VERSION ""

NS_ :

BS_:

BU_: AHLM ASBS CBC DIAGNOST DPDM DTCM ECM EHPS ESC ESL ESM ETM GPF HCP IC IRCM OCM ORC PTS RF_HUB SCCM SGW TBM TCM TPM

BO_ 943 IC_TripData_6: 8 IC
 SG_ B_Total_Dist_Kilometers : 47|24@0+ (0.1,0) [0|16093.3] "km"  ETM,SGW,TBM
 SG_ B_Total_Dist_Miles : 23|24@0+ (0.1,0) [0|9999.9] "Mile"  ETM,SGW,TBM

BO_ 958 IC_TripData_7: 8 IC
 SG_ Electric_Dist_Miles : 1|10@0+ (1,0) [0|999] "Mile"  CBC,ETM,SGW,TBM
 SG_ Hybrid_Dist_Miles : 17|10@0+ (1,0) [0|999] "Mile"  CBC,ETM,SGW,TBM

BO_ 959 IC_TripData_8: 8 IC
 SG_ Electric_Dist_Kilometers : 1|10@0+ (1,0) [0|999] "km"  CBC,ETM,SGW,TBM
 SG_ Hybrid_Dist_Kilometers : 17|10@0+ (1,0) [0|999] "km"  CBC,ETM,SGW,TBM

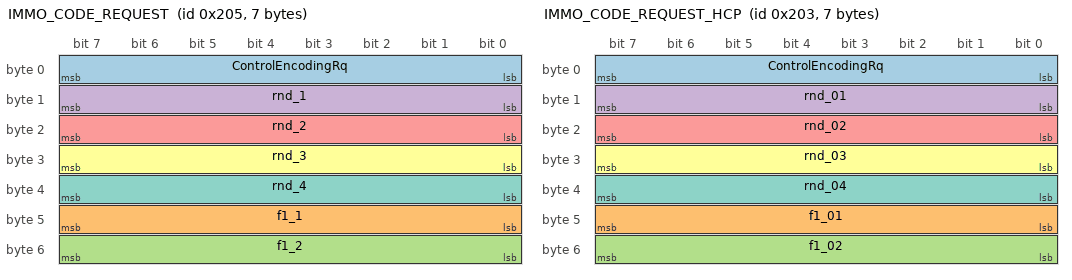
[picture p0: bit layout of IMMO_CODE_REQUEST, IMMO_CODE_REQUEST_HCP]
BO_ 517 IMMO_CODE_REQUEST: 7 ECM
 SG_ ControlEncodingRq : 0|8@1+ (1,0) [0|0] ""  CBC,SGW
 SG_ f1_1 : 40|8@1+ (1,0) [0|255] ""  CBC,SGW
 SG_ f1_2 : 48|8@1+ (1,0) [0|255] ""  CBC,SGW
 SG_ rnd_1 : 8|8@1+ (1,0) [0|255] ""  CBC,SGW
 SG_ rnd_2 : 16|8@1+ (1,0) [0|255] ""  CBC,SGW
 SG_ rnd_3 : 24|8@1+ (1,0) [0|255] ""  CBC,SGW
 SG_ rnd_4 : 32|8@1+ (1,0) [0|255] ""  CBC,SGW

BO_ 515 IMMO_CODE_REQUEST_HCP: 7 HCP
 SG_ ControlEncodingRq : 0|8@1+ (1,0) [0|0] ""  CBC,SGW
 SG_ f1_01 : 40|8@1+ (1,0) [0|255] ""  CBC,SGW
 SG_ f1_02 : 48|8@1+ (1,0) [0|255] ""  CBC,SGW
 SG_ rnd_01 : 8|8@1+ (1,0) [0|255] ""  CBC,SGW
 SG_ rnd_02 : 16|8@1+ (1,0) [0|255] ""  CBC,SGW
 SG_ rnd_03 : 24|8@1+ (1,0) [0|255] ""  CBC,SGW
 SG_ rnd_04 : 32|8@1+ (1,0) [0|255] ""  CBC,SGW

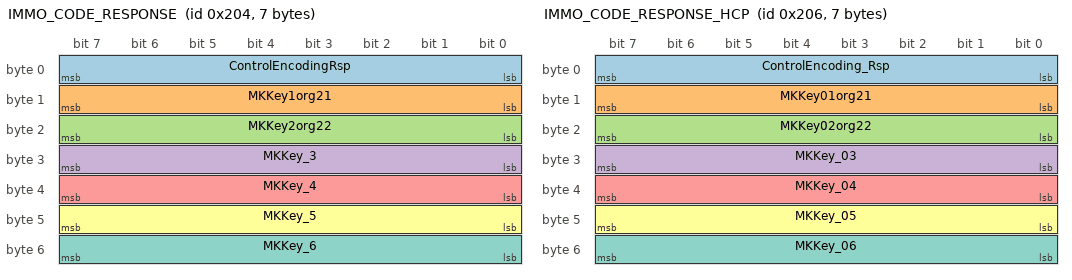
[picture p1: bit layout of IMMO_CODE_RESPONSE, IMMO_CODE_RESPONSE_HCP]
BO_ 516 IMMO_CODE_RESPONSE: 7 CBC
 SG_ ControlEncodingRsp : 0|8@1+ (1,0) [0|0] ""  ECM,SGW
 SG_ MKKey1org21 : 8|8@1+ (1,0) [0|255] ""  ECM,SGW
 SG_ MKKey2org22 : 16|8@1+ (1,0) [0|255] ""  ECM,SGW
 SG_ MKKey_3 : 24|8@1+ (1,0) [0|255] ""  ECM,SGW
 SG_ MKKey_4 : 32|8@1+ (1,0) [0|255] ""  ECM,SGW
 SG_ MKKey_5 : 40|8@1+ (1,0) [0|255] ""  ECM,SGW
 SG_ MKKey_6 : 48|8@1+ (1,0) [0|255] ""  ECM,SGW

BO_ 518 IMMO_CODE_RESPONSE_HCP: 7 CBC
 SG_ ControlEncoding_Rsp : 0|8@1+ (1,0) [0|0] ""  HCP,SGW
 SG_ MKKey01org21 : 8|8@1+ (1,0) [0|255] ""  HCP,SGW
 SG_ MKKey02org22 : 16|8@1+ (1,0) [0|255] ""  HCP,SGW
 SG_ MKKey_03 : 24|8@1+ (1,0) [0|255] ""  HCP,SGW
 SG_ MKKey_04 : 32|8@1+ (1,0) [0|255] ""  HCP,SGW
 SG_ MKKey_05 : 40|8@1+ (1,0) [0|255] ""  HCP,SGW
 SG_ MKKey_06 : 48|8@1+ (1,0) [0|255] ""  HCP,SGW

BO_ 973 IPC_LMPS: 8 IC
 SG_ ABS_IND_STAT : 8|2@1+ (1,0) [0|0] ""  CBC,SGW
 SG_ AWD_SERVICE_STAT : 44|2@1+ (1,0) [0|0] ""  CBC,SGW
 SG_ BATTERY_CHARGE_STAT : 2|2@1+ (1,0) [0|0] ""  CBC,SGW
 SG_ BRAKE_PAD_STAT : 38|2@1+ (1,0) [0|0] ""  CBC,SGW
 SG_ BRK_IND_STAT : 6|2@1+ (1,0) [0|0] ""  CBC,SGW
 SG_ CATALYST_TEMP_STAT : 48|2@1+ (1,0) [0|0] ""  CBC,SGW
 SG_ COOLENT_LEVEL_STAT : 54|2@1+ (1,0) [0|0] ""  CBC,SGW
 SG_ DAMPING_SYSTEM_STAT : 36|2@1+ (1,0) [0|0] ""  CBC,SGW
 SG_ DEF_STAT : 30|2@1+ (1,0) [0|0] ""  CBC,SGW
 SG_ ELECTRIC_WRENCH_STAT : 58|2@1+ (1,0) [0|0] ""  CBC,SGW
 SG_ ELEC_STAB_STAT : 16|2@1+ (1,0) [0|0] ""  CBC,SGW
 SG_ ENGINE_MIL_STAT : 10|2@1+ (1,0) [0|0] ""  CBC,SGW
 SG_ ENGINE_TEMP_STAT : 0|2@1+ (1,0) [0|0] ""  CBC,SGW
 SG_ EPB_WARN_STAT : 46|2@1+ (1,0) [0|0] ""  CBC,SGW
 SG_ EPS_STAT : 22|2@1+ (1,0) [0|0] ""  CBC,SGW
 SG_ ETC_CONTROL_STAT : 14|2@1+ (1,0) [0|0] ""  CBC,SGW
 SG_ FCW_SYSTEM_STAT : 24|2@1+ (1,0) [0|0] ""  CBC,SGW
 SG_ FOUR_WD_SERVICE_STAT : 40|2@1+ (1,0) [0|0] ""  CBC,SGW
 SG_ FUEL_CAP_STAT : 50|2@1+ (1,0) [0|0] ""  CBC,SGW
 SG_ LANE_SENSE_STAT : 42|2@1+ (1,0) [0|0] ""  CBC,SGW
 SG_ OIL_LEVEL_STAT : 56|2@1+ (1,0) [0|0] ""  CBC,SGW
 SG_ OIL_PRESSURE_STAT : 4|2@1+ (1,0) [0|0] ""  CBC,SGW
 SG_ OIL_TEMP_STAT : 32|2@1+ (1,0) [0|0] ""  CBC,SGW
 SG_ OVER_TEMP_STAT : 18|2@1+ (1,0) [0|0] ""  CBC,SGW
 SG_ SERVICE_ACC_STAT : 26|2@1+ (1,0) [0|0] ""  CBC,SGW
 SG_ SERVICE_STAT : 34|2@1+ (1,0) [0|0] ""  CBC,SGW
 SG_ STOP_START_STAT : 20|2@1+ (1,0) [0|0] ""  CBC,SGW
 SG_ TIRE_PRESSURE_STAT : 12|2@1+ (1,0) [0|0] ""  CBC,SGW
 SG_ TORQUE_STAT : 60|2@1+ (1,0) [0|0] ""  CBC,SGW
 SG_ WATER_IN_FUEL_STAT : 28|2@1+ (1,0) [0|0] ""  CBC,SGW
 SG_ WINDSHIELD_FLUID_STAT : 52|2@1+ (1,0) [0|0] ""  CBC,SGW

BO_ 868 MESS_TPM1: 8 TPM
 SG_ MESS_TPM1 : 7|64@0+ (1,0) [0|0] ""  SGW

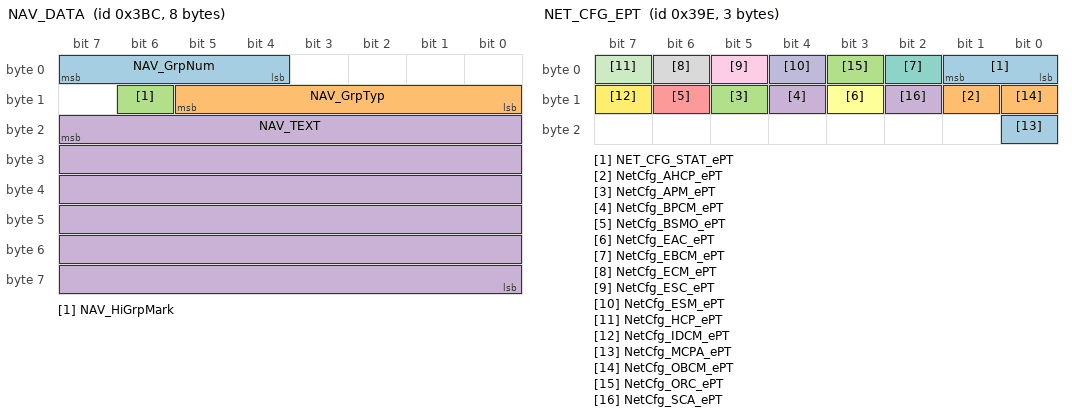
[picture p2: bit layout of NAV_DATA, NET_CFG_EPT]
BO_ 956 NAV_DATA: 8 CBC
 SG_ NAV_GrpNum : 4|4@1+ (1,1) [1|16] "Group"  IC,SGW
 SG_ NAV_GrpTyp : 8|6@1+ (1,0) [1|40] "Text"  IC,SGW
 SG_ NAV_HiGrpMark : 14|1@1+ (1,0) [0|0] ""  IC,SGW
 SG_ NAV_TEXT : 23|48@0+ (1,0) [0|0] ""  IC,SGW

BO_ 926 NET_CFG_EPT: 3 CBC
 SG_ NET_CFG_STAT_ePT : 0|2@1+ (1,0) [0|0] ""  ESC,ESM,HCP,ORC,RF_HUB,SGW
 SG_ NetCfg_AHCP_ePT : 9|1@1+ (1,0) [0|0] ""  ETM,RF_HUB,SGW,TBM
 SG_ NetCfg_APM_ePT : 13|1@1+ (1,0) [0|0] ""  RF_HUB,SGW
 SG_ NetCfg_BPCM_ePT : 12|1@1+ (1,0) [0|0] ""  ETM,RF_HUB,SGW,TBM
 SG_ NetCfg_BSMO_ePT : 14|1@1+ (1,0) [0|0] ""  ETM,RF_HUB,SGW,TBM
 SG_ NetCfg_EAC_ePT : 11|1@1+ (1,0) [0|0] ""  RF_HUB,SGW
 SG_ NetCfg_EBCM_ePT : 2|1@1+ (1,0) [0|0] ""  RF_HUB,SGW
 SG_ NetCfg_ECM_ePT : 6|1@1+ (1,0) [0|0] ""  ETM,RF_HUB,SGW,TBM
 SG_ NetCfg_ESC_ePT : 5|1@1+ (1,0) [0|0] ""  ETM,RF_HUB,SGW,TBM
 SG_ NetCfg_ESM_ePT : 4|1@1+ (1,0) [0|0] ""  ETM,RF_HUB,SGW,TBM
 SG_ NetCfg_HCP_ePT : 7|1@1+ (1,0) [0|0] ""  ETM,RF_HUB,SGW,TBM
 SG_ NetCfg_IDCM_ePT : 15|1@1+ (1,0) [0|0] ""  ETM,RF_HUB,SGW,TBM
 SG_ NetCfg_MCPA_ePT : 16|1@1+ (1,0) [0|0] ""  RF_HUB,SGW
 SG_ NetCfg_OBCM_ePT : 8|1@1+ (1,0) [0|0] ""  RF_HUB,SGW
 SG_ NetCfg_ORC_ePT : 3|1@1+ (1,0) [0|0] ""  ETM,RF_HUB,SGW,TBM
 SG_ NetCfg_SCA_ePT : 10|1@1+ (1,0) [0|0] ""  RF_HUB,SGW

BO_ 995 NET_CFG_INT: 8 CBC
 SG_ NET_CFG_STAT_INT : 0|2@1+ (1,0) [0|0] ""  IC,IRCM,RF_HUB,SGW
 SG_ NetCfg_AMP_I : 24|1@1+ (1,0) [0|0] ""  RF_HUB,SGW
 SG_ NetCfg_ANC_I : 39|1@1+ (1,0) [0|0] ""  RF_HUB,SGW
 SG_ NetCfg_BSM : 3|1@1+ (1,0) [0|0] ""  IC,IRCM,RF_HUB,SGW
 SG_ NetCfg_CBC_IN : 4|1@1+ (1,0) [0|0] ""  RF_HUB,SGW
 SG_ NetCfg_CLOCK : 21|1@1+ (1,0) [0|0] ""  ETM,RF_HUB,SGW,TBM
 SG_ NetCfg_CRSM : 30|1@1+ (1,0) [0|0] ""  RF_HUB,SGW
 SG_ NetCfg_CSWM : 5|1@1+ (1,0) [0|0] ""  RF_HUB,SGW
 SG_ NetCfg_CVPM : 32|1@1+ (1,0) [0|0] ""  RF_HUB,SGW
 SG_ NetCfg_DCM_DR : 6|1@1+ (1,0) [0|0] ""  RF_HUB,SGW
 SG_ NetCfg_DCM_PASS : 7|1@1+ (1,0) [0|0] ""  RF_HUB,SGW
 SG_ NetCfg_DCM_RL : 8|1@1+ (1,0) [0|0] ""  RF_HUB,SGW
 SG_ NetCfg_DCM_RR : 9|1@1+ (1,0) [0|0] ""  RF_HUB,SGW
 SG_ NetCfg_DCSD : 37|1@1+ (1,0) [0|0] ""  RF_HUB,SGW
 SG_ NetCfg_DTV : 19|1@1+ (1,0) [0|0] ""  RF_HUB,SGW
 SG_ NetCfg_DVD_CDM : 25|1@1+ (1,0) [0|0] ""  RF_HUB,SGW
 SG_ NetCfg_FSM : 16|1@1+ (1,0) [0|0] ""  RF_HUB,SGW
 SG_ NetCfg_HFM_CTM : 26|1@1+ (1,0) [0|0] ""  RF_HUB,SGW
 SG_ NetCfg_HVAC : 10|1@1+ (1,0) [0|0] ""  RF_HUB,SGW
 SG_ NetCfg_HVAC_R : 31|1@1+ (1,0) [0|0] ""  RF_HUB,SGW
 SG_ NetCfg_ICS_I : 27|1@1+ (1,0) [0|0] ""  RF_HUB,SGW
 SG_ NetCfg_ICS_R : 34|1@1+ (1,0) [0|0] ""  RF_HUB,SGW
 SG_ NetCfg_ITM : 23|1@1+ (1,0) [0|0] ""  RF_HUB,SGW
 SG_ NetCfg_MSM : 11|1@1+ (1,0) [0|0] ""  RF_HUB,SGW
 SG_ NetCfg_MSM_PASS : 35|1@1+ (1,0) [0|0] ""  RF_HUB,SGW
 SG_ NetCfg_PLG : 12|1@1+ (1,0) [0|0] ""  RF_HUB,SGW
 SG_ NetCfg_PSD_LT : 14|1@1+ (1,0) [0|0] ""  RF_HUB,SGW
 SG_ NetCfg_PSD_RT : 15|1@1+ (1,0) [0|0] ""  RF_HUB,SGW
 SG_ NetCfg_PSSM : 45|1@1+ (1,0) [0|0] ""  RF_HUB,SGW
 SG_ NetCfg_PTCM : 17|1@1+ (1,0) [0|0] ""  IC,RF_HUB,SGW
 SG_ NetCfg_RBC : 18|1@1+ (1,0) [0|0] ""  RF_HUB,SGW
 SG_ NetCfg_RBSS : 2|1@1+ (1,0) [0|0] ""  RF_HUB,SGW
 SG_ NetCfg_TBM : 38|1@1+ (1,0) [0|0] ""  IC,RF_HUB,SGW
 SG_ NetCfg_TGW : 20|1@1+ (1,0) [0|0] ""  RF_HUB,SGW
 SG_ NetCfg_TMM : 33|1@1+ (1,0) [0|0] ""  RF_HUB,SGW
 SG_ NetCfg_TTM : 47|1@1+ (1,0) [0|0] ""  RF_HUB,SGW
 SG_ NetCfg_UPFM : 46|1@1+ (1,0) [0|0] ""  RF_HUB,SGW
 SG_ NetCfg_VES2_I : 28|1@1+ (1,0) [0|0] ""  RF_HUB,SGW
 SG_ NetCfg_VES3_I : 29|1@1+ (1,0) [0|0] ""  RF_HUB,SGW
 SG_ NetCfg_VRM : 36|1@1+ (1,0) [0|0] ""  RF_HUB,SGW
 SG_ NetCfg_VSIM : 22|1@1+ (1,0) [0|0] ""  RF_HUB,SGW
 SG_ NetCfg_VTM : 13|1@1+ (1,0) [0|0] ""  RF_HUB,SGW

BO_ 996 NET_CFG_PT: 8 CBC
 SG_ NET_CFG_STAT_PT : 0|2@1+ (1,0) [0|0] ""  AHLM,ASBS,DPDM,DTCM,ECM,EHPS,ESC,ESL,ESM,HCP,IC,IRCM,OCM,ORC,PTS,RF_HUB,SCCM,SGW,TCM,TPM
 SG_ NetCfg_ACC : 2|1@1+ (1,0) [0|0] ""  RF_HUB,SGW
 SG_ NetCfg_ADCM : 3|1@1+ (1,0) [0|0] ""  RF_HUB,SGW
 SG_ NetCfg_AFLS : 28|1@1+ (1,0) [0|0] ""  RF_HUB,SGW
 SG_ NetCfg_AHLM : 4|1@1+ (1,0) [0|0] ""  AHLM,RF_HUB,SGW
 SG_ NetCfg_ANC : 39|1@1+ (1,0) [0|0] ""  RF_HUB,SGW
 SG_ NetCfg_ASBS : 35|1@1+ (1,0) [0|0] ""  IC,RF_HUB,SGW
 SG_ NetCfg_ASCM : 6|1@1+ (1,0) [0|0] ""  RF_HUB,SGW
 SG_ NetCfg_BSMO : 36|1@1+ (1,0) [0|0] ""  EHPS,IRCM,RF_HUB,SGW
 SG_ NetCfg_CBC_PT : 7|1@1+ (1,0) [0|0] ""  ECM,EHPS,IRCM,RF_HUB,SGW,TCM
 SG_ NetCfg_DASM : 16|1@1+ (1,0) [0|0] ""  ECM,ESC,IC,IRCM,RF_HUB,SCCM,SGW,TCM
 SG_ NetCfg_DPDM : 33|1@1+ (1,0) [0|0] ""  IRCM,RF_HUB,SGW
 SG_ NetCfg_DTCM : 8|1@1+ (1,0) [0|0] ""  ECM,ESC,HCP,IC,IRCM,PTS,RF_HUB,SGW,TCM
 SG_ NetCfg_ECM : 9|1@1+ (1,0) [0|0] ""  ECM,EHPS,IRCM,RF_HUB,SGW,TCM
 SG_ NetCfg_ELSD : 24|1@1+ (1,0) [0|0] ""  ESC,RF_HUB,SGW
 SG_ NetCfg_EPB : 13|1@1+ (1,0) [0|0] ""  ECM,RF_HUB,SGW
 SG_ NetCfg_EPPM : 18|1@1+ (1,0) [0|0] ""  RF_HUB,SGW
 SG_ NetCfg_EPS : 10|1@1+ (1,0) [0|0] ""  ECM,IC,ORC,RF_HUB,SGW
 SG_ NetCfg_ESC : 12|1@1+ (1,0) [0|0] ""  ECM,EHPS,IRCM,RF_HUB,SGW,TCM
 SG_ NetCfg_ESL : 37|1@1+ (1,0) [0|0] ""  RF_HUB,SGW
 SG_ NetCfg_ESM : 11|1@1+ (1,0) [0|0] ""  ECM,RF_HUB,SGW
 SG_ NetCfg_FDCM : 17|1@1+ (1,0) [0|0] ""  RF_HUB,SGW
 SG_ NetCfg_GPF : 58|1@1+ (1,0) [0|0] ""  RF_HUB,SGW
 SG_ NetCfg_HCP : 38|1@1+ (1,0) [0|0] ""  EHPS,IRCM,RF_HUB,SGW
 SG_ NetCfg_HaLF : 31|1@1+ (1,0) [0|0] ""  RF_HUB,SGW
 SG_ NetCfg_IC : 15|1@1+ (1,0) [0|0] ""  ECM,EHPS,IRCM,RF_HUB,SGW,TCM
 SG_ NetCfg_ITBM : 29|1@1+ (1,0) [0|0] ""  RF_HUB,SGW
 SG_ NetCfg_OCM : 30|1@1+ (1,0) [0|0] ""  ORC,RF_HUB,SGW
 SG_ NetCfg_ORC : 19|1@1+ (1,0) [0|0] ""  ECM,IRCM,RF_HUB,SGW
 SG_ NetCfg_PASS_PT : 27|1@1+ (1,0) [0|0] ""  RF_HUB,SGW
 SG_ NetCfg_PTS : 20|1@1+ (1,0) [0|0] ""  IC,RF_HUB,SGW
 SG_ NetCfg_RF_HUB : 14|1@1+ (1,0) [0|0] ""  ECM,IRCM,RF_HUB,SGW
 SG_ NetCfg_SCCM : 23|1@1+ (1,0) [0|0] ""  ECM,EHPS,IRCM,RF_HUB,SGW
 SG_ NetCfg_SGW : 34|1@1+ (1,0) [0|0] ""  RF_HUB,SGW
 SG_ NetCfg_TCM : 25|1@1+ (1,0) [0|0] ""  ECM,ESM,IRCM,ORC,RF_HUB,SGW
 SG_ NetCfg_TIM : 60|1@1+ (1,0) [0|0] ""  RF_HUB,SGW
 SG_ NetCfg_TPM : 26|1@1+ (1,0) [0|0] ""  IC,RF_HUB,SGW,TPM
 SG_ NetCfg_TTPM : 59|1@1+ (1,0) [0|0] ""  RF_HUB,SGW
 SG_ NetCfg_VSIM_C : 5|1@1+ (1,0) [0|0] ""  ECM,RF_HUB,SGW

BO_ 1025 NM_CBC: 8 CBC
 SG_ Awake_Diag_Actv m15 : 33|1@1+ (1,0) [0|0] ""  CBC,EHPS,ESC,ESL,ESM,HCP,IC,RF_HUB,SCCM,SGW,TPM
 SG_ Awake_NwSt m15 : 32|1@1+ (1,0) [0|0] ""  CBC,EHPS,ESC,ESL,ESM,HCP,IC,RF_HUB,SCCM,SGW,TPM
 SG_ NM_Mode : 0|8@1+ (1,0) [0|0] ""  CBC,EHPS,ESC,ESL,ESM,HCP,IC,RF_HUB,SCCM,SGW,TPM
 SG_ NM_Sleep_Ack : 22|1@1+ (1,0) [0|0] ""  CBC,EHPS,ESC,ESL,ESM,HCP,IC,RF_HUB,SCCM,SGW,TPM
 SG_ NM_Sleep_Ind : 23|1@1+ (1,0) [0|0] ""  CBC,EHPS,ESC,ESL,ESM,HCP,IC,RF_HUB,SCCM,SGW,TPM
 SG_ NM_Successor : 8|8@1+ (1,0) [0|63] ""  CBC,EHPS,ESC,ESL,ESM,HCP,IC,RF_HUB,SCCM,SGW,TPM
 SG_ NM_Ud_Launch : 16|6@1+ (1,0) [0|0] ""  CBC,EHPS,ESC,ESL,ESM,HCP,IC,RF_HUB,SCCM,SGW,TPM
 SG_ NM_Ud_Srv M : 24|8@1+ (1,0) [0|0] ""  CBC,EHPS,ESC,ESL,ESM,HCP,IC,RF_HUB,SCCM,SGW,TPM
 SG_ Nw_Id : 56|8@1+ (1,0) [0|0] ""  CBC,EHPS,ESC,ESL,ESM,HCP,IC,RF_HUB,SCCM,SGW,TPM
 SG_ WakeupCnt m2 : 40|8@1+ (1,0) [0|254] ""  CBC,EHPS,ESC,ESL,ESM,HCP,IC,RF_HUB,SCCM,SGW,TPM
 SG_ WakeupRsn_CBC m2 : 32|8@1+ (1,0) [0|0] ""  CBC,EHPS,ESC,ESL,ESM,HCP,IC,RF_HUB,SCCM,SGW,TPM

BO_ 1050 NM_EPS: 8 EHPS
 SG_ Awake_Diag_Actv m15 : 33|1@1+ (1,0) [0|0] ""  CBC,EHPS,ESC,ESL,ESM,HCP,IC,RF_HUB,SCCM,SGW,TPM
 SG_ Awake_EngRPM_high m15 : 36|1@1+ (1,0) [0|0] ""  CBC,EHPS,ESC,ESL,ESM,HCP,IC,RF_HUB,SCCM,SGW,TPM
 SG_ Awake_IgnHigh m15 : 37|1@1+ (1,0) [0|0] ""  CBC,EHPS,ESC,ESL,ESM,HCP,IC,RF_HUB,SCCM,SGW,TPM
 SG_ Awake_NwSt m15 : 32|1@1+ (1,0) [0|0] ""  CBC,EHPS,ESC,ESL,ESM,HCP,IC,RF_HUB,SCCM,SGW,TPM
 SG_ Awake_Rampout m15 : 34|1@1+ (1,0) [0|0] ""  CBC,EHPS,ESC,ESL,ESM,HCP,IC,RF_HUB,SCCM,SGW,TPM
 SG_ Awake_VSS_high m15 : 35|1@1+ (1,0) [0|0] ""  CBC,EHPS,ESC,ESL,ESM,HCP,IC,RF_HUB,SCCM,SGW,TPM
 SG_ NM_Mode : 0|8@1+ (1,0) [0|0] ""  CBC,EHPS,ESC,ESL,ESM,HCP,IC,RF_HUB,SCCM,SGW,TPM
 SG_ NM_Sleep_Ack : 22|1@1+ (1,0) [0|0] ""  CBC,EHPS,ESC,ESL,ESM,HCP,IC,RF_HUB,SCCM,SGW,TPM
 SG_ NM_Sleep_Ind : 23|1@1+ (1,0) [0|0] ""  CBC,EHPS,ESC,ESL,ESM,HCP,IC,RF_HUB,SCCM,SGW,TPM
 SG_ NM_Successor : 8|8@1+ (1,0) [0|63] ""  CBC,EHPS,ESC,ESL,ESM,HCP,IC,RF_HUB,SCCM,SGW,TPM
 SG_ NM_Ud_Launch : 16|6@1+ (1,0) [0|0] ""  CBC,EHPS,ESC,ESL,ESM,HCP,IC,RF_HUB,SCCM,SGW,TPM
 SG_ NM_Ud_Srv M : 24|8@1+ (1,0) [0|0] ""  CBC,EHPS,ESC,ESL,ESM,HCP,IC,RF_HUB,SCCM,SGW,TPM
 SG_ Nw_Id : 56|8@1+ (1,0) [0|0] ""  CBC,EHPS,ESC,ESL,ESM,HCP,IC,RF_HUB,SCCM,SGW,TPM
 SG_ WakeupCnt m2 : 40|8@1+ (1,0) [0|254] ""  CBC,EHPS,ESC,ESL,ESM,HCP,IC,RF_HUB,SCCM,SGW,TPM
 SG_ WakeupRsn_EPS m2 : 32|8@1+ (1,0) [0|0] ""  CBC,EHPS,ESC,ESL,ESM,HCP,IC,RF_HUB,SCCM,SGW,TPM

BO_ 1031 NM_ESC: 8 ESC
 SG_ Awake_Brake_Pedal_Pressed m15 : 34|1@1+ (1,0) [0|0] ""  CBC,EHPS,ESC,ESL,ESM,HCP,IC,RF_HUB,SCCM,SGW,TPM
 SG_ Awake_Diag_Actv m15 : 33|1@1+ (1,0) [0|0] ""  CBC,EHPS,ESC,ESL,ESM,HCP,IC,RF_HUB,SCCM,SGW,TPM
 SG_ Awake_EPB_Switch_Wakeup m15 : 36|1@1+ (1,0) [0|0] ""  CBC,EHPS,ESC,ESL,ESM,HCP,IC,RF_HUB,SCCM,SGW,TPM
 SG_ Awake_Hardwire_Ignition m15 : 37|1@1+ (1,0) [0|0] ""  CBC,EHPS,ESC,ESL,ESM,HCP,IC,RF_HUB,SCCM,SGW,TPM
 SG_ Awake_NwSt m15 : 32|1@1+ (1,0) [0|0] ""  CBC,EHPS,ESC,ESL,ESM,HCP,IC,RF_HUB,SCCM,SGW,TPM
 SG_ Awake_Vehicle_Speed m15 : 35|1@1+ (1,0) [0|0] ""  CBC,EHPS,ESC,ESL,ESM,HCP,IC,RF_HUB,SCCM,SGW,TPM
 SG_ NM_Mode : 0|8@1+ (1,0) [0|0] ""  CBC,EHPS,ESC,ESL,ESM,HCP,IC,RF_HUB,SCCM,SGW,TPM
 SG_ NM_Sleep_Ack : 22|1@1+ (1,0) [0|0] ""  CBC,EHPS,ESC,ESL,ESM,HCP,IC,RF_HUB,SCCM,SGW,TPM
 SG_ NM_Sleep_Ind : 23|1@1+ (1,0) [0|0] ""  CBC,EHPS,ESC,ESL,ESM,HCP,IC,RF_HUB,SCCM,SGW,TPM
 SG_ NM_Successor : 8|8@1+ (1,0) [0|63] ""  CBC,EHPS,ESC,ESL,ESM,HCP,IC,RF_HUB,SCCM,SGW,TPM
 SG_ NM_Ud_Launch : 16|6@1+ (1,0) [0|0] ""  CBC,EHPS,ESC,ESL,ESM,HCP,IC,RF_HUB,SCCM,SGW,TPM
 SG_ NM_Ud_Srv M : 24|8@1+ (1,0) [0|0] ""  CBC,EHPS,ESC,ESL,ESM,HCP,IC,RF_HUB,SCCM,SGW,TPM
 SG_ Nw_Id : 56|8@1+ (1,0) [0|0] ""  CBC,EHPS,ESC,ESL,ESM,HCP,IC,RF_HUB,SCCM,SGW,TPM
 SG_ WakeupCnt m2 : 40|8@1+ (1,0) [0|254] ""  CBC,EHPS,ESC,ESL,ESM,HCP,IC,RF_HUB,SCCM,SGW,TPM
 SG_ WakeupRsn_ESC m2 : 32|8@1+ (1,0) [0|0] ""  CBC,EHPS,ESC,ESL,ESM,HCP,IC,RF_HUB,SCCM,SGW,TPM

BO_ 1032 NM_ESL: 8 ESL
 SG_ Awake_Diag_Actv m15 : 33|1@1+ (1,0) [0|0] ""  CBC,EHPS,ESC,ESL,ESM,HCP,IC,RF_HUB,SCCM,SGW,TPM
 SG_ Awake_Ign_RunStart m15 : 34|1@1+ (1,0) [0|0] ""  CBC,EHPS,ESC,ESL,ESM,HCP,IC,RF_HUB,SCCM,SGW,TPM
 SG_ Awake_Lock_Unlock m15 : 35|1@1+ (1,0) [0|0] ""  CBC,EHPS,ESC,ESL,ESM,HCP,IC,RF_HUB,SCCM,SGW,TPM
 SG_ Awake_NwSt m15 : 32|1@1+ (1,0) [0|0] ""  CBC,EHPS,ESC,ESL,ESM,HCP,IC,RF_HUB,SCCM,SGW,TPM
 SG_ NM_Mode : 0|8@1+ (1,0) [0|0] ""  CBC,EHPS,ESC,ESL,ESM,HCP,IC,RF_HUB,SCCM,SGW,TPM
 SG_ NM_Sleep_Ack : 22|1@1+ (1,0) [0|0] ""  CBC,EHPS,ESC,ESL,ESM,HCP,IC,RF_HUB,SCCM,SGW,TPM
 SG_ NM_Sleep_Ind : 23|1@1+ (1,0) [0|0] ""  CBC,EHPS,ESC,ESL,ESM,HCP,IC,RF_HUB,SCCM,SGW,TPM
 SG_ NM_Successor : 8|8@1+ (1,0) [0|63] ""  CBC,EHPS,ESC,ESL,ESM,HCP,IC,RF_HUB,SCCM,SGW,TPM
 SG_ NM_Ud_Launch : 16|6@1+ (1,0) [0|0] ""  CBC,EHPS,ESC,ESL,ESM,HCP,IC,RF_HUB,SCCM,SGW,TPM
 SG_ NM_Ud_Srv M : 24|8@1+ (1,0) [0|0] ""  CBC,EHPS,ESC,ESL,ESM,HCP,IC,RF_HUB,SCCM,SGW,TPM
 SG_ Nw_Id : 56|8@1+ (1,0) [0|0] ""  CBC,EHPS,ESC,ESL,ESM,HCP,IC,RF_HUB,SCCM,SGW,TPM
 SG_ WakeupCnt m2 : 40|8@1+ (1,0) [0|254] ""  CBC,EHPS,ESC,ESL,ESM,HCP,IC,RF_HUB,SCCM,SGW,TPM
 SG_ WakeupRsn_ESL m2 : 32|8@1+ (1,0) [0|0] ""  CBC,EHPS,ESC,ESL,ESM,HCP,IC,RF_HUB,SCCM,SGW,TPM

BO_ 1082 NM_HCP: 8 HCP
 SG_ Awake_Chg_ST m15 : 35|1@1+ (1,0) [0|0] ""  CBC,EHPS,ESC,ESL,ESM,HCP,IC,RF_HUB,SCCM,SGW,TPM
 SG_ Awake_Diag_Actv m15 : 33|1@1+ (1,0) [0|0] ""  CBC,EHPS,ESC,ESL,ESM,HCP,IC,RF_HUB,SCCM,SGW,TPM
 SG_ Awake_NwSt m15 : 32|1@1+ (1,0) [0|0] ""  CBC,EHPS,ESC,ESL,ESM,HCP,IC,RF_HUB,SCCM,SGW,TPM
 SG_ Awake_OBCM_WU m15 : 34|1@1+ (1,0) [0|0] ""  CBC,EHPS,ESC,ESL,ESM,HCP,IC,RF_HUB,SCCM,SGW,TPM
 SG_ NM_Mode : 0|8@1+ (1,0) [0|0] ""  CBC,EHPS,ESC,ESL,ESM,HCP,IC,RF_HUB,SCCM,SGW,TPM
 SG_ NM_Sleep_Ack : 22|1@1+ (1,0) [0|0] ""  CBC,EHPS,ESC,ESL,ESM,HCP,IC,RF_HUB,SCCM,SGW,TPM
 SG_ NM_Sleep_Ind : 23|1@1+ (1,0) [0|0] ""  CBC,EHPS,ESC,ESL,ESM,HCP,IC,RF_HUB,SCCM,SGW,TPM
 SG_ NM_Successor : 8|8@1+ (1,0) [0|63] ""  CBC,EHPS,ESC,ESL,ESM,HCP,IC,RF_HUB,SCCM,SGW,TPM
 SG_ NM_Ud_Launch : 16|6@1+ (1,0) [0|0] ""  CBC,EHPS,ESC,ESL,ESM,HCP,IC,RF_HUB,SCCM,SGW,TPM
 SG_ NM_Ud_Srv M : 24|8@1+ (1,0) [0|0] ""  CBC,EHPS,ESC,ESL,ESM,HCP,IC,RF_HUB,SCCM,SGW,TPM
 SG_ Nw_Id : 56|8@1+ (1,0) [0|0] ""  CBC,EHPS,ESC,ESL,ESM,HCP,IC,RF_HUB,SCCM,SGW,TPM
 SG_ WakeupCnt m2 : 40|8@1+ (1,0) [0|254] ""  CBC,EHPS,ESC,ESL,ESM,HCP,IC,RF_HUB,SCCM,SGW,TPM
 SG_ WakeupRsn_HCP m2 : 32|8@1+ (1,0) [0|0] ""  CBC,EHPS,ESC,ESL,ESM,HCP,IC,RF_HUB,SCCM,SGW,TPM

CM_ SG_ 943 B_Total_Dist_Kilometers "Trip B total distance in kilometers";
CM_ SG_ 943 B_Total_Dist_Miles "Trip B total distance in US miles";
CM_ SG_ 958 Electric_Dist_Miles "Electric distance traveled during IgnCycle in US miles";
CM_ SG_ 958 Hybrid_Dist_Miles "Hybrid distance traveled during IgnCycle in US miles";
CM_ SG_ 959 Electric_Dist_Kilometers "Electric distance traveled during IgnCycle in kilometers";
CM_ SG_ 959 Hybrid_Dist_Kilometers "Hybrid distance traveled during IgnCycle in kilometers";
CM_ SG_ 517 ControlEncodingRq "Control encoding - request";
CM_ SG_ 517 f1_1 "F code 1_1";
CM_ SG_ 517 f1_2 "F code 1_2";
CM_ SG_ 517 rnd_1 "Random number 1";
CM_ SG_ 517 rnd_2 "Random number 2";
CM_ SG_ 517 rnd_3 "Random number 3";
CM_ SG_ 517 rnd_4 "Random number 4";
CM_ SG_ 515 ControlEncodingRq "Control encoding - request";
CM_ SG_ 515 f1_01 "F code 1_1";
CM_ SG_ 515 f1_02 "F code 1_2";
CM_ SG_ 515 rnd_01 "Random number 1";
CM_ SG_ 515 rnd_02 "Random number 2";
CM_ SG_ 515 rnd_03 "Random number 3";
CM_ SG_ 515 rnd_04 "Random number 4";
CM_ SG_ 516 ControlEncodingRsp "Control encoding - response";
CM_ SG_ 516 MKKey1org21 "Mini kript key 1 or G2_1";
CM_ SG_ 516 MKKey2org22 "Mini kript key 2 or G2_2";
CM_ SG_ 516 MKKey_3 "Mini kript key 3";
CM_ SG_ 516 MKKey_4 "Mini kript key 4";
CM_ SG_ 516 MKKey_5 "Mini kript key 5";
CM_ SG_ 516 MKKey_6 "Mini kript key 6";
CM_ SG_ 518 ControlEncoding_Rsp "Control encoding - response";
CM_ SG_ 518 MKKey01org21 "Mini kript key 1 or G2_1";
CM_ SG_ 518 MKKey02org22 "Mini kript key 2 or G2_2";
CM_ SG_ 518 MKKey_03 "Mini kript key 3";
CM_ SG_ 518 MKKey_04 "Mini kript key 4";
CM_ SG_ 518 MKKey_05 "Mini kript key 5";
CM_ SG_ 518 MKKey_06 "Mini kript key 6";
CM_ SG_ 973 ABS_IND_STAT "ABS indicator status";
CM_ SG_ 973 AWD_SERVICE_STAT "AWD service indicator status";
CM_ SG_ 973 BATTERY_CHARGE_STAT "Battery charge indicator status";
CM_ SG_ 973 BRAKE_PAD_STAT "Brake pad indicator status";
CM_ SG_ 973 BRK_IND_STAT "Brake indicator status";
CM_ SG_ 973 CATALYST_TEMP_STAT "Catalyst Overtemp";
CM_ SG_ 973 COOLENT_LEVEL_STAT "Low Coolent Level";
CM_ SG_ 973 DAMPING_SYSTEM_STAT "Damping system indicator status";
CM_ SG_ 973 DEF_STAT "DEF indicator status";
CM_ SG_ 973 ELECTRIC_WRENCH_STAT "Electric Wrench";
CM_ SG_ 973 ELEC_STAB_STAT "Electronic stability indicator status";
CM_ SG_ 973 ENGINE_MIL_STAT "Engine MIL indicator status";
CM_ SG_ 973 ENGINE_TEMP_STAT "Engine temperature indicator status";
CM_ SG_ 973 EPB_WARN_STAT "EPB warn indicator status";
CM_ SG_ 973 EPS_STAT "EPS indicator status";
CM_ SG_ 973 ETC_CONTROL_STAT "ETC control indicator status";
CM_ SG_ 973 FCW_SYSTEM_STAT "FCW system indicator status";
CM_ SG_ 973 FOUR_WD_SERVICE_STAT "Service indicator status";
CM_ SG_ 973 FUEL_CAP_STAT "Fuel Cap Unfastened";
CM_ SG_ 973 LANE_SENSE_STAT "Lane sense indicator status";
CM_ SG_ 973 OIL_LEVEL_STAT "Oil Level";
CM_ SG_ 973 OIL_PRESSURE_STAT "Oil pressure indicator status";
CM_ SG_ 973 OIL_TEMP_STAT "Oil temperature indicator status";
CM_ SG_ 973 OVER_TEMP_STAT "Over temperature indicator status";
CM_ SG_ 973 SERVICE_ACC_STAT "Service ACC indicator status";
CM_ SG_ 973 SERVICE_STAT "Service indicator status";
CM_ SG_ 973 STOP_START_STAT "Stop start indicator status";
CM_ SG_ 973 TIRE_PRESSURE_STAT "Tire pressure indicator status";
CM_ SG_ 973 TORQUE_STAT "Torque Limited";
CM_ SG_ 973 WATER_IN_FUEL_STAT "Water in fuel indicator status";
CM_ SG_ 973 WINDSHIELD_FLUID_STAT "Windshield Water Fluid";
CM_ SG_ 868 MESS_TPM1 "Measurement data";
CM_ SG_ 956 NAV_GrpNum "NAV group number";
CM_ SG_ 956 NAV_GrpTyp "NAV group type";
CM_ SG_ 956 NAV_HiGrpMark "NAV high group mark";
CM_ SG_ 956 NAV_TEXT "NAV data field";
CM_ SG_ 926 NET_CFG_STAT_ePT "Network configuration status.";
CM_ SG_ 926 NetCfg_AHCP_ePT "Transmission Control Processor (1=present)";
CM_ SG_ 926 NetCfg_APM_ePT "Auxiliary Power Module (1=present)";
CM_ SG_ 926 NetCfg_BPCM_ePT "Battery Pack Control Module (1=present)";
CM_ SG_ 926 NetCfg_BSMO_ePT "Brake System Module - OBD (1=present)";
CM_ SG_ 926 NetCfg_EAC_ePT "Electric AC Compressor (1=present)";
CM_ SG_ 926 NetCfg_EBCM_ePT "Electronic Boost Control Module (1=present)";
CM_ SG_ 926 NetCfg_ECM_ePT "Engine Controller Module (1=present)";
CM_ SG_ 926 NetCfg_ESC_ePT "Electronic Stability Control (1=present)";
CM_ SG_ 926 NetCfg_ESM_ePT "Electronic Shifter Module (1=present)";
CM_ SG_ 926 NetCfg_HCP_ePT "Hybrid Control Processor (1=present)";
CM_ SG_ 926 NetCfg_IDCM_ePT "Integrated Dual Charge Module Net Config (1=present)";
CM_ SG_ 926 NetCfg_MCPA_ePT "Motor Control Processor A (1=present)";
CM_ SG_ 926 NetCfg_OBCM_ePT "On Board Charging Module. 1=present";
CM_ SG_ 926 NetCfg_ORC_ePT "Occupant Restraint Controller (1=present)";
CM_ SG_ 926 NetCfg_SCA_ePT "Smart Cluch Actuator (1=present)";
CM_ SG_ 995 NET_CFG_STAT_INT "Network configuration status";
CM_ SG_ 995 NetCfg_AMP_I "CAN I Amplifier Module (1=present)";
CM_ SG_ 995 NetCfg_ANC_I "Active Noise Cancellation interior (1=present)";
CM_ SG_ 995 NetCfg_BSM "Blind-Spot Module (1=present)";
CM_ SG_ 995 NetCfg_CBC_IN "Common Body Controller Int Bus (1=present)";
CM_ SG_ 995 NetCfg_CLOCK "CAN I Clock Module (1=present)";
CM_ SG_ 995 NetCfg_CRSM "CAN I Comfort Rear Seat Module (1=present)";
CM_ SG_ 995 NetCfg_CSWM "Comfot Seats and Wheel Module (1=present)";
CM_ SG_ 995 NetCfg_CVPM "CAN I Central Vision Processing Module (1=present)";
CM_ SG_ 995 NetCfg_DCM_DR "Door Control Module Driver (1=present)";
CM_ SG_ 995 NetCfg_DCM_PASS "Door Control Module Passenger (1=present)";
CM_ SG_ 995 NetCfg_DCM_RL "Door Control Module Rear Left (1=present)";
CM_ SG_ 995 NetCfg_DCM_RR "Door Control Module Rear Right (1=present)";
CM_ SG_ 995 NetCfg_DCSD "Disassociated Center Stack Display Module (1=present)";
CM_ SG_ 995 NetCfg_DTV "Digital TV Module (1=present)";
CM_ SG_ 995 NetCfg_DVD_CDM "CAN I in-dash disc player module (1=present)";
CM_ SG_ 995 NetCfg_FSM "Folding Seat Module (1=present)";
CM_ SG_ 995 NetCfg_HFM_CTM "Convergence Telematics Module (1=present)";
CM_ SG_ 995 NetCfg_HVAC "Heating Ventilation Air Conditioning (1=present)";
CM_ SG_ 995 NetCfg_HVAC_R "CAN I Rear Heating Ventilation Air Conditioning (1=present)";
CM_ SG_ 995 NetCfg_ICS_I "CAN I Integrated Center Stack Module (1=present)";
CM_ SG_ 995 NetCfg_ICS_R "CAN I Integrated rear Center Stack Module (1=present)";
CM_ SG_ 995 NetCfg_ITM "Intrusion module (1=present)";
CM_ SG_ 995 NetCfg_MSM "Memory Seat Module (1=present)";
CM_ SG_ 995 NetCfg_MSM_PASS "CAN I Memory Seat Module Passenger (1=present)";
CM_ SG_ 995 NetCfg_PLG "Power Liftgate Module (1=present)";
CM_ SG_ 995 NetCfg_PSD_LT "Power Sliding Door Left Module (1=present)";
CM_ SG_ 995 NetCfg_PSD_RT "Power Sliding Door Right Module (1=present)";
CM_ SG_ 995 NetCfg_PSSM "NetCfg PSSM";
CM_ SG_ 995 NetCfg_PTCM "Power Top Control Module (1=present)";
CM_ SG_ 995 NetCfg_RBC "Rear Body Controller Module (1=present)";
CM_ SG_ 995 NetCfg_RBSS "Right Blind-Spot Module (1=present)";
CM_ SG_ 995 NetCfg_TBM "Telematics Box Module (1=present)";
CM_ SG_ 995 NetCfg_TGW "Telematics gateway (1=present)";
CM_ SG_ 995 NetCfg_TMM "CAN I Track Mapping Module (1=present)";
CM_ SG_ 995 NetCfg_TTM "0= Not Present;  1= Present";
CM_ SG_ 995 NetCfg_UPFM "CAN I Upfitter Module (1=present)";
CM_ SG_ 995 NetCfg_VES2_I "CAN I Video Ent. System screen 2 Module (1=present)";
CM_ SG_ 995 NetCfg_VES3_I "CAN I Video Ent. System screen 1 Module (1=present)";
CM_ SG_ 995 NetCfg_VRM "Video Routing Module (1=present)";
CM_ SG_ 995 NetCfg_VSIM "Vehicle System Interface Module (1=present)";
CM_ SG_ 995 NetCfg_VTM "Vehicle theft / tax module (1=present)";
CM_ SG_ 996 NET_CFG_STAT_PT "Network configuration status";
CM_ SG_ 996 NetCfg_ACC "Active Cruise Control (1=present)";
CM_ SG_ 996 NetCfg_ADCM "Active Damping Control Module (1=present)";
CM_ SG_ 996 NetCfg_AFLS "Advanced Front Lighting System (1=present)";
CM_ SG_ 996 NetCfg_AHLM "Automatic Headlamp Leveling Module (1=present)";
CM_ SG_ 996 NetCfg_ANC "Active Noise Cancellation (1=present)";
CM_ SG_ 996 NetCfg_ASBS "Automatic Sway Bar System Module (Present = 1, Not Present = 0)";
CM_ SG_ 996 NetCfg_ASCM "Air Suspension Control Module (1=present)";
CM_ SG_ 996 NetCfg_BSMO "Brake System Module - OBD (1=present)";
CM_ SG_ 996 NetCfg_CBC_PT "Common Body Controller PT Bus (1=present)";
CM_ SG_ 996 NetCfg_DASM "Driver Assistance System Module (1=present)";
CM_ SG_ 996 NetCfg_DPDM "Driver Presence Detection Module (1=present)";
CM_ SG_ 996 NetCfg_DTCM "Drivetrain Control Module (1=present)";
CM_ SG_ 996 NetCfg_ECM "Engine Control Module (1=present)";
CM_ SG_ 996 NetCfg_ELSD "Electric Limited Slip Differential (1=present)";
CM_ SG_ 996 NetCfg_EPB "Electric Park Brake Module (1=present)";
CM_ SG_ 996 NetCfg_EPPM "Elect. Pedestrian protection module (1=present)";
CM_ SG_ 996 NetCfg_EPS "Electric Power Steering (1=present)";
CM_ SG_ 996 NetCfg_ESC "Electronic Stability Module / Anti-Lock Brake (1=present)";
CM_ SG_ 996 NetCfg_ESL "Electric Steering Lock (1=present)";
CM_ SG_ 996 NetCfg_ESM "Electronic Shift Module (1=present)";
CM_ SG_ 996 NetCfg_FDCM "Final Drive Control Module (1=present)";
CM_ SG_ 996 NetCfg_GPF "Gasoline Particulate Filter Net Config, Present=1";
CM_ SG_ 996 NetCfg_HCP "Hybrid Control Processor (1=present)";
CM_ SG_ 996 NetCfg_HaLF "Haptic Lane Feedback module (1=present)";
CM_ SG_ 996 NetCfg_IC "Instrument Cluster (1=present)";
CM_ SG_ 996 NetCfg_ITBM "Integrated Trailer Brake Module (1=present)";
CM_ SG_ 996 NetCfg_OCM "Occupant Classification Module (1=present)";
CM_ SG_ 996 NetCfg_ORC "Occupant Restraint Controller (1=present)";
CM_ SG_ 996 NetCfg_PASS_PT "Personal Assistant Safety System Module PT Bus (1=present)";
CM_ SG_ 996 NetCfg_PTS "Parktronics System (1=present)";
CM_ SG_ 996 NetCfg_RF_HUB "RF Hub Node (1=present)";
CM_ SG_ 996 NetCfg_SCCM "Steering Column Control Module (1=present)";
CM_ SG_ 996 NetCfg_SGW "Security GateWay (1=present)";
CM_ SG_ 996 NetCfg_TCM "Automatic Transmission Controller (1=present)";
CM_ SG_ 996 NetCfg_TIM "TIM (1=present)";
CM_ SG_ 996 NetCfg_TPM "Tire Pressure Monitor (1=present)";
CM_ SG_ 996 NetCfg_TTPM "TTPM (1=present)";
CM_ SG_ 996 NetCfg_VSIM_C "Vehicle System Interface Module (1=present)";
CM_ SG_ 1025 Awake_Diag_Actv "Stay awake for diagnostics active; True = [1]";
CM_ SG_ 1025 Awake_NwSt "Stay awake for network startup; True = [1]";
CM_ SG_ 1025 NM_Mode "Network management mode";
CM_ SG_ 1025 NM_Sleep_Ack "Network management sleep acknowledge; True = [1]";
CM_ SG_ 1025 NM_Sleep_Ind "Network management sleep indication; True = [1]";
CM_ SG_ 1025 NM_Successor "Network management logical successor";
CM_ SG_ 1025 NM_Ud_Launch "Network management userdata launch type";
CM_ SG_ 1025 NM_Ud_Srv "Network management userdata service no.";
CM_ SG_ 1025 Nw_Id "Network identification no.";
CM_ SG_ 1025 WakeupCnt "Counter for module wakeup states during network sleep";
CM_ SG_ 1025 WakeupRsn_CBC "Wakeup reason CBC";
CM_ SG_ 1050 Awake_Diag_Actv "Stay awake for diagnostics active; True = [1]";
CM_ SG_ 1050 Awake_EngRPM_high "Stay awake - assist active due to engine RPM high; True = 1";
CM_ SG_ 1050 Awake_IgnHigh "Stay awake - ignition high; True = 1";
CM_ SG_ 1050 Awake_NwSt "Stay awake for network startup; True = [1]";
CM_ SG_ 1050 Awake_Rampout "Stay awake - ramping assist off; True = 1";
CM_ SG_ 1050 Awake_VSS_high "Stay awake - assist active due to vehicle speed high; True = 1";
CM_ SG_ 1050 NM_Mode "Network management mode";
CM_ SG_ 1050 NM_Sleep_Ack "Network management sleep acknowledge; True = [1]";
CM_ SG_ 1050 NM_Sleep_Ind "Network management sleep indication; True = [1]";
CM_ SG_ 1050 NM_Successor "Network management logical successor";
CM_ SG_ 1050 NM_Ud_Launch "Network management userdata launch type";
CM_ SG_ 1050 NM_Ud_Srv "Network management userdata service no.";
CM_ SG_ 1050 Nw_Id "Network identification no.";
CM_ SG_ 1050 WakeupCnt "Counter for module wakeup states during network sleep";
CM_ SG_ 1050 WakeupRsn_EPS "Wakeup reason EPS";
CM_ SG_ 1031 Awake_Brake_Pedal_Pressed "Stay awake for brake pedal pressed; True = [1]";
CM_ SG_ 1031 Awake_Diag_Actv "Stay awake for diagnostics active; True = [1]";
CM_ SG_ 1031 Awake_EPB_Switch_Wakeup "Stay awake for EPB switch actuation; True = [1]";
CM_ SG_ 1031 Awake_Hardwire_Ignition "Stay awake for ignition on; True = [1]";
CM_ SG_ 1031 Awake_NwSt "Stay awake for network startup; True = [1]";
CM_ SG_ 1031 Awake_Vehicle_Speed "Stay awake for vehicle speed; True = [1]";
CM_ SG_ 1031 NM_Mode "Network management mode";
CM_ SG_ 1031 NM_Sleep_Ack "Network management sleep acknowledge; True = [1]";
CM_ SG_ 1031 NM_Sleep_Ind "Network management sleep indication; True = [1]";
CM_ SG_ 1031 NM_Successor "Network management logical successor";
CM_ SG_ 1031 NM_Ud_Launch "Network management userdata launch type";
CM_ SG_ 1031 NM_Ud_Srv "Network management userdata service no.";
CM_ SG_ 1031 Nw_Id "Network identification no.";
CM_ SG_ 1031 WakeupCnt "Counter for module wakeup states during network sleep";
CM_ SG_ 1031 WakeupRsn_ESC "Wakeup reason ESC";
CM_ SG_ 1032 Awake_Diag_Actv "Stay awake for diagnostics active; True = [1]";
CM_ SG_ 1032 Awake_Ign_RunStart "Stay awake for the ignition is either Run or start; True = [1]";
CM_ SG_ 1032 Awake_Lock_Unlock "ESL is performing lock/unlock operation; True = [1]";
CM_ SG_ 1032 Awake_NwSt "Stay awake for network startup; True = [1]";
CM_ SG_ 1032 NM_Mode "Network management mode";
CM_ SG_ 1032 NM_Sleep_Ack "Network management sleep acknowledge; True = [1]";
CM_ SG_ 1032 NM_Sleep_Ind "Network management sleep indication; True = [1]";
CM_ SG_ 1032 NM_Successor "Network management logical successor";
CM_ SG_ 1032 NM_Ud_Launch "Network management userdata launch type";
CM_ SG_ 1032 NM_Ud_Srv "Network management userdata service no.";
CM_ SG_ 1032 Nw_Id "Network identification no.";
CM_ SG_ 1032 WakeupCnt "Counter for module wakeup states during network sleep";
CM_ SG_ 1032 WakeupRsn_ESL "Wakeup reason ESL";
CM_ SG_ 1082 Awake_Chg_ST "Stay awake for charging status indiaction; True = [1]";
CM_ SG_ 1082 Awake_Diag_Actv "Stay awake for diagnostics active; True = [1]";
CM_ SG_ 1082 Awake_NwSt "Stay awake for network startup; True = [1]";
CM_ SG_ 1082 Awake_OBCM_WU "Stay awake for OBCM wakeup; True = [1]";
CM_ SG_ 1082 NM_Mode "Network management mode";
CM_ SG_ 1082 NM_Sleep_Ack "Network management sleep acknowledge; True = [1]";
CM_ SG_ 1082 NM_Sleep_Ind "Network management sleep indication; True = [1]";
CM_ SG_ 1082 NM_Successor "Network management logical successor";
CM_ SG_ 1082 NM_Ud_Launch "Network management userdata launch type";
CM_ SG_ 1082 NM_Ud_Srv "Network management userdata service no.";
CM_ SG_ 1082 Nw_Id "Network identification no.";
CM_ SG_ 1082 WakeupCnt "Counter for module wakeup states during network sleep";
CM_ SG_ 1082 WakeupRsn_HCP "Wakeup reason HCP";
BA_DEF_ BO_  "App-Botschaft" ENUM  "nein","ja";
BA_DEF_ BO_  "CanMsgMinLen" INT 0 8;
BA_DEF_ BO_  "DiagRequest" ENUM  "nein","ja";
BA_DEF_ BO_  "DiagResponse" ENUM  "nein","ja";
BA_DEF_ BO_  "DiagState" ENUM  "nein","ja";
BA_DEF_ BO_  "GenMsgCycleTime" INT 0 65535;
BA_DEF_ BO_  "GenMsgCycleTimeActive" INT 0 65535;
BA_DEF_ BO_  "GenMsgDelayTime" INT 0 65535;
BA_DEF_ BO_  "GenMsgNrOfRepetitions" INT 0 65535;
BA_DEF_ BO_  "GenMsgSendType" ENUM  "cyclicX","spontanX","cyclicIfActiveX","spontanWithDelay","cyclicAndSpontanX","cyclicAndSpontanWithDelay","spontanWithRepitition","cyclicIfActiveAndSpontanWD","cyclicIfActiveFast","cyclicWithRepeatOnDemand","none";
BA_DEF_ BO_  "GenMsgStartDelayTime" INT 0 65535;
BA_DEF_ BO_  "GenMsgStartValue" STRING ;
BA_DEF_ BO_  "NWM-Botschaft" ENUM  "nein","ja";
BA_DEF_ BO_  "TpTxIndex" INT 0 99;
BA_DEF_ SG_  "FlexKomComment" STRING ;
BA_DEF_ SG_  "FlexKomIsMotorola" ENUM  "nein","ja";
BA_DEF_ SG_  "FlexKomSID" INT 0 2147483647;
BA_DEF_ SG_  "FlexKomSigLaenge" INT 0 64;
BA_DEF_ SG_  "FlexKomSigName" STRING ;
BA_DEF_ SG_  "FlexKomSigStartPos" INT 0 63;
BA_DEF_ SG_  "FlexKomSigStartValue" STRING ;
BA_DEF_ SG_  "GenSigCycleTime" INT 0 65535;
BA_DEF_ SG_  "GenSigCycleTimeActive" INT 0 65535;
BA_DEF_ SG_  "GenSigSendType" ENUM  "cyclicX","spontanX","cyclicIfActiveX","spontanWithDelay","cyclicAndSpontanX","cyclicAndSpontanWithDelay","spontanWithRepitition","cyclicIfActiveAndSpontanWD","cyclicIfActiveFast","cyclicWithRepeatOnDemand","none";
BA_DEF_ SG_  "GenSigSNA" STRING ;
BA_DEF_ SG_  "GenSigStartValue" HEX 0 2147483648;
BA_DEF_ SG_  "GenSigTimeout_AHLM" INT 0 65535;
BA_DEF_ SG_  "GenSigTimeout_ASBS" INT 0 65535;
BA_DEF_ SG_  "GenSigTimeout_CBC" INT 0 65535;
BA_DEF_ SG_  "GenSigTimeout_DPDM" INT 0 65535;
BA_DEF_ SG_  "GenSigTimeout_DTCM" INT 0 65535;
BA_DEF_ SG_  "GenSigTimeout_EHPS" INT 0 65535;
BA_DEF_ SG_  "GenSigTimeout_ESC" INT 0 65535;
BA_DEF_ SG_  "GenSigTimeout_ESL" INT 0 65535;
BA_DEF_ SG_  "GenSigTimeout_ESM" INT 0 65535;
BA_DEF_ SG_  "GenSigTimeout_ETM" INT 0 65535;
BA_DEF_ SG_  "GenSigTimeout_IC" INT 0 65535;
BA_DEF_ SG_  "GenSigTimeout_OCM" INT 0 65535;
BA_DEF_ SG_  "GenSigTimeout_ORC" INT 0 65535;
BA_DEF_ SG_  "GenSigTimeout_PTS" INT 0 65535;
BA_DEF_ SG_  "GenSigTimeout_RF_HUB" INT 0 65535;
BA_DEF_ SG_  "GenSigTimeout_SCCM" INT 0 65535;
BA_DEF_ SG_  "GenSigTimeout_TBM" INT 0 65535;
BA_DEF_ SG_  "GenSigTimeout_TCM" INT 0 65535;
BA_DEF_ SG_  "GenSigTimeout_TPM" INT 0 65535;
BA_DEF_ SG_  "RID" STRING ;
BA_DEF_ SG_  "SystemSignalLongSymbol" STRING ;
BA_DEF_DEF_  "App-Botschaft" "nein";
BA_DEF_DEF_  "CanMsgMinLen" 0;
BA_DEF_DEF_  "DiagRequest" "nein";
BA_DEF_DEF_  "DiagResponse" "nein";
BA_DEF_DEF_  "DiagState" "nein";
BA_DEF_DEF_  "GenMsgCycleTime" 0;
BA_DEF_DEF_  "GenMsgCycleTimeActive" 0;
BA_DEF_DEF_  "GenMsgDelayTime" 0;
BA_DEF_DEF_  "GenMsgNrOfRepetitions" 0;
BA_DEF_DEF_  "GenMsgSendType" "cyclicX";
BA_DEF_DEF_  "GenMsgStartDelayTime" 0;
BA_DEF_DEF_  "GenMsgStartValue" "";
BA_DEF_DEF_  "NWM-Botschaft" "nein";
BA_DEF_DEF_  "TpTxIndex" 0;
BA_DEF_DEF_  "FlexKomComment" "";
BA_DEF_DEF_  "FlexKomIsMotorola" "nein";
BA_DEF_DEF_  "FlexKomSID" 0;
BA_DEF_DEF_  "FlexKomSigLaenge" 0;
BA_DEF_DEF_  "FlexKomSigName" "";
BA_DEF_DEF_  "FlexKomSigStartPos" 0;
BA_DEF_DEF_  "FlexKomSigStartValue" "";
BA_DEF_DEF_  "GenSigCycleTime" 0;
BA_DEF_DEF_  "GenSigCycleTimeActive" 0;
BA_DEF_DEF_  "GenSigSendType" "cyclicX";
BA_DEF_DEF_  "GenSigSNA" "";
BA_DEF_DEF_  "GenSigStartValue" 0;
BA_DEF_DEF_  "GenSigTimeout_AHLM" 0;
BA_DEF_DEF_  "GenSigTimeout_ASBS" 0;
BA_DEF_DEF_  "GenSigTimeout_CBC" 0;
BA_DEF_DEF_  "GenSigTimeout_DPDM" 0;
BA_DEF_DEF_  "GenSigTimeout_DTCM" 0;
BA_DEF_DEF_  "GenSigTimeout_EHPS" 0;
BA_DEF_DEF_  "GenSigTimeout_ESC" 0;
BA_DEF_DEF_  "GenSigTimeout_ESL" 0;
BA_DEF_DEF_  "GenSigTimeout_ESM" 0;
BA_DEF_DEF_  "GenSigTimeout_ETM" 0;
BA_DEF_DEF_  "GenSigTimeout_IC" 0;
BA_DEF_DEF_  "GenSigTimeout_OCM" 0;
BA_DEF_DEF_  "GenSigTimeout_ORC" 0;
BA_DEF_DEF_  "GenSigTimeout_PTS" 0;
BA_DEF_DEF_  "GenSigTimeout_RF_HUB" 0;
BA_DEF_DEF_  "GenSigTimeout_SCCM" 0;
BA_DEF_DEF_  "GenSigTimeout_TBM" 0;
BA_DEF_DEF_  "GenSigTimeout_TCM" 0;
BA_DEF_DEF_  "GenSigTimeout_TPM" 0;
BA_DEF_DEF_  "RID" "";
BA_DEF_DEF_  "SystemSignalLongSymbol" "";
BA_ "GenMsgStartValue" BO_ 943 "0000000000000000h";
BA_ "GenMsgStartDelayTime" BO_ 943 250;
BA_ "GenMsgNrOfRepetitions" BO_ 943 2;
BA_ "GenMsgDelayTime" BO_ 943 20;
BA_ "GenMsgCycleTime" BO_ 943 1000;
BA_ "GenMsgStartValue" BO_ 958 "0000000000000000h";
BA_ "GenMsgStartDelayTime" BO_ 958 300;
BA_ "GenMsgNrOfRepetitions" BO_ 958 2;
BA_ "GenMsgDelayTime" BO_ 958 20;
BA_ "GenMsgCycleTime" BO_ 958 1000;
BA_ "GenMsgStartValue" BO_ 959 "0000000000000000h";
BA_ "GenMsgStartDelayTime" BO_ 959 350;
BA_ "GenMsgNrOfRepetitions" BO_ 959 2;
BA_ "GenMsgDelayTime" BO_ 959 20;
BA_ "GenMsgCycleTime" BO_ 959 1000;
BA_ "GenMsgStartValue" BO_ 517 "00000000000000h";
BA_ "GenMsgSendType" BO_ 517 1;
BA_ "GenMsgNrOfRepetitions" BO_ 517 2;
BA_ "GenMsgDelayTime" BO_ 517 20;
BA_ "GenMsgStartValue" BO_ 515 "00000000000000h";
BA_ "GenMsgSendType" BO_ 515 1;
BA_ "GenMsgNrOfRepetitions" BO_ 515 2;
BA_ "GenMsgDelayTime" BO_ 515 20;
BA_ "GenMsgStartValue" BO_ 516 "00000000000000h";
BA_ "GenMsgSendType" BO_ 516 1;
BA_ "GenMsgNrOfRepetitions" BO_ 516 2;
BA_ "GenMsgDelayTime" BO_ 516 20;
BA_ "GenMsgStartValue" BO_ 518 "00000000000000h";
BA_ "GenMsgSendType" BO_ 518 1;
BA_ "GenMsgNrOfRepetitions" BO_ 518 2;
BA_ "GenMsgDelayTime" BO_ 518 20;
BA_ "GenMsgStartValue" BO_ 973 "0000000000000000h";
BA_ "GenMsgSendType" BO_ 973 5;
BA_ "GenMsgNrOfRepetitions" BO_ 973 2;
BA_ "GenMsgDelayTime" BO_ 973 20;
BA_ "GenMsgCycleTime" BO_ 973 2000;
BA_ "GenMsgStartValue" BO_ 868 "0000000000000000h";
BA_ "GenMsgSendType" BO_ 868 1;
BA_ "GenMsgNrOfRepetitions" BO_ 868 2;
BA_ "GenMsgDelayTime" BO_ 868 20;
BA_ "GenMsgStartValue" BO_ 956 "0000000000000000h";
BA_ "GenMsgSendType" BO_ 956 1;
BA_ "GenMsgNrOfRepetitions" BO_ 956 2;
BA_ "GenMsgDelayTime" BO_ 956 20;
BA_ "GenMsgStartValue" BO_ 926 "030000h";
BA_ "GenMsgSendType" BO_ 926 5;
BA_ "GenMsgNrOfRepetitions" BO_ 926 2;
BA_ "GenMsgDelayTime" BO_ 926 20;
BA_ "GenMsgCycleTime" BO_ 926 2000;
BA_ "GenMsgStartValue" BO_ 995 "0300000000000000h";
BA_ "GenMsgStartDelayTime" BO_ 995 20;
BA_ "GenMsgSendType" BO_ 995 5;
BA_ "GenMsgNrOfRepetitions" BO_ 995 2;
BA_ "GenMsgDelayTime" BO_ 995 20;
BA_ "GenMsgCycleTime" BO_ 995 2000;
BA_ "GenMsgStartValue" BO_ 996 "0300000000000000h";
BA_ "GenMsgStartDelayTime" BO_ 996 10;
BA_ "GenMsgSendType" BO_ 996 5;
BA_ "GenMsgNrOfRepetitions" BO_ 996 2;
BA_ "GenMsgDelayTime" BO_ 996 20;
BA_ "GenMsgCycleTime" BO_ 996 2000;
BA_ "NWM-Botschaft" BO_ 1025 1;
BA_ "GenMsgStartValue" BO_ 1025 "FFFFFFFF000000FFh";
BA_ "GenMsgSendType" BO_ 1025 1;
BA_ "GenMsgNrOfRepetitions" BO_ 1025 2;
BA_ "GenMsgDelayTime" BO_ 1025 20;
BA_ "NWM-Botschaft" BO_ 1050 1;
BA_ "GenMsgStartValue" BO_ 1050 "FFFFFFFF000000FFh";
BA_ "GenMsgSendType" BO_ 1050 1;
BA_ "GenMsgNrOfRepetitions" BO_ 1050 2;
BA_ "GenMsgDelayTime" BO_ 1050 20;
BA_ "NWM-Botschaft" BO_ 1031 1;
BA_ "GenMsgStartValue" BO_ 1031 "FFFFFFFF000000FFh";
BA_ "GenMsgSendType" BO_ 1031 1;
BA_ "GenMsgNrOfRepetitions" BO_ 1031 2;
BA_ "GenMsgDelayTime" BO_ 1031 20;
BA_ "NWM-Botschaft" BO_ 1032 1;
BA_ "GenMsgStartValue" BO_ 1032 "FFFFFFFF000000FFh";
BA_ "GenMsgSendType" BO_ 1032 1;
BA_ "GenMsgNrOfRepetitions" BO_ 1032 2;
BA_ "GenMsgDelayTime" BO_ 1032 20;
BA_ "NWM-Botschaft" BO_ 1082 1;
BA_ "GenMsgStartValue" BO_ 1082 "FFFFFFFF000000FFh";
BA_ "GenMsgSendType" BO_ 1082 1;
BA_ "GenMsgNrOfRepetitions" BO_ 1082 2;
BA_ "GenMsgDelayTime" BO_ 1082 20;
BA_ "GenSigTimeout_ETM" SG_ 943 B_Total_Dist_Kilometers 10500;
BA_ "GenSigSNA" SG_ 943 B_Total_Dist_Kilometers "FFFFFFh";
BA_ "GenSigCycleTime" SG_ 943 B_Total_Dist_Kilometers 1000;
BA_ "FlexKomSigStartValue" SG_ 943 B_Total_Dist_Kilometers "0000000000000000h";
BA_ "FlexKomSigStartPos" SG_ 943 B_Total_Dist_Kilometers 7;
BA_ "FlexKomSigName" SG_ 943 B_Total_Dist_Kilometers "IC_TripData_Pkt_6";
BA_ "FlexKomSigLaenge" SG_ 943 B_Total_Dist_Kilometers 64;
BA_ "FlexKomSID" SG_ 943 B_Total_Dist_Kilometers 2580;
BA_ "FlexKomIsMotorola" SG_ 943 B_Total_Dist_Kilometers 1;
BA_ "FlexKomComment" SG_ 943 B_Total_Dist_Kilometers "IC Trip data packet 6";
BA_ "GenSigTimeout_ETM" SG_ 943 B_Total_Dist_Miles 10500;
BA_ "GenSigSNA" SG_ 943 B_Total_Dist_Miles "FFFFFFh";
BA_ "GenSigCycleTime" SG_ 943 B_Total_Dist_Miles 1000;
BA_ "FlexKomSigStartValue" SG_ 943 B_Total_Dist_Miles "0000000000000000h";
BA_ "FlexKomSigStartPos" SG_ 943 B_Total_Dist_Miles 7;
BA_ "FlexKomSigName" SG_ 943 B_Total_Dist_Miles "IC_TripData_Pkt_6";
BA_ "FlexKomSigLaenge" SG_ 943 B_Total_Dist_Miles 64;
BA_ "FlexKomSID" SG_ 943 B_Total_Dist_Miles 2580;
BA_ "FlexKomIsMotorola" SG_ 943 B_Total_Dist_Miles 1;
BA_ "FlexKomComment" SG_ 943 B_Total_Dist_Miles "IC Trip data packet 6";
BA_ "RID" SG_ 958 Electric_Dist_Miles "6515";
BA_ "GenSigTimeout_ETM" SG_ 958 Electric_Dist_Miles 10500;
BA_ "GenSigTimeout_CBC" SG_ 958 Electric_Dist_Miles 10500;
BA_ "GenSigSNA" SG_ 958 Electric_Dist_Miles "3FFh";
BA_ "GenSigCycleTime" SG_ 958 Electric_Dist_Miles 1000;
BA_ "FlexKomSigStartValue" SG_ 958 Electric_Dist_Miles "0000000000000000h";
BA_ "FlexKomSigStartPos" SG_ 958 Electric_Dist_Miles 7;
BA_ "FlexKomSigName" SG_ 958 Electric_Dist_Miles "IC_TripData_Pkt_7";
BA_ "FlexKomSigLaenge" SG_ 958 Electric_Dist_Miles 64;
BA_ "FlexKomSID" SG_ 958 Electric_Dist_Miles 2579;
BA_ "FlexKomIsMotorola" SG_ 958 Electric_Dist_Miles 1;
BA_ "FlexKomComment" SG_ 958 Electric_Dist_Miles "IC Trip data packet 7";
BA_ "RID" SG_ 958 Hybrid_Dist_Miles "6510";
BA_ "GenSigTimeout_ETM" SG_ 958 Hybrid_Dist_Miles 10500;
BA_ "GenSigTimeout_CBC" SG_ 958 Hybrid_Dist_Miles 10500;
BA_ "GenSigSNA" SG_ 958 Hybrid_Dist_Miles "3FFh";
BA_ "GenSigCycleTime" SG_ 958 Hybrid_Dist_Miles 1000;
BA_ "FlexKomSigStartValue" SG_ 958 Hybrid_Dist_Miles "0000000000000000h";
BA_ "FlexKomSigStartPos" SG_ 958 Hybrid_Dist_Miles 7;
BA_ "FlexKomSigName" SG_ 958 Hybrid_Dist_Miles "IC_TripData_Pkt_7";
BA_ "FlexKomSigLaenge" SG_ 958 Hybrid_Dist_Miles 64;
BA_ "FlexKomSID" SG_ 958 Hybrid_Dist_Miles 2579;
BA_ "FlexKomIsMotorola" SG_ 958 Hybrid_Dist_Miles 1;
BA_ "FlexKomComment" SG_ 958 Hybrid_Dist_Miles "IC Trip data packet 7";
BA_ "RID" SG_ 959 Electric_Dist_Kilometers "6511";
BA_ "GenSigTimeout_ETM" SG_ 959 Electric_Dist_Kilometers 10500;
BA_ "GenSigTimeout_CBC" SG_ 959 Electric_Dist_Kilometers 10500;
BA_ "GenSigSNA" SG_ 959 Electric_Dist_Kilometers "3FFh";
BA_ "GenSigCycleTime" SG_ 959 Electric_Dist_Kilometers 1000;
BA_ "FlexKomSigStartValue" SG_ 959 Electric_Dist_Kilometers "0000000000000000h";
BA_ "FlexKomSigStartPos" SG_ 959 Electric_Dist_Kilometers 7;
BA_ "FlexKomSigName" SG_ 959 Electric_Dist_Kilometers "IC_TripData_Pkt_8";
BA_ "FlexKomSigLaenge" SG_ 959 Electric_Dist_Kilometers 64;
BA_ "FlexKomSID" SG_ 959 Electric_Dist_Kilometers 2569;
BA_ "FlexKomIsMotorola" SG_ 959 Electric_Dist_Kilometers 1;
BA_ "FlexKomComment" SG_ 959 Electric_Dist_Kilometers "IC Trip data packet 8";
BA_ "RID" SG_ 959 Hybrid_Dist_Kilometers "6521";
BA_ "GenSigTimeout_ETM" SG_ 959 Hybrid_Dist_Kilometers 10500;
BA_ "GenSigTimeout_CBC" SG_ 959 Hybrid_Dist_Kilometers 10500;
BA_ "GenSigSNA" SG_ 959 Hybrid_Dist_Kilometers "3FFh";
BA_ "GenSigCycleTime" SG_ 959 Hybrid_Dist_Kilometers 1000;
BA_ "FlexKomSigStartValue" SG_ 959 Hybrid_Dist_Kilometers "0000000000000000h";
BA_ "FlexKomSigStartPos" SG_ 959 Hybrid_Dist_Kilometers 7;
BA_ "FlexKomSigName" SG_ 959 Hybrid_Dist_Kilometers "IC_TripData_Pkt_8";
BA_ "FlexKomSigLaenge" SG_ 959 Hybrid_Dist_Kilometers 64;
BA_ "FlexKomSID" SG_ 959 Hybrid_Dist_Kilometers 2569;
BA_ "FlexKomIsMotorola" SG_ 959 Hybrid_Dist_Kilometers 1;
BA_ "FlexKomComment" SG_ 959 Hybrid_Dist_Kilometers "IC Trip data packet 8";
BA_ "GenSigSNA" SG_ 517 ControlEncodingRq "0h";
BA_ "GenSigSendType" SG_ 517 ControlEncodingRq 1;
BA_ "FlexKomSigStartValue" SG_ 517 ControlEncodingRq "00000000000000h";
BA_ "FlexKomSigStartPos" SG_ 517 ControlEncodingRq 7;
BA_ "FlexKomSigName" SG_ 517 ControlEncodingRq "IMMO_CODE_REQUEST";
BA_ "FlexKomSigLaenge" SG_ 517 ControlEncodingRq 56;
BA_ "FlexKomSID" SG_ 517 ControlEncodingRq 2111;
BA_ "FlexKomIsMotorola" SG_ 517 ControlEncodingRq 1;
BA_ "FlexKomComment" SG_ 517 ControlEncodingRq "Immobilizer code request packet";
BA_ "GenSigSNA" SG_ 517 f1_1 "0h";
BA_ "GenSigSendType" SG_ 517 f1_1 1;
BA_ "FlexKomSigStartValue" SG_ 517 f1_1 "00000000000000h";
BA_ "FlexKomSigStartPos" SG_ 517 f1_1 7;
BA_ "FlexKomSigName" SG_ 517 f1_1 "IMMO_CODE_REQUEST";
BA_ "FlexKomSigLaenge" SG_ 517 f1_1 56;
BA_ "FlexKomSID" SG_ 517 f1_1 2111;
BA_ "FlexKomIsMotorola" SG_ 517 f1_1 1;
BA_ "FlexKomComment" SG_ 517 f1_1 "Immobilizer code request packet";
BA_ "GenSigSNA" SG_ 517 f1_2 "0h";
BA_ "GenSigSendType" SG_ 517 f1_2 1;
BA_ "FlexKomSigStartValue" SG_ 517 f1_2 "00000000000000h";
BA_ "FlexKomSigStartPos" SG_ 517 f1_2 7;
BA_ "FlexKomSigName" SG_ 517 f1_2 "IMMO_CODE_REQUEST";
BA_ "FlexKomSigLaenge" SG_ 517 f1_2 56;
BA_ "FlexKomSID" SG_ 517 f1_2 2111;
BA_ "FlexKomIsMotorola" SG_ 517 f1_2 1;
BA_ "FlexKomComment" SG_ 517 f1_2 "Immobilizer code request packet";
BA_ "GenSigSNA" SG_ 517 rnd_1 "0h";
BA_ "GenSigSendType" SG_ 517 rnd_1 1;
BA_ "FlexKomSigStartValue" SG_ 517 rnd_1 "00000000000000h";
BA_ "FlexKomSigStartPos" SG_ 517 rnd_1 7;
BA_ "FlexKomSigName" SG_ 517 rnd_1 "IMMO_CODE_REQUEST";
BA_ "FlexKomSigLaenge" SG_ 517 rnd_1 56;
BA_ "FlexKomSID" SG_ 517 rnd_1 2111;
BA_ "FlexKomIsMotorola" SG_ 517 rnd_1 1;
BA_ "FlexKomComment" SG_ 517 rnd_1 "Immobilizer code request packet";
BA_ "GenSigSNA" SG_ 517 rnd_2 "0h";
BA_ "GenSigSendType" SG_ 517 rnd_2 1;
BA_ "FlexKomSigStartValue" SG_ 517 rnd_2 "00000000000000h";
BA_ "FlexKomSigStartPos" SG_ 517 rnd_2 7;
BA_ "FlexKomSigName" SG_ 517 rnd_2 "IMMO_CODE_REQUEST";
BA_ "FlexKomSigLaenge" SG_ 517 rnd_2 56;
BA_ "FlexKomSID" SG_ 517 rnd_2 2111;
BA_ "FlexKomIsMotorola" SG_ 517 rnd_2 1;
BA_ "FlexKomComment" SG_ 517 rnd_2 "Immobilizer code request packet";
BA_ "GenSigSNA" SG_ 517 rnd_3 "0h";
BA_ "GenSigSendType" SG_ 517 rnd_3 1;
BA_ "FlexKomSigStartValue" SG_ 517 rnd_3 "00000000000000h";
BA_ "FlexKomSigStartPos" SG_ 517 rnd_3 7;
BA_ "FlexKomSigName" SG_ 517 rnd_3 "IMMO_CODE_REQUEST";
BA_ "FlexKomSigLaenge" SG_ 517 rnd_3 56;
BA_ "FlexKomSID" SG_ 517 rnd_3 2111;
BA_ "FlexKomIsMotorola" SG_ 517 rnd_3 1;
BA_ "FlexKomComment" SG_ 517 rnd_3 "Immobilizer code request packet";
BA_ "GenSigSNA" SG_ 517 rnd_4 "0h";
BA_ "GenSigSendType" SG_ 517 rnd_4 1;
BA_ "FlexKomSigStartValue" SG_ 517 rnd_4 "00000000000000h";
BA_ "FlexKomSigStartPos" SG_ 517 rnd_4 7;
BA_ "FlexKomSigName" SG_ 517 rnd_4 "IMMO_CODE_REQUEST";
BA_ "FlexKomSigLaenge" SG_ 517 rnd_4 56;
BA_ "FlexKomSID" SG_ 517 rnd_4 2111;
BA_ "FlexKomIsMotorola" SG_ 517 rnd_4 1;
BA_ "FlexKomComment" SG_ 517 rnd_4 "Immobilizer code request packet";
BA_ "GenSigSNA" SG_ 515 ControlEncodingRq "0h";
BA_ "GenSigSendType" SG_ 515 ControlEncodingRq 1;
BA_ "FlexKomSigStartValue" SG_ 515 ControlEncodingRq "00000000000000h";
BA_ "FlexKomSigStartPos" SG_ 515 ControlEncodingRq 7;
BA_ "FlexKomSigName" SG_ 515 ControlEncodingRq "IMMO_CODE_REQUEST_HCP";
BA_ "FlexKomSigLaenge" SG_ 515 ControlEncodingRq 56;
BA_ "FlexKomSID" SG_ 515 ControlEncodingRq 2516;
BA_ "FlexKomIsMotorola" SG_ 515 ControlEncodingRq 1;
BA_ "FlexKomComment" SG_ 515 ControlEncodingRq "Immobilizer code request packet";
BA_ "GenSigSNA" SG_ 515 f1_01 "0h";
BA_ "GenSigSendType" SG_ 515 f1_01 1;
BA_ "FlexKomSigStartValue" SG_ 515 f1_01 "00000000000000h";
BA_ "FlexKomSigStartPos" SG_ 515 f1_01 7;
BA_ "FlexKomSigName" SG_ 515 f1_01 "IMMO_CODE_REQUEST_HCP";
BA_ "FlexKomSigLaenge" SG_ 515 f1_01 56;
BA_ "FlexKomSID" SG_ 515 f1_01 2516;
BA_ "FlexKomIsMotorola" SG_ 515 f1_01 1;
BA_ "FlexKomComment" SG_ 515 f1_01 "Immobilizer code request packet";
BA_ "GenSigSNA" SG_ 515 f1_02 "0h";
BA_ "GenSigSendType" SG_ 515 f1_02 1;
BA_ "FlexKomSigStartValue" SG_ 515 f1_02 "00000000000000h";
BA_ "FlexKomSigStartPos" SG_ 515 f1_02 7;
BA_ "FlexKomSigName" SG_ 515 f1_02 "IMMO_CODE_REQUEST_HCP";
BA_ "FlexKomSigLaenge" SG_ 515 f1_02 56;
BA_ "FlexKomSID" SG_ 515 f1_02 2516;
BA_ "FlexKomIsMotorola" SG_ 515 f1_02 1;
BA_ "FlexKomComment" SG_ 515 f1_02 "Immobilizer code request packet";
BA_ "GenSigSNA" SG_ 515 rnd_01 "0h";
BA_ "GenSigSendType" SG_ 515 rnd_01 1;
BA_ "FlexKomSigStartValue" SG_ 515 rnd_01 "00000000000000h";
BA_ "FlexKomSigStartPos" SG_ 515 rnd_01 7;
BA_ "FlexKomSigName" SG_ 515 rnd_01 "IMMO_CODE_REQUEST_HCP";
BA_ "FlexKomSigLaenge" SG_ 515 rnd_01 56;
BA_ "FlexKomSID" SG_ 515 rnd_01 2516;
BA_ "FlexKomIsMotorola" SG_ 515 rnd_01 1;
BA_ "FlexKomComment" SG_ 515 rnd_01 "Immobilizer code request packet";
BA_ "GenSigSNA" SG_ 515 rnd_02 "0h";
BA_ "GenSigSendType" SG_ 515 rnd_02 1;
BA_ "FlexKomSigStartValue" SG_ 515 rnd_02 "00000000000000h";
BA_ "FlexKomSigStartPos" SG_ 515 rnd_02 7;
BA_ "FlexKomSigName" SG_ 515 rnd_02 "IMMO_CODE_REQUEST_HCP";
BA_ "FlexKomSigLaenge" SG_ 515 rnd_02 56;
BA_ "FlexKomSID" SG_ 515 rnd_02 2516;
BA_ "FlexKomIsMotorola" SG_ 515 rnd_02 1;
BA_ "FlexKomComment" SG_ 515 rnd_02 "Immobilizer code request packet";
BA_ "GenSigSNA" SG_ 515 rnd_03 "0h";
BA_ "GenSigSendType" SG_ 515 rnd_03 1;
BA_ "FlexKomSigStartValue" SG_ 515 rnd_03 "00000000000000h";
BA_ "FlexKomSigStartPos" SG_ 515 rnd_03 7;
BA_ "FlexKomSigName" SG_ 515 rnd_03 "IMMO_CODE_REQUEST_HCP";
BA_ "FlexKomSigLaenge" SG_ 515 rnd_03 56;
BA_ "FlexKomSID" SG_ 515 rnd_03 2516;
BA_ "FlexKomIsMotorola" SG_ 515 rnd_03 1;
BA_ "FlexKomComment" SG_ 515 rnd_03 "Immobilizer code request packet";
BA_ "GenSigSNA" SG_ 515 rnd_04 "0h";
BA_ "GenSigSendType" SG_ 515 rnd_04 1;
BA_ "FlexKomSigStartValue" SG_ 515 rnd_04 "00000000000000h";
BA_ "FlexKomSigStartPos" SG_ 515 rnd_04 7;
BA_ "FlexKomSigName" SG_ 515 rnd_04 "IMMO_CODE_REQUEST_HCP";
BA_ "FlexKomSigLaenge" SG_ 515 rnd_04 56;
BA_ "FlexKomSID" SG_ 515 rnd_04 2516;
BA_ "FlexKomIsMotorola" SG_ 515 rnd_04 1;
BA_ "FlexKomComment" SG_ 515 rnd_04 "Immobilizer code request packet";
BA_ "GenSigSNA" SG_ 516 ControlEncodingRsp "0h";
BA_ "GenSigSendType" SG_ 516 ControlEncodingRsp 1;
BA_ "FlexKomSigStartValue" SG_ 516 ControlEncodingRsp "00000000000000h";
BA_ "FlexKomSigStartPos" SG_ 516 ControlEncodingRsp 7;
BA_ "FlexKomSigName" SG_ 516 ControlEncodingRsp "IMMO_CODE_RESPONSE";
BA_ "FlexKomSigLaenge" SG_ 516 ControlEncodingRsp 56;
BA_ "FlexKomSID" SG_ 516 ControlEncodingRsp 2110;
BA_ "FlexKomIsMotorola" SG_ 516 ControlEncodingRsp 1;
BA_ "FlexKomComment" SG_ 516 ControlEncodingRsp "Immobilizer code response packet";
BA_ "GenSigSNA" SG_ 516 MKKey1org21 "0h";
BA_ "GenSigSendType" SG_ 516 MKKey1org21 1;
BA_ "FlexKomSigStartValue" SG_ 516 MKKey1org21 "00000000000000h";
BA_ "FlexKomSigStartPos" SG_ 516 MKKey1org21 7;
BA_ "FlexKomSigName" SG_ 516 MKKey1org21 "IMMO_CODE_RESPONSE";
BA_ "FlexKomSigLaenge" SG_ 516 MKKey1org21 56;
BA_ "FlexKomSID" SG_ 516 MKKey1org21 2110;
BA_ "FlexKomIsMotorola" SG_ 516 MKKey1org21 1;
BA_ "FlexKomComment" SG_ 516 MKKey1org21 "Immobilizer code response packet";
BA_ "GenSigSNA" SG_ 516 MKKey2org22 "0h";
BA_ "GenSigSendType" SG_ 516 MKKey2org22 1;
BA_ "FlexKomSigStartValue" SG_ 516 MKKey2org22 "00000000000000h";
BA_ "FlexKomSigStartPos" SG_ 516 MKKey2org22 7;
BA_ "FlexKomSigName" SG_ 516 MKKey2org22 "IMMO_CODE_RESPONSE";
BA_ "FlexKomSigLaenge" SG_ 516 MKKey2org22 56;
BA_ "FlexKomSID" SG_ 516 MKKey2org22 2110;
BA_ "FlexKomIsMotorola" SG_ 516 MKKey2org22 1;
BA_ "FlexKomComment" SG_ 516 MKKey2org22 "Immobilizer code response packet";
BA_ "GenSigSNA" SG_ 516 MKKey_3 "0h";
BA_ "GenSigSendType" SG_ 516 MKKey_3 1;
BA_ "FlexKomSigStartValue" SG_ 516 MKKey_3 "00000000000000h";
BA_ "FlexKomSigStartPos" SG_ 516 MKKey_3 7;
BA_ "FlexKomSigName" SG_ 516 MKKey_3 "IMMO_CODE_RESPONSE";
BA_ "FlexKomSigLaenge" SG_ 516 MKKey_3 56;
BA_ "FlexKomSID" SG_ 516 MKKey_3 2110;
BA_ "FlexKomIsMotorola" SG_ 516 MKKey_3 1;
BA_ "FlexKomComment" SG_ 516 MKKey_3 "Immobilizer code response packet";
BA_ "GenSigSNA" SG_ 516 MKKey_4 "0h";
BA_ "GenSigSendType" SG_ 516 MKKey_4 1;
BA_ "FlexKomSigStartValue" SG_ 516 MKKey_4 "00000000000000h";
BA_ "FlexKomSigStartPos" SG_ 516 MKKey_4 7;
BA_ "FlexKomSigName" SG_ 516 MKKey_4 "IMMO_CODE_RESPONSE";
BA_ "FlexKomSigLaenge" SG_ 516 MKKey_4 56;
BA_ "FlexKomSID" SG_ 516 MKKey_4 2110;
BA_ "FlexKomIsMotorola" SG_ 516 MKKey_4 1;
BA_ "FlexKomComment" SG_ 516 MKKey_4 "Immobilizer code response packet";
BA_ "GenSigSNA" SG_ 516 MKKey_5 "0h";
BA_ "GenSigSendType" SG_ 516 MKKey_5 1;
BA_ "FlexKomSigStartValue" SG_ 516 MKKey_5 "00000000000000h";
BA_ "FlexKomSigStartPos" SG_ 516 MKKey_5 7;
BA_ "FlexKomSigName" SG_ 516 MKKey_5 "IMMO_CODE_RESPONSE";
BA_ "FlexKomSigLaenge" SG_ 516 MKKey_5 56;
BA_ "FlexKomSID" SG_ 516 MKKey_5 2110;
BA_ "FlexKomIsMotorola" SG_ 516 MKKey_5 1;
BA_ "FlexKomComment" SG_ 516 MKKey_5 "Immobilizer code response packet";
BA_ "GenSigSNA" SG_ 516 MKKey_6 "0h";
BA_ "GenSigSendType" SG_ 516 MKKey_6 1;
BA_ "FlexKomSigStartValue" SG_ 516 MKKey_6 "00000000000000h";
BA_ "FlexKomSigStartPos" SG_ 516 MKKey_6 7;
BA_ "FlexKomSigName" SG_ 516 MKKey_6 "IMMO_CODE_RESPONSE";
BA_ "FlexKomSigLaenge" SG_ 516 MKKey_6 56;
BA_ "FlexKomSID" SG_ 516 MKKey_6 2110;
BA_ "FlexKomIsMotorola" SG_ 516 MKKey_6 1;
BA_ "FlexKomComment" SG_ 516 MKKey_6 "Immobilizer code response packet";
BA_ "GenSigSNA" SG_ 518 ControlEncoding_Rsp "0h";
BA_ "GenSigSendType" SG_ 518 ControlEncoding_Rsp 1;
BA_ "FlexKomSigStartValue" SG_ 518 ControlEncoding_Rsp "00000000000000h";
BA_ "FlexKomSigStartPos" SG_ 518 ControlEncoding_Rsp 7;
BA_ "FlexKomSigName" SG_ 518 ControlEncoding_Rsp "IMMO_CODE_RESPONSE_HCP";
BA_ "FlexKomSigLaenge" SG_ 518 ControlEncoding_Rsp 56;
BA_ "FlexKomSID" SG_ 518 ControlEncoding_Rsp 2515;
BA_ "FlexKomIsMotorola" SG_ 518 ControlEncoding_Rsp 1;
BA_ "FlexKomComment" SG_ 518 ControlEncoding_Rsp "Immobilizer code response packet";
BA_ "GenSigSNA" SG_ 518 MKKey01org21 "0h";
BA_ "GenSigSendType" SG_ 518 MKKey01org21 1;
BA_ "FlexKomSigStartValue" SG_ 518 MKKey01org21 "00000000000000h";
BA_ "FlexKomSigStartPos" SG_ 518 MKKey01org21 7;
BA_ "FlexKomSigName" SG_ 518 MKKey01org21 "IMMO_CODE_RESPONSE_HCP";
BA_ "FlexKomSigLaenge" SG_ 518 MKKey01org21 56;
BA_ "FlexKomSID" SG_ 518 MKKey01org21 2515;
BA_ "FlexKomIsMotorola" SG_ 518 MKKey01org21 1;
BA_ "FlexKomComment" SG_ 518 MKKey01org21 "Immobilizer code response packet";
BA_ "GenSigSNA" SG_ 518 MKKey02org22 "0h";
BA_ "GenSigSendType" SG_ 518 MKKey02org22 1;
BA_ "FlexKomSigStartValue" SG_ 518 MKKey02org22 "00000000000000h";
BA_ "FlexKomSigStartPos" SG_ 518 MKKey02org22 7;
BA_ "FlexKomSigName" SG_ 518 MKKey02org22 "IMMO_CODE_RESPONSE_HCP";
BA_ "FlexKomSigLaenge" SG_ 518 MKKey02org22 56;
BA_ "FlexKomSID" SG_ 518 MKKey02org22 2515;
BA_ "FlexKomIsMotorola" SG_ 518 MKKey02org22 1;
BA_ "FlexKomComment" SG_ 518 MKKey02org22 "Immobilizer code response packet";
BA_ "GenSigSNA" SG_ 518 MKKey_03 "0h";
BA_ "GenSigSendType" SG_ 518 MKKey_03 1;
BA_ "FlexKomSigStartValue" SG_ 518 MKKey_03 "00000000000000h";
BA_ "FlexKomSigStartPos" SG_ 518 MKKey_03 7;
BA_ "FlexKomSigName" SG_ 518 MKKey_03 "IMMO_CODE_RESPONSE_HCP";
BA_ "FlexKomSigLaenge" SG_ 518 MKKey_03 56;
BA_ "FlexKomSID" SG_ 518 MKKey_03 2515;
BA_ "FlexKomIsMotorola" SG_ 518 MKKey_03 1;
BA_ "FlexKomComment" SG_ 518 MKKey_03 "Immobilizer code response packet";
BA_ "GenSigSNA" SG_ 518 MKKey_04 "0h";
BA_ "GenSigSendType" SG_ 518 MKKey_04 1;
BA_ "FlexKomSigStartValue" SG_ 518 MKKey_04 "00000000000000h";
BA_ "FlexKomSigStartPos" SG_ 518 MKKey_04 7;
BA_ "FlexKomSigName" SG_ 518 MKKey_04 "IMMO_CODE_RESPONSE_HCP";
BA_ "FlexKomSigLaenge" SG_ 518 MKKey_04 56;
BA_ "FlexKomSID" SG_ 518 MKKey_04 2515;
BA_ "FlexKomIsMotorola" SG_ 518 MKKey_04 1;
BA_ "FlexKomComment" SG_ 518 MKKey_04 "Immobilizer code response packet";
BA_ "GenSigSNA" SG_ 518 MKKey_05 "0h";
BA_ "GenSigSendType" SG_ 518 MKKey_05 1;
BA_ "FlexKomSigStartValue" SG_ 518 MKKey_05 "00000000000000h";
BA_ "FlexKomSigStartPos" SG_ 518 MKKey_05 7;
BA_ "FlexKomSigName" SG_ 518 MKKey_05 "IMMO_CODE_RESPONSE_HCP";
BA_ "FlexKomSigLaenge" SG_ 518 MKKey_05 56;
BA_ "FlexKomSID" SG_ 518 MKKey_05 2515;
BA_ "FlexKomIsMotorola" SG_ 518 MKKey_05 1;
BA_ "FlexKomComment" SG_ 518 MKKey_05 "Immobilizer code response packet";
BA_ "GenSigSNA" SG_ 518 MKKey_06 "0h";
BA_ "GenSigSendType" SG_ 518 MKKey_06 1;
BA_ "FlexKomSigStartValue" SG_ 518 MKKey_06 "00000000000000h";
BA_ "FlexKomSigStartPos" SG_ 518 MKKey_06 7;
BA_ "FlexKomSigName" SG_ 518 MKKey_06 "IMMO_CODE_RESPONSE_HCP";
BA_ "FlexKomSigLaenge" SG_ 518 MKKey_06 56;
BA_ "FlexKomSID" SG_ 518 MKKey_06 2515;
BA_ "FlexKomIsMotorola" SG_ 518 MKKey_06 1;
BA_ "FlexKomComment" SG_ 518 MKKey_06 "Immobilizer code response packet";
BA_ "RID" SG_ 973 ABS_IND_STAT "6301";
BA_ "GenSigTimeout_ETM" SG_ 973 ABS_IND_STAT 21000;
BA_ "GenSigSNA" SG_ 973 ABS_IND_STAT "3h";
BA_ "GenSigSendType" SG_ 973 ABS_IND_STAT 5;
BA_ "GenSigCycleTime" SG_ 973 ABS_IND_STAT 2000;
BA_ "FlexKomSigStartValue" SG_ 973 ABS_IND_STAT "0000000000000000h";
BA_ "FlexKomSigStartPos" SG_ 973 ABS_IND_STAT 7;
BA_ "FlexKomSigName" SG_ 973 ABS_IND_STAT "IPC_LMPS_Pkt";
BA_ "FlexKomSigLaenge" SG_ 973 ABS_IND_STAT 64;
BA_ "FlexKomSID" SG_ 973 ABS_IND_STAT 2626;
BA_ "FlexKomIsMotorola" SG_ 973 ABS_IND_STAT 1;
BA_ "FlexKomComment" SG_ 973 ABS_IND_STAT "IPC_LMPS packet";
BA_ "RID" SG_ 973 AWD_SERVICE_STAT "6323";
BA_ "GenSigTimeout_ETM" SG_ 973 AWD_SERVICE_STAT 21000;
BA_ "GenSigSNA" SG_ 973 AWD_SERVICE_STAT "3h";
BA_ "GenSigSendType" SG_ 973 AWD_SERVICE_STAT 5;
BA_ "GenSigCycleTime" SG_ 973 AWD_SERVICE_STAT 2000;
BA_ "FlexKomSigStartValue" SG_ 973 AWD_SERVICE_STAT "0000000000000000h";
BA_ "FlexKomSigStartPos" SG_ 973 AWD_SERVICE_STAT 7;
BA_ "FlexKomSigName" SG_ 973 AWD_SERVICE_STAT "IPC_LMPS_Pkt";
BA_ "FlexKomSigLaenge" SG_ 973 AWD_SERVICE_STAT 64;
BA_ "FlexKomSID" SG_ 973 AWD_SERVICE_STAT 2626;
BA_ "FlexKomIsMotorola" SG_ 973 AWD_SERVICE_STAT 1;
BA_ "FlexKomComment" SG_ 973 AWD_SERVICE_STAT "IPC_LMPS packet";
BA_ "RID" SG_ 973 BATTERY_CHARGE_STAT "6327";
BA_ "GenSigTimeout_ETM" SG_ 973 BATTERY_CHARGE_STAT 21000;
BA_ "GenSigSNA" SG_ 973 BATTERY_CHARGE_STAT "3h";
BA_ "GenSigSendType" SG_ 973 BATTERY_CHARGE_STAT 5;
BA_ "GenSigCycleTime" SG_ 973 BATTERY_CHARGE_STAT 2000;
BA_ "FlexKomSigStartValue" SG_ 973 BATTERY_CHARGE_STAT "0000000000000000h";
BA_ "FlexKomSigStartPos" SG_ 973 BATTERY_CHARGE_STAT 7;
BA_ "FlexKomSigName" SG_ 973 BATTERY_CHARGE_STAT "IPC_LMPS_Pkt";
BA_ "FlexKomSigLaenge" SG_ 973 BATTERY_CHARGE_STAT 64;
BA_ "FlexKomSID" SG_ 973 BATTERY_CHARGE_STAT 2626;
BA_ "FlexKomIsMotorola" SG_ 973 BATTERY_CHARGE_STAT 1;
BA_ "FlexKomComment" SG_ 973 BATTERY_CHARGE_STAT "IPC_LMPS packet";
BA_ "RID" SG_ 973 BRAKE_PAD_STAT "6326";
BA_ "GenSigTimeout_ETM" SG_ 973 BRAKE_PAD_STAT 21000;
BA_ "GenSigSNA" SG_ 973 BRAKE_PAD_STAT "3h";
BA_ "GenSigSendType" SG_ 973 BRAKE_PAD_STAT 5;
BA_ "GenSigCycleTime" SG_ 973 BRAKE_PAD_STAT 2000;
BA_ "FlexKomSigStartValue" SG_ 973 BRAKE_PAD_STAT "0000000000000000h";
BA_ "FlexKomSigStartPos" SG_ 973 BRAKE_PAD_STAT 7;
BA_ "FlexKomSigName" SG_ 973 BRAKE_PAD_STAT "IPC_LMPS_Pkt";
BA_ "FlexKomSigLaenge" SG_ 973 BRAKE_PAD_STAT 64;
BA_ "FlexKomSID" SG_ 973 BRAKE_PAD_STAT 2626;
BA_ "FlexKomIsMotorola" SG_ 973 BRAKE_PAD_STAT 1;
BA_ "FlexKomComment" SG_ 973 BRAKE_PAD_STAT "IPC_LMPS packet";
BA_ "RID" SG_ 973 BRK_IND_STAT "6305";
BA_ "GenSigTimeout_ETM" SG_ 973 BRK_IND_STAT 21000;
BA_ "GenSigSNA" SG_ 973 BRK_IND_STAT "3h";
BA_ "GenSigSendType" SG_ 973 BRK_IND_STAT 5;
BA_ "GenSigCycleTime" SG_ 973 BRK_IND_STAT 2000;
BA_ "FlexKomSigStartValue" SG_ 973 BRK_IND_STAT "0000000000000000h";
BA_ "FlexKomSigStartPos" SG_ 973 BRK_IND_STAT 7;
BA_ "FlexKomSigName" SG_ 973 BRK_IND_STAT "IPC_LMPS_Pkt";
BA_ "FlexKomSigLaenge" SG_ 973 BRK_IND_STAT 64;
BA_ "FlexKomSID" SG_ 973 BRK_IND_STAT 2626;
BA_ "FlexKomIsMotorola" SG_ 973 BRK_IND_STAT 1;
BA_ "FlexKomComment" SG_ 973 BRK_IND_STAT "IPC_LMPS packet";
BA_ "RID" SG_ 973 CATALYST_TEMP_STAT "6317";
BA_ "GenSigSNA" SG_ 973 CATALYST_TEMP_STAT "3h";
BA_ "GenSigSendType" SG_ 973 CATALYST_TEMP_STAT 5;
BA_ "GenSigCycleTime" SG_ 973 CATALYST_TEMP_STAT 2000;
BA_ "FlexKomSigStartValue" SG_ 973 CATALYST_TEMP_STAT "0000000000000000h";
BA_ "FlexKomSigStartPos" SG_ 973 CATALYST_TEMP_STAT 7;
BA_ "FlexKomSigName" SG_ 973 CATALYST_TEMP_STAT "IPC_LMPS_Pkt";
BA_ "FlexKomSigLaenge" SG_ 973 CATALYST_TEMP_STAT 64;
BA_ "FlexKomSID" SG_ 973 CATALYST_TEMP_STAT 2626;
BA_ "FlexKomIsMotorola" SG_ 973 CATALYST_TEMP_STAT 1;
BA_ "FlexKomComment" SG_ 973 CATALYST_TEMP_STAT "IPC_LMPS packet";
BA_ "RID" SG_ 973 COOLENT_LEVEL_STAT "6302";
BA_ "GenSigSNA" SG_ 973 COOLENT_LEVEL_STAT "3h";
BA_ "GenSigSendType" SG_ 973 COOLENT_LEVEL_STAT 5;
BA_ "GenSigCycleTime" SG_ 973 COOLENT_LEVEL_STAT 2000;
BA_ "FlexKomSigStartValue" SG_ 973 COOLENT_LEVEL_STAT "0000000000000000h";
BA_ "FlexKomSigStartPos" SG_ 973 COOLENT_LEVEL_STAT 7;
BA_ "FlexKomSigName" SG_ 973 COOLENT_LEVEL_STAT "IPC_LMPS_Pkt";
BA_ "FlexKomSigLaenge" SG_ 973 COOLENT_LEVEL_STAT 64;
BA_ "FlexKomSID" SG_ 973 COOLENT_LEVEL_STAT 2626;
BA_ "FlexKomIsMotorola" SG_ 973 COOLENT_LEVEL_STAT 1;
BA_ "FlexKomComment" SG_ 973 COOLENT_LEVEL_STAT "IPC_LMPS packet";
BA_ "RID" SG_ 973 DAMPING_SYSTEM_STAT "6321";
BA_ "GenSigTimeout_ETM" SG_ 973 DAMPING_SYSTEM_STAT 21000;
BA_ "GenSigSNA" SG_ 973 DAMPING_SYSTEM_STAT "3h";
BA_ "GenSigSendType" SG_ 973 DAMPING_SYSTEM_STAT 5;
BA_ "GenSigCycleTime" SG_ 973 DAMPING_SYSTEM_STAT 2000;
BA_ "FlexKomSigStartValue" SG_ 973 DAMPING_SYSTEM_STAT "0000000000000000h";
BA_ "FlexKomSigStartPos" SG_ 973 DAMPING_SYSTEM_STAT 7;
BA_ "FlexKomSigName" SG_ 973 DAMPING_SYSTEM_STAT "IPC_LMPS_Pkt";
BA_ "FlexKomSigLaenge" SG_ 973 DAMPING_SYSTEM_STAT 64;
BA_ "FlexKomSID" SG_ 973 DAMPING_SYSTEM_STAT 2626;
BA_ "FlexKomIsMotorola" SG_ 973 DAMPING_SYSTEM_STAT 1;
BA_ "FlexKomComment" SG_ 973 DAMPING_SYSTEM_STAT "IPC_LMPS packet";
BA_ "RID" SG_ 973 DEF_STAT "6298";
BA_ "GenSigTimeout_ETM" SG_ 973 DEF_STAT 21000;
BA_ "GenSigSNA" SG_ 973 DEF_STAT "3h";
BA_ "GenSigSendType" SG_ 973 DEF_STAT 5;
BA_ "GenSigCycleTime" SG_ 973 DEF_STAT 2000;
BA_ "FlexKomSigStartValue" SG_ 973 DEF_STAT "0000000000000000h";
BA_ "FlexKomSigStartPos" SG_ 973 DEF_STAT 7;
BA_ "FlexKomSigName" SG_ 973 DEF_STAT "IPC_LMPS_Pkt";
BA_ "FlexKomSigLaenge" SG_ 973 DEF_STAT 64;
BA_ "FlexKomSID" SG_ 973 DEF_STAT 2626;
BA_ "FlexKomIsMotorola" SG_ 973 DEF_STAT 1;
BA_ "FlexKomComment" SG_ 973 DEF_STAT "IPC_LMPS packet";
BA_ "RID" SG_ 973 ELECTRIC_WRENCH_STAT "6324";
BA_ "GenSigSNA" SG_ 973 ELECTRIC_WRENCH_STAT "3h";
BA_ "GenSigSendType" SG_ 973 ELECTRIC_WRENCH_STAT 5;
BA_ "GenSigCycleTime" SG_ 973 ELECTRIC_WRENCH_STAT 2000;
BA_ "FlexKomSigStartValue" SG_ 973 ELECTRIC_WRENCH_STAT "0000000000000000h";
BA_ "FlexKomSigStartPos" SG_ 973 ELECTRIC_WRENCH_STAT 7;
BA_ "FlexKomSigName" SG_ 973 ELECTRIC_WRENCH_STAT "IPC_LMPS_Pkt";
BA_ "FlexKomSigLaenge" SG_ 973 ELECTRIC_WRENCH_STAT 64;
BA_ "FlexKomSID" SG_ 973 ELECTRIC_WRENCH_STAT 2626;
BA_ "FlexKomIsMotorola" SG_ 973 ELECTRIC_WRENCH_STAT 1;
BA_ "FlexKomComment" SG_ 973 ELECTRIC_WRENCH_STAT "IPC_LMPS packet";
BA_ "RID" SG_ 973 ELEC_STAB_STAT "6308";
BA_ "GenSigTimeout_ETM" SG_ 973 ELEC_STAB_STAT 21000;
BA_ "GenSigSNA" SG_ 973 ELEC_STAB_STAT "3h";
BA_ "GenSigSendType" SG_ 973 ELEC_STAB_STAT 5;
BA_ "GenSigCycleTime" SG_ 973 ELEC_STAB_STAT 2000;
BA_ "FlexKomSigStartValue" SG_ 973 ELEC_STAB_STAT "0000000000000000h";
BA_ "FlexKomSigStartPos" SG_ 973 ELEC_STAB_STAT 7;
BA_ "FlexKomSigName" SG_ 973 ELEC_STAB_STAT "IPC_LMPS_Pkt";
BA_ "FlexKomSigLaenge" SG_ 973 ELEC_STAB_STAT 64;
BA_ "FlexKomSID" SG_ 973 ELEC_STAB_STAT 2626;
BA_ "FlexKomIsMotorola" SG_ 973 ELEC_STAB_STAT 1;
BA_ "FlexKomComment" SG_ 973 ELEC_STAB_STAT "IPC_LMPS packet";
BA_ "RID" SG_ 973 ENGINE_MIL_STAT "6306";
BA_ "GenSigTimeout_ETM" SG_ 973 ENGINE_MIL_STAT 21000;
BA_ "GenSigSNA" SG_ 973 ENGINE_MIL_STAT "3h";
BA_ "GenSigSendType" SG_ 973 ENGINE_MIL_STAT 5;
BA_ "GenSigCycleTime" SG_ 973 ENGINE_MIL_STAT 2000;
BA_ "FlexKomSigStartValue" SG_ 973 ENGINE_MIL_STAT "0000000000000000h";
BA_ "FlexKomSigStartPos" SG_ 973 ENGINE_MIL_STAT 7;
BA_ "FlexKomSigName" SG_ 973 ENGINE_MIL_STAT "IPC_LMPS_Pkt";
BA_ "FlexKomSigLaenge" SG_ 973 ENGINE_MIL_STAT 64;
BA_ "FlexKomSID" SG_ 973 ENGINE_MIL_STAT 2626;
BA_ "FlexKomIsMotorola" SG_ 973 ENGINE_MIL_STAT 1;
BA_ "FlexKomComment" SG_ 973 ENGINE_MIL_STAT "IPC_LMPS packet";
BA_ "RID" SG_ 973 ENGINE_TEMP_STAT "6312";
BA_ "GenSigTimeout_ETM" SG_ 973 ENGINE_TEMP_STAT 21000;
BA_ "GenSigSNA" SG_ 973 ENGINE_TEMP_STAT "3h";
BA_ "GenSigSendType" SG_ 973 ENGINE_TEMP_STAT 5;
BA_ "GenSigCycleTime" SG_ 973 ENGINE_TEMP_STAT 2000;
BA_ "FlexKomSigStartValue" SG_ 973 ENGINE_TEMP_STAT "0000000000000000h";
BA_ "FlexKomSigStartPos" SG_ 973 ENGINE_TEMP_STAT 7;
BA_ "FlexKomSigName" SG_ 973 ENGINE_TEMP_STAT "IPC_LMPS_Pkt";
BA_ "FlexKomSigLaenge" SG_ 973 ENGINE_TEMP_STAT 64;
BA_ "FlexKomSID" SG_ 973 ENGINE_TEMP_STAT 2626;
BA_ "FlexKomIsMotorola" SG_ 973 ENGINE_TEMP_STAT 1;
BA_ "FlexKomComment" SG_ 973 ENGINE_TEMP_STAT "IPC_LMPS packet";
BA_ "RID" SG_ 973 EPB_WARN_STAT "6325";
BA_ "GenSigTimeout_ETM" SG_ 973 EPB_WARN_STAT 21000;
BA_ "GenSigSNA" SG_ 973 EPB_WARN_STAT "3h";
BA_ "GenSigSendType" SG_ 973 EPB_WARN_STAT 5;
BA_ "GenSigCycleTime" SG_ 973 EPB_WARN_STAT 2000;
BA_ "FlexKomSigStartValue" SG_ 973 EPB_WARN_STAT "0000000000000000h";
BA_ "FlexKomSigStartPos" SG_ 973 EPB_WARN_STAT 7;
BA_ "FlexKomSigName" SG_ 973 EPB_WARN_STAT "IPC_LMPS_Pkt";
BA_ "FlexKomSigLaenge" SG_ 973 EPB_WARN_STAT 64;
BA_ "FlexKomSID" SG_ 973 EPB_WARN_STAT 2626;
BA_ "FlexKomIsMotorola" SG_ 973 EPB_WARN_STAT 1;
BA_ "FlexKomComment" SG_ 973 EPB_WARN_STAT "IPC_LMPS packet";
BA_ "RID" SG_ 973 EPS_STAT "6310";
BA_ "GenSigTimeout_ETM" SG_ 973 EPS_STAT 21000;
BA_ "GenSigSNA" SG_ 973 EPS_STAT "3h";
BA_ "GenSigSendType" SG_ 973 EPS_STAT 5;
BA_ "GenSigCycleTime" SG_ 973 EPS_STAT 2000;
BA_ "FlexKomSigStartValue" SG_ 973 EPS_STAT "0000000000000000h";
BA_ "FlexKomSigStartPos" SG_ 973 EPS_STAT 7;
BA_ "FlexKomSigName" SG_ 973 EPS_STAT "IPC_LMPS_Pkt";
BA_ "FlexKomSigLaenge" SG_ 973 EPS_STAT 64;
BA_ "FlexKomSID" SG_ 973 EPS_STAT 2626;
BA_ "FlexKomIsMotorola" SG_ 973 EPS_STAT 1;
BA_ "FlexKomComment" SG_ 973 EPS_STAT "IPC_LMPS packet";
BA_ "RID" SG_ 973 ETC_CONTROL_STAT "6311";
BA_ "GenSigTimeout_ETM" SG_ 973 ETC_CONTROL_STAT 21000;
BA_ "GenSigSNA" SG_ 973 ETC_CONTROL_STAT "3h";
BA_ "GenSigSendType" SG_ 973 ETC_CONTROL_STAT 5;
BA_ "GenSigCycleTime" SG_ 973 ETC_CONTROL_STAT 2000;
BA_ "FlexKomSigStartValue" SG_ 973 ETC_CONTROL_STAT "0000000000000000h";
BA_ "FlexKomSigStartPos" SG_ 973 ETC_CONTROL_STAT 7;
BA_ "FlexKomSigName" SG_ 973 ETC_CONTROL_STAT "IPC_LMPS_Pkt";
BA_ "FlexKomSigLaenge" SG_ 973 ETC_CONTROL_STAT 64;
BA_ "FlexKomSID" SG_ 973 ETC_CONTROL_STAT 2626;
BA_ "FlexKomIsMotorola" SG_ 973 ETC_CONTROL_STAT 1;
BA_ "FlexKomComment" SG_ 973 ETC_CONTROL_STAT "IPC_LMPS packet";
BA_ "RID" SG_ 973 FCW_SYSTEM_STAT "6304";
BA_ "GenSigTimeout_ETM" SG_ 973 FCW_SYSTEM_STAT 21000;
BA_ "GenSigSNA" SG_ 973 FCW_SYSTEM_STAT "3h";
BA_ "GenSigSendType" SG_ 973 FCW_SYSTEM_STAT 5;
BA_ "GenSigCycleTime" SG_ 973 FCW_SYSTEM_STAT 2000;
BA_ "FlexKomSigStartValue" SG_ 973 FCW_SYSTEM_STAT "0000000000000000h";
BA_ "FlexKomSigStartPos" SG_ 973 FCW_SYSTEM_STAT 7;
BA_ "FlexKomSigName" SG_ 973 FCW_SYSTEM_STAT "IPC_LMPS_Pkt";
BA_ "FlexKomSigLaenge" SG_ 973 FCW_SYSTEM_STAT 64;
BA_ "FlexKomSID" SG_ 973 FCW_SYSTEM_STAT 2626;
BA_ "FlexKomIsMotorola" SG_ 973 FCW_SYSTEM_STAT 1;
BA_ "FlexKomComment" SG_ 973 FCW_SYSTEM_STAT "IPC_LMPS packet";
BA_ "RID" SG_ 973 FOUR_WD_SERVICE_STAT "6303";
BA_ "GenSigTimeout_ETM" SG_ 973 FOUR_WD_SERVICE_STAT 21000;
BA_ "GenSigSNA" SG_ 973 FOUR_WD_SERVICE_STAT "3h";
BA_ "GenSigSendType" SG_ 973 FOUR_WD_SERVICE_STAT 5;
BA_ "GenSigCycleTime" SG_ 973 FOUR_WD_SERVICE_STAT 2000;
BA_ "FlexKomSigStartValue" SG_ 973 FOUR_WD_SERVICE_STAT "0000000000000000h";
BA_ "FlexKomSigStartPos" SG_ 973 FOUR_WD_SERVICE_STAT 7;
BA_ "FlexKomSigName" SG_ 973 FOUR_WD_SERVICE_STAT "IPC_LMPS_Pkt";
BA_ "FlexKomSigLaenge" SG_ 973 FOUR_WD_SERVICE_STAT 64;
BA_ "FlexKomSID" SG_ 973 FOUR_WD_SERVICE_STAT 2626;
BA_ "FlexKomIsMotorola" SG_ 973 FOUR_WD_SERVICE_STAT 1;
BA_ "FlexKomComment" SG_ 973 FOUR_WD_SERVICE_STAT "IPC_LMPS packet";
BA_ "RID" SG_ 973 FUEL_CAP_STAT "6322";
BA_ "GenSigSNA" SG_ 973 FUEL_CAP_STAT "3h";
BA_ "GenSigSendType" SG_ 973 FUEL_CAP_STAT 5;
BA_ "GenSigCycleTime" SG_ 973 FUEL_CAP_STAT 2000;
BA_ "FlexKomSigStartValue" SG_ 973 FUEL_CAP_STAT "0000000000000000h";
BA_ "FlexKomSigStartPos" SG_ 973 FUEL_CAP_STAT 7;
BA_ "FlexKomSigName" SG_ 973 FUEL_CAP_STAT "IPC_LMPS_Pkt";
BA_ "FlexKomSigLaenge" SG_ 973 FUEL_CAP_STAT 64;
BA_ "FlexKomSID" SG_ 973 FUEL_CAP_STAT 2626;
BA_ "FlexKomIsMotorola" SG_ 973 FUEL_CAP_STAT 1;
BA_ "FlexKomComment" SG_ 973 FUEL_CAP_STAT "IPC_LMPS packet";
BA_ "RID" SG_ 973 LANE_SENSE_STAT "6314";
BA_ "GenSigTimeout_ETM" SG_ 973 LANE_SENSE_STAT 21000;
BA_ "GenSigSNA" SG_ 973 LANE_SENSE_STAT "3h";
BA_ "GenSigSendType" SG_ 973 LANE_SENSE_STAT 5;
BA_ "GenSigCycleTime" SG_ 973 LANE_SENSE_STAT 2000;
BA_ "FlexKomSigStartValue" SG_ 973 LANE_SENSE_STAT "0000000000000000h";
BA_ "FlexKomSigStartPos" SG_ 973 LANE_SENSE_STAT 7;
BA_ "FlexKomSigName" SG_ 973 LANE_SENSE_STAT "IPC_LMPS_Pkt";
BA_ "FlexKomSigLaenge" SG_ 973 LANE_SENSE_STAT 64;
BA_ "FlexKomSID" SG_ 973 LANE_SENSE_STAT 2626;
BA_ "FlexKomIsMotorola" SG_ 973 LANE_SENSE_STAT 1;
BA_ "FlexKomComment" SG_ 973 LANE_SENSE_STAT "IPC_LMPS packet";
BA_ "RID" SG_ 973 OIL_LEVEL_STAT "6307";
BA_ "GenSigSNA" SG_ 973 OIL_LEVEL_STAT "3h";
BA_ "GenSigSendType" SG_ 973 OIL_LEVEL_STAT 5;
BA_ "GenSigCycleTime" SG_ 973 OIL_LEVEL_STAT 2000;
BA_ "FlexKomSigStartValue" SG_ 973 OIL_LEVEL_STAT "0000000000000000h";
BA_ "FlexKomSigStartPos" SG_ 973 OIL_LEVEL_STAT 7;
BA_ "FlexKomSigName" SG_ 973 OIL_LEVEL_STAT "IPC_LMPS_Pkt";
BA_ "FlexKomSigLaenge" SG_ 973 OIL_LEVEL_STAT 64;
BA_ "FlexKomSID" SG_ 973 OIL_LEVEL_STAT 2626;
BA_ "FlexKomIsMotorola" SG_ 973 OIL_LEVEL_STAT 1;
BA_ "FlexKomComment" SG_ 973 OIL_LEVEL_STAT "IPC_LMPS packet";
BA_ "RID" SG_ 973 OIL_PRESSURE_STAT "6316";
BA_ "GenSigTimeout_ETM" SG_ 973 OIL_PRESSURE_STAT 21000;
BA_ "GenSigSNA" SG_ 973 OIL_PRESSURE_STAT "3h";
BA_ "GenSigSendType" SG_ 973 OIL_PRESSURE_STAT 5;
BA_ "GenSigCycleTime" SG_ 973 OIL_PRESSURE_STAT 2000;
BA_ "FlexKomSigStartValue" SG_ 973 OIL_PRESSURE_STAT "0000000000000000h";
BA_ "FlexKomSigStartPos" SG_ 973 OIL_PRESSURE_STAT 7;
BA_ "FlexKomSigName" SG_ 973 OIL_PRESSURE_STAT "IPC_LMPS_Pkt";
BA_ "FlexKomSigLaenge" SG_ 973 OIL_PRESSURE_STAT 64;
BA_ "FlexKomSID" SG_ 973 OIL_PRESSURE_STAT 2626;
BA_ "FlexKomIsMotorola" SG_ 973 OIL_PRESSURE_STAT 1;
BA_ "FlexKomComment" SG_ 973 OIL_PRESSURE_STAT "IPC_LMPS packet";
BA_ "RID" SG_ 973 OIL_TEMP_STAT "6300";
BA_ "GenSigTimeout_ETM" SG_ 973 OIL_TEMP_STAT 21000;
BA_ "GenSigSNA" SG_ 973 OIL_TEMP_STAT "3h";
BA_ "GenSigSendType" SG_ 973 OIL_TEMP_STAT 5;
BA_ "GenSigCycleTime" SG_ 973 OIL_TEMP_STAT 2000;
BA_ "FlexKomSigStartValue" SG_ 973 OIL_TEMP_STAT "0000000000000000h";
BA_ "FlexKomSigStartPos" SG_ 973 OIL_TEMP_STAT 7;
BA_ "FlexKomSigName" SG_ 973 OIL_TEMP_STAT "IPC_LMPS_Pkt";
BA_ "FlexKomSigLaenge" SG_ 973 OIL_TEMP_STAT 64;
BA_ "FlexKomSID" SG_ 973 OIL_TEMP_STAT 2626;
BA_ "FlexKomIsMotorola" SG_ 973 OIL_TEMP_STAT 1;
BA_ "FlexKomComment" SG_ 973 OIL_TEMP_STAT "IPC_LMPS packet";
BA_ "RID" SG_ 973 OVER_TEMP_STAT "6318";
BA_ "GenSigTimeout_ETM" SG_ 973 OVER_TEMP_STAT 21000;
BA_ "GenSigSNA" SG_ 973 OVER_TEMP_STAT "3h";
BA_ "GenSigSendType" SG_ 973 OVER_TEMP_STAT 5;
BA_ "GenSigCycleTime" SG_ 973 OVER_TEMP_STAT 2000;
BA_ "FlexKomSigStartValue" SG_ 973 OVER_TEMP_STAT "0000000000000000h";
BA_ "FlexKomSigStartPos" SG_ 973 OVER_TEMP_STAT 7;
BA_ "FlexKomSigName" SG_ 973 OVER_TEMP_STAT "IPC_LMPS_Pkt";
BA_ "FlexKomSigLaenge" SG_ 973 OVER_TEMP_STAT 64;
BA_ "FlexKomSID" SG_ 973 OVER_TEMP_STAT 2626;
BA_ "FlexKomIsMotorola" SG_ 973 OVER_TEMP_STAT 1;
BA_ "FlexKomComment" SG_ 973 OVER_TEMP_STAT "IPC_LMPS packet";
BA_ "RID" SG_ 973 SERVICE_ACC_STAT "6297";
BA_ "GenSigTimeout_ETM" SG_ 973 SERVICE_ACC_STAT 21000;
BA_ "GenSigSNA" SG_ 973 SERVICE_ACC_STAT "3h";
BA_ "GenSigSendType" SG_ 973 SERVICE_ACC_STAT 5;
BA_ "GenSigCycleTime" SG_ 973 SERVICE_ACC_STAT 2000;
BA_ "FlexKomSigStartValue" SG_ 973 SERVICE_ACC_STAT "0000000000000000h";
BA_ "FlexKomSigStartPos" SG_ 973 SERVICE_ACC_STAT 7;
BA_ "FlexKomSigName" SG_ 973 SERVICE_ACC_STAT "IPC_LMPS_Pkt";
BA_ "FlexKomSigLaenge" SG_ 973 SERVICE_ACC_STAT 64;
BA_ "FlexKomSID" SG_ 973 SERVICE_ACC_STAT 2626;
BA_ "FlexKomIsMotorola" SG_ 973 SERVICE_ACC_STAT 1;
BA_ "FlexKomComment" SG_ 973 SERVICE_ACC_STAT "IPC_LMPS packet";
BA_ "RID" SG_ 973 SERVICE_STAT "6319";
BA_ "GenSigTimeout_ETM" SG_ 973 SERVICE_STAT 21000;
BA_ "GenSigSNA" SG_ 973 SERVICE_STAT "3h";
BA_ "GenSigSendType" SG_ 973 SERVICE_STAT 5;
BA_ "GenSigCycleTime" SG_ 973 SERVICE_STAT 2000;
BA_ "FlexKomSigStartValue" SG_ 973 SERVICE_STAT "0000000000000000h";
BA_ "FlexKomSigStartPos" SG_ 973 SERVICE_STAT 7;
BA_ "FlexKomSigName" SG_ 973 SERVICE_STAT "IPC_LMPS_Pkt";
BA_ "FlexKomSigLaenge" SG_ 973 SERVICE_STAT 64;
BA_ "FlexKomSID" SG_ 973 SERVICE_STAT 2626;
BA_ "FlexKomIsMotorola" SG_ 973 SERVICE_STAT 1;
BA_ "FlexKomComment" SG_ 973 SERVICE_STAT "IPC_LMPS packet";
BA_ "RID" SG_ 973 STOP_START_STAT "6315";
BA_ "GenSigTimeout_ETM" SG_ 973 STOP_START_STAT 21000;
BA_ "GenSigSNA" SG_ 973 STOP_START_STAT "3h";
BA_ "GenSigSendType" SG_ 973 STOP_START_STAT 5;
BA_ "GenSigCycleTime" SG_ 973 STOP_START_STAT 2000;
BA_ "FlexKomSigStartValue" SG_ 973 STOP_START_STAT "0000000000000000h";
BA_ "FlexKomSigStartPos" SG_ 973 STOP_START_STAT 7;
BA_ "FlexKomSigName" SG_ 973 STOP_START_STAT "IPC_LMPS_Pkt";
BA_ "FlexKomSigLaenge" SG_ 973 STOP_START_STAT 64;
BA_ "FlexKomSID" SG_ 973 STOP_START_STAT 2626;
BA_ "FlexKomIsMotorola" SG_ 973 STOP_START_STAT 1;
BA_ "FlexKomComment" SG_ 973 STOP_START_STAT "IPC_LMPS packet";
BA_ "RID" SG_ 973 TIRE_PRESSURE_STAT "6313";
BA_ "GenSigTimeout_ETM" SG_ 973 TIRE_PRESSURE_STAT 21000;
BA_ "GenSigSNA" SG_ 973 TIRE_PRESSURE_STAT "3h";
BA_ "GenSigSendType" SG_ 973 TIRE_PRESSURE_STAT 5;
BA_ "GenSigCycleTime" SG_ 973 TIRE_PRESSURE_STAT 2000;
BA_ "FlexKomSigStartValue" SG_ 973 TIRE_PRESSURE_STAT "0000000000000000h";
BA_ "FlexKomSigStartPos" SG_ 973 TIRE_PRESSURE_STAT 7;
BA_ "FlexKomSigName" SG_ 973 TIRE_PRESSURE_STAT "IPC_LMPS_Pkt";
BA_ "FlexKomSigLaenge" SG_ 973 TIRE_PRESSURE_STAT 64;
BA_ "FlexKomSID" SG_ 973 TIRE_PRESSURE_STAT 2626;
BA_ "FlexKomIsMotorola" SG_ 973 TIRE_PRESSURE_STAT 1;
BA_ "FlexKomComment" SG_ 973 TIRE_PRESSURE_STAT "IPC_LMPS packet";
BA_ "RID" SG_ 973 TORQUE_STAT "6320";
BA_ "GenSigSNA" SG_ 973 TORQUE_STAT "3h";
BA_ "GenSigSendType" SG_ 973 TORQUE_STAT 5;
BA_ "GenSigCycleTime" SG_ 973 TORQUE_STAT 2000;
BA_ "FlexKomSigStartValue" SG_ 973 TORQUE_STAT "0000000000000000h";
BA_ "FlexKomSigStartPos" SG_ 973 TORQUE_STAT 7;
BA_ "FlexKomSigName" SG_ 973 TORQUE_STAT "IPC_LMPS_Pkt";
BA_ "FlexKomSigLaenge" SG_ 973 TORQUE_STAT 64;
BA_ "FlexKomSID" SG_ 973 TORQUE_STAT 2626;
BA_ "FlexKomIsMotorola" SG_ 973 TORQUE_STAT 1;
BA_ "FlexKomComment" SG_ 973 TORQUE_STAT "IPC_LMPS packet";
BA_ "RID" SG_ 973 WATER_IN_FUEL_STAT "6309";
BA_ "GenSigTimeout_ETM" SG_ 973 WATER_IN_FUEL_STAT 21000;
BA_ "GenSigSNA" SG_ 973 WATER_IN_FUEL_STAT "3h";
BA_ "GenSigSendType" SG_ 973 WATER_IN_FUEL_STAT 5;
BA_ "GenSigCycleTime" SG_ 973 WATER_IN_FUEL_STAT 2000;
BA_ "FlexKomSigStartValue" SG_ 973 WATER_IN_FUEL_STAT "0000000000000000h";
BA_ "FlexKomSigStartPos" SG_ 973 WATER_IN_FUEL_STAT 7;
BA_ "FlexKomSigName" SG_ 973 WATER_IN_FUEL_STAT "IPC_LMPS_Pkt";
BA_ "FlexKomSigLaenge" SG_ 973 WATER_IN_FUEL_STAT 64;
BA_ "FlexKomSID" SG_ 973 WATER_IN_FUEL_STAT 2626;
BA_ "FlexKomIsMotorola" SG_ 973 WATER_IN_FUEL_STAT 1;
BA_ "FlexKomComment" SG_ 973 WATER_IN_FUEL_STAT "IPC_LMPS packet";
BA_ "RID" SG_ 973 WINDSHIELD_FLUID_STAT "6299";
BA_ "GenSigSNA" SG_ 973 WINDSHIELD_FLUID_STAT "3h";
BA_ "GenSigSendType" SG_ 973 WINDSHIELD_FLUID_STAT 5;
BA_ "GenSigCycleTime" SG_ 973 WINDSHIELD_FLUID_STAT 2000;
BA_ "FlexKomSigStartValue" SG_ 973 WINDSHIELD_FLUID_STAT "0000000000000000h";
BA_ "FlexKomSigStartPos" SG_ 973 WINDSHIELD_FLUID_STAT 7;
BA_ "FlexKomSigName" SG_ 973 WINDSHIELD_FLUID_STAT "IPC_LMPS_Pkt";
BA_ "FlexKomSigLaenge" SG_ 973 WINDSHIELD_FLUID_STAT 64;
BA_ "FlexKomSID" SG_ 973 WINDSHIELD_FLUID_STAT 2626;
BA_ "FlexKomIsMotorola" SG_ 973 WINDSHIELD_FLUID_STAT 1;
BA_ "FlexKomComment" SG_ 973 WINDSHIELD_FLUID_STAT "IPC_LMPS packet";
BA_ "GenSigSNA" SG_ 868 MESS_TPM1 "0h";
BA_ "GenSigSendType" SG_ 868 MESS_TPM1 1;
BA_ "FlexKomSigStartValue" SG_ 868 MESS_TPM1 "0000000000000000h";
BA_ "FlexKomSigStartPos" SG_ 868 MESS_TPM1 7;
BA_ "FlexKomSigName" SG_ 868 MESS_TPM1 "MESS_TPM1";
BA_ "FlexKomSigLaenge" SG_ 868 MESS_TPM1 64;
BA_ "FlexKomSID" SG_ 868 MESS_TPM1 867;
BA_ "FlexKomIsMotorola" SG_ 868 MESS_TPM1 1;
BA_ "FlexKomComment" SG_ 868 MESS_TPM1 "Measurement data";
BA_ "RID" SG_ 956 NAV_GrpNum "1187";
BA_ "GenSigSNA" SG_ 956 NAV_GrpNum "0h";
BA_ "GenSigSendType" SG_ 956 NAV_GrpNum 1;
BA_ "FlexKomSigStartValue" SG_ 956 NAV_GrpNum "0000000000000000h";
BA_ "FlexKomSigStartPos" SG_ 956 NAV_GrpNum 7;
BA_ "FlexKomSigName" SG_ 956 NAV_GrpNum "NAV_DATA";
BA_ "FlexKomSigLaenge" SG_ 956 NAV_GrpNum 64;
BA_ "FlexKomSID" SG_ 956 NAV_GrpNum 576;
BA_ "FlexKomIsMotorola" SG_ 956 NAV_GrpNum 1;
BA_ "FlexKomComment" SG_ 956 NAV_GrpNum "Text data packet transfer from NAV";
BA_ "RID" SG_ 956 NAV_GrpTyp "1272";
BA_ "GenSigSNA" SG_ 956 NAV_GrpTyp "3Fh";
BA_ "GenSigSendType" SG_ 956 NAV_GrpTyp 1;
BA_ "FlexKomSigStartValue" SG_ 956 NAV_GrpTyp "0000000000000000h";
BA_ "FlexKomSigStartPos" SG_ 956 NAV_GrpTyp 7;
BA_ "FlexKomSigName" SG_ 956 NAV_GrpTyp "NAV_DATA";
BA_ "FlexKomSigLaenge" SG_ 956 NAV_GrpTyp 64;
BA_ "FlexKomSID" SG_ 956 NAV_GrpTyp 576;
BA_ "FlexKomIsMotorola" SG_ 956 NAV_GrpTyp 1;
BA_ "FlexKomComment" SG_ 956 NAV_GrpTyp "Text data packet transfer from NAV";
BA_ "RID" SG_ 956 NAV_HiGrpMark "1176";
BA_ "GenSigSNA" SG_ 956 NAV_HiGrpMark "0h";
BA_ "GenSigSendType" SG_ 956 NAV_HiGrpMark 1;
BA_ "FlexKomSigStartValue" SG_ 956 NAV_HiGrpMark "0000000000000000h";
BA_ "FlexKomSigStartPos" SG_ 956 NAV_HiGrpMark 7;
BA_ "FlexKomSigName" SG_ 956 NAV_HiGrpMark "NAV_DATA";
BA_ "FlexKomSigLaenge" SG_ 956 NAV_HiGrpMark 64;
BA_ "FlexKomSID" SG_ 956 NAV_HiGrpMark 576;
BA_ "FlexKomIsMotorola" SG_ 956 NAV_HiGrpMark 1;
BA_ "FlexKomComment" SG_ 956 NAV_HiGrpMark "Text data packet transfer from NAV";
BA_ "RID" SG_ 956 NAV_TEXT "1051";
BA_ "GenSigSNA" SG_ 956 NAV_TEXT "0h";
BA_ "GenSigSendType" SG_ 956 NAV_TEXT 1;
BA_ "FlexKomSigStartValue" SG_ 956 NAV_TEXT "0000000000000000h";
BA_ "FlexKomSigStartPos" SG_ 956 NAV_TEXT 7;
BA_ "FlexKomSigName" SG_ 956 NAV_TEXT "NAV_DATA";
BA_ "FlexKomSigLaenge" SG_ 956 NAV_TEXT 64;
BA_ "FlexKomSID" SG_ 956 NAV_TEXT 576;
BA_ "FlexKomIsMotorola" SG_ 956 NAV_TEXT 1;
BA_ "FlexKomComment" SG_ 956 NAV_TEXT "Text data packet transfer from NAV";
BA_ "GenSigTimeout_RF_HUB" SG_ 926 NET_CFG_STAT_ePT 21000;
BA_ "GenSigStartValue" SG_ 926 NET_CFG_STAT_ePT 3;
BA_ "GenSigSNA" SG_ 926 NET_CFG_STAT_ePT "3h";
BA_ "GenSigSendType" SG_ 926 NET_CFG_STAT_ePT 5;
BA_ "GenSigCycleTime" SG_ 926 NET_CFG_STAT_ePT 2000;
BA_ "FlexKomSigStartValue" SG_ 926 NET_CFG_STAT_ePT "030000h";
BA_ "FlexKomSigStartPos" SG_ 926 NET_CFG_STAT_ePT 7;
BA_ "FlexKomSigName" SG_ 926 NET_CFG_STAT_ePT "NET_CFG_DATA_ePT";
BA_ "FlexKomSigLaenge" SG_ 926 NET_CFG_STAT_ePT 24;
BA_ "FlexKomSID" SG_ 926 NET_CFG_STAT_ePT 2469;
BA_ "FlexKomIsMotorola" SG_ 926 NET_CFG_STAT_ePT 1;
BA_ "FlexKomComment" SG_ 926 NET_CFG_STAT_ePT "Network ECU config data for hybrid bus";
BA_ "GenSigTimeout_RF_HUB" SG_ 926 NetCfg_AHCP_ePT 21000;
BA_ "GenSigSNA" SG_ 926 NetCfg_AHCP_ePT "0h";
BA_ "GenSigSendType" SG_ 926 NetCfg_AHCP_ePT 5;
BA_ "GenSigCycleTime" SG_ 926 NetCfg_AHCP_ePT 2000;
BA_ "FlexKomSigStartValue" SG_ 926 NetCfg_AHCP_ePT "030000h";
BA_ "FlexKomSigStartPos" SG_ 926 NetCfg_AHCP_ePT 7;
BA_ "FlexKomSigName" SG_ 926 NetCfg_AHCP_ePT "NET_CFG_DATA_ePT";
BA_ "FlexKomSigLaenge" SG_ 926 NetCfg_AHCP_ePT 24;
BA_ "FlexKomSID" SG_ 926 NetCfg_AHCP_ePT 2469;
BA_ "FlexKomIsMotorola" SG_ 926 NetCfg_AHCP_ePT 1;
BA_ "FlexKomComment" SG_ 926 NetCfg_AHCP_ePT "Network ECU config data for hybrid bus";
BA_ "GenSigTimeout_RF_HUB" SG_ 926 NetCfg_APM_ePT 21000;
BA_ "GenSigSNA" SG_ 926 NetCfg_APM_ePT "0h";
BA_ "GenSigSendType" SG_ 926 NetCfg_APM_ePT 5;
BA_ "GenSigCycleTime" SG_ 926 NetCfg_APM_ePT 2000;
BA_ "FlexKomSigStartValue" SG_ 926 NetCfg_APM_ePT "030000h";
BA_ "FlexKomSigStartPos" SG_ 926 NetCfg_APM_ePT 7;
BA_ "FlexKomSigName" SG_ 926 NetCfg_APM_ePT "NET_CFG_DATA_ePT";
BA_ "FlexKomSigLaenge" SG_ 926 NetCfg_APM_ePT 24;
BA_ "FlexKomSID" SG_ 926 NetCfg_APM_ePT 2469;
BA_ "FlexKomIsMotorola" SG_ 926 NetCfg_APM_ePT 1;
BA_ "FlexKomComment" SG_ 926 NetCfg_APM_ePT "Network ECU config data for hybrid bus";
BA_ "GenSigTimeout_RF_HUB" SG_ 926 NetCfg_BPCM_ePT 21000;
BA_ "GenSigSNA" SG_ 926 NetCfg_BPCM_ePT "0h";
BA_ "GenSigSendType" SG_ 926 NetCfg_BPCM_ePT 5;
BA_ "GenSigCycleTime" SG_ 926 NetCfg_BPCM_ePT 2000;
BA_ "FlexKomSigStartValue" SG_ 926 NetCfg_BPCM_ePT "030000h";
BA_ "FlexKomSigStartPos" SG_ 926 NetCfg_BPCM_ePT 7;
BA_ "FlexKomSigName" SG_ 926 NetCfg_BPCM_ePT "NET_CFG_DATA_ePT";
BA_ "FlexKomSigLaenge" SG_ 926 NetCfg_BPCM_ePT 24;
BA_ "FlexKomSID" SG_ 926 NetCfg_BPCM_ePT 2469;
BA_ "FlexKomIsMotorola" SG_ 926 NetCfg_BPCM_ePT 1;
BA_ "FlexKomComment" SG_ 926 NetCfg_BPCM_ePT "Network ECU config data for hybrid bus";
BA_ "GenSigSNA" SG_ 926 NetCfg_BSMO_ePT "0h";
BA_ "GenSigSendType" SG_ 926 NetCfg_BSMO_ePT 5;
BA_ "GenSigCycleTime" SG_ 926 NetCfg_BSMO_ePT 2000;
BA_ "FlexKomSigStartValue" SG_ 926 NetCfg_BSMO_ePT "030000h";
BA_ "FlexKomSigStartPos" SG_ 926 NetCfg_BSMO_ePT 7;
BA_ "FlexKomSigName" SG_ 926 NetCfg_BSMO_ePT "NET_CFG_DATA_ePT";
BA_ "FlexKomSigLaenge" SG_ 926 NetCfg_BSMO_ePT 24;
BA_ "FlexKomSID" SG_ 926 NetCfg_BSMO_ePT 2469;
BA_ "FlexKomIsMotorola" SG_ 926 NetCfg_BSMO_ePT 1;
BA_ "FlexKomComment" SG_ 926 NetCfg_BSMO_ePT "Network ECU config data for hybrid bus";
BA_ "GenSigTimeout_RF_HUB" SG_ 926 NetCfg_EAC_ePT 21000;
BA_ "GenSigSNA" SG_ 926 NetCfg_EAC_ePT "0h";
BA_ "GenSigSendType" SG_ 926 NetCfg_EAC_ePT 5;
BA_ "GenSigCycleTime" SG_ 926 NetCfg_EAC_ePT 2000;
BA_ "FlexKomSigStartValue" SG_ 926 NetCfg_EAC_ePT "030000h";
BA_ "FlexKomSigStartPos" SG_ 926 NetCfg_EAC_ePT 7;
BA_ "FlexKomSigName" SG_ 926 NetCfg_EAC_ePT "NET_CFG_DATA_ePT";
BA_ "FlexKomSigLaenge" SG_ 926 NetCfg_EAC_ePT 24;
BA_ "FlexKomSID" SG_ 926 NetCfg_EAC_ePT 2469;
BA_ "FlexKomIsMotorola" SG_ 926 NetCfg_EAC_ePT 1;
BA_ "FlexKomComment" SG_ 926 NetCfg_EAC_ePT "Network ECU config data for hybrid bus";
BA_ "GenSigTimeout_RF_HUB" SG_ 926 NetCfg_EBCM_ePT 21000;
BA_ "GenSigSNA" SG_ 926 NetCfg_EBCM_ePT "0h";
BA_ "GenSigSendType" SG_ 926 NetCfg_EBCM_ePT 5;
BA_ "GenSigCycleTime" SG_ 926 NetCfg_EBCM_ePT 2000;
BA_ "FlexKomSigStartValue" SG_ 926 NetCfg_EBCM_ePT "030000h";
BA_ "FlexKomSigStartPos" SG_ 926 NetCfg_EBCM_ePT 7;
BA_ "FlexKomSigName" SG_ 926 NetCfg_EBCM_ePT "NET_CFG_DATA_ePT";
BA_ "FlexKomSigLaenge" SG_ 926 NetCfg_EBCM_ePT 24;
BA_ "FlexKomSID" SG_ 926 NetCfg_EBCM_ePT 2469;
BA_ "FlexKomIsMotorola" SG_ 926 NetCfg_EBCM_ePT 1;
BA_ "FlexKomComment" SG_ 926 NetCfg_EBCM_ePT "Network ECU config data for hybrid bus";
BA_ "GenSigTimeout_RF_HUB" SG_ 926 NetCfg_ECM_ePT 21000;
BA_ "GenSigSNA" SG_ 926 NetCfg_ECM_ePT "0h";
BA_ "GenSigSendType" SG_ 926 NetCfg_ECM_ePT 5;
BA_ "GenSigCycleTime" SG_ 926 NetCfg_ECM_ePT 2000;
BA_ "FlexKomSigStartValue" SG_ 926 NetCfg_ECM_ePT "030000h";
BA_ "FlexKomSigStartPos" SG_ 926 NetCfg_ECM_ePT 7;
BA_ "FlexKomSigName" SG_ 926 NetCfg_ECM_ePT "NET_CFG_DATA_ePT";
BA_ "FlexKomSigLaenge" SG_ 926 NetCfg_ECM_ePT 24;
BA_ "FlexKomSID" SG_ 926 NetCfg_ECM_ePT 2469;
BA_ "FlexKomIsMotorola" SG_ 926 NetCfg_ECM_ePT 1;
BA_ "FlexKomComment" SG_ 926 NetCfg_ECM_ePT "Network ECU config data for hybrid bus";
BA_ "GenSigTimeout_RF_HUB" SG_ 926 NetCfg_ESC_ePT 21000;
BA_ "GenSigSNA" SG_ 926 NetCfg_ESC_ePT "0h";
BA_ "GenSigSendType" SG_ 926 NetCfg_ESC_ePT 5;
BA_ "GenSigCycleTime" SG_ 926 NetCfg_ESC_ePT 2000;
BA_ "FlexKomSigStartValue" SG_ 926 NetCfg_ESC_ePT "030000h";
BA_ "FlexKomSigStartPos" SG_ 926 NetCfg_ESC_ePT 7;
BA_ "FlexKomSigName" SG_ 926 NetCfg_ESC_ePT "NET_CFG_DATA_ePT";
BA_ "FlexKomSigLaenge" SG_ 926 NetCfg_ESC_ePT 24;
BA_ "FlexKomSID" SG_ 926 NetCfg_ESC_ePT 2469;
BA_ "FlexKomIsMotorola" SG_ 926 NetCfg_ESC_ePT 1;
BA_ "FlexKomComment" SG_ 926 NetCfg_ESC_ePT "Network ECU config data for hybrid bus";
BA_ "GenSigTimeout_RF_HUB" SG_ 926 NetCfg_ESM_ePT 21000;
BA_ "GenSigSNA" SG_ 926 NetCfg_ESM_ePT "0h";
BA_ "GenSigSendType" SG_ 926 NetCfg_ESM_ePT 5;
BA_ "GenSigCycleTime" SG_ 926 NetCfg_ESM_ePT 2000;
BA_ "FlexKomSigStartValue" SG_ 926 NetCfg_ESM_ePT "030000h";
BA_ "FlexKomSigStartPos" SG_ 926 NetCfg_ESM_ePT 7;
BA_ "FlexKomSigName" SG_ 926 NetCfg_ESM_ePT "NET_CFG_DATA_ePT";
BA_ "FlexKomSigLaenge" SG_ 926 NetCfg_ESM_ePT 24;
BA_ "FlexKomSID" SG_ 926 NetCfg_ESM_ePT 2469;
BA_ "FlexKomIsMotorola" SG_ 926 NetCfg_ESM_ePT 1;
BA_ "FlexKomComment" SG_ 926 NetCfg_ESM_ePT "Network ECU config data for hybrid bus";
BA_ "GenSigTimeout_RF_HUB" SG_ 926 NetCfg_HCP_ePT 21000;
BA_ "GenSigSNA" SG_ 926 NetCfg_HCP_ePT "0h";
BA_ "GenSigSendType" SG_ 926 NetCfg_HCP_ePT 5;
BA_ "GenSigCycleTime" SG_ 926 NetCfg_HCP_ePT 2000;
BA_ "FlexKomSigStartValue" SG_ 926 NetCfg_HCP_ePT "030000h";
BA_ "FlexKomSigStartPos" SG_ 926 NetCfg_HCP_ePT 7;
BA_ "FlexKomSigName" SG_ 926 NetCfg_HCP_ePT "NET_CFG_DATA_ePT";
BA_ "FlexKomSigLaenge" SG_ 926 NetCfg_HCP_ePT 24;
BA_ "FlexKomSID" SG_ 926 NetCfg_HCP_ePT 2469;
BA_ "FlexKomIsMotorola" SG_ 926 NetCfg_HCP_ePT 1;
BA_ "FlexKomComment" SG_ 926 NetCfg_HCP_ePT "Network ECU config data for hybrid bus";
BA_ "GenSigSNA" SG_ 926 NetCfg_IDCM_ePT "0h";
BA_ "GenSigSendType" SG_ 926 NetCfg_IDCM_ePT 5;
BA_ "GenSigCycleTime" SG_ 926 NetCfg_IDCM_ePT 2000;
BA_ "FlexKomSigStartValue" SG_ 926 NetCfg_IDCM_ePT "030000h";
BA_ "FlexKomSigStartPos" SG_ 926 NetCfg_IDCM_ePT 7;
BA_ "FlexKomSigName" SG_ 926 NetCfg_IDCM_ePT "NET_CFG_DATA_ePT";
BA_ "FlexKomSigLaenge" SG_ 926 NetCfg_IDCM_ePT 24;
BA_ "FlexKomSID" SG_ 926 NetCfg_IDCM_ePT 2469;
BA_ "FlexKomIsMotorola" SG_ 926 NetCfg_IDCM_ePT 1;
BA_ "FlexKomComment" SG_ 926 NetCfg_IDCM_ePT "Network ECU config data for hybrid bus";
BA_ "GenSigSNA" SG_ 926 NetCfg_MCPA_ePT "0h";
BA_ "GenSigSendType" SG_ 926 NetCfg_MCPA_ePT 5;
BA_ "GenSigCycleTime" SG_ 926 NetCfg_MCPA_ePT 2000;
BA_ "FlexKomSigStartValue" SG_ 926 NetCfg_MCPA_ePT "030000h";
BA_ "FlexKomSigStartPos" SG_ 926 NetCfg_MCPA_ePT 7;
BA_ "FlexKomSigName" SG_ 926 NetCfg_MCPA_ePT "NET_CFG_DATA_ePT";
BA_ "FlexKomSigLaenge" SG_ 926 NetCfg_MCPA_ePT 24;
BA_ "FlexKomSID" SG_ 926 NetCfg_MCPA_ePT 2469;
BA_ "FlexKomIsMotorola" SG_ 926 NetCfg_MCPA_ePT 1;
BA_ "FlexKomComment" SG_ 926 NetCfg_MCPA_ePT "Network ECU config data for hybrid bus";
BA_ "GenSigTimeout_RF_HUB" SG_ 926 NetCfg_OBCM_ePT 21000;
BA_ "GenSigSNA" SG_ 926 NetCfg_OBCM_ePT "0h";
BA_ "GenSigSendType" SG_ 926 NetCfg_OBCM_ePT 5;
BA_ "GenSigCycleTime" SG_ 926 NetCfg_OBCM_ePT 2000;
BA_ "FlexKomSigStartValue" SG_ 926 NetCfg_OBCM_ePT "030000h";
BA_ "FlexKomSigStartPos" SG_ 926 NetCfg_OBCM_ePT 7;
BA_ "FlexKomSigName" SG_ 926 NetCfg_OBCM_ePT "NET_CFG_DATA_ePT";
BA_ "FlexKomSigLaenge" SG_ 926 NetCfg_OBCM_ePT 24;
BA_ "FlexKomSID" SG_ 926 NetCfg_OBCM_ePT 2469;
BA_ "FlexKomIsMotorola" SG_ 926 NetCfg_OBCM_ePT 1;
BA_ "FlexKomComment" SG_ 926 NetCfg_OBCM_ePT "Network ECU config data for hybrid bus";
BA_ "GenSigTimeout_RF_HUB" SG_ 926 NetCfg_ORC_ePT 21000;
BA_ "GenSigSNA" SG_ 926 NetCfg_ORC_ePT "0h";
BA_ "GenSigSendType" SG_ 926 NetCfg_ORC_ePT 5;
BA_ "GenSigCycleTime" SG_ 926 NetCfg_ORC_ePT 2000;
BA_ "FlexKomSigStartValue" SG_ 926 NetCfg_ORC_ePT "030000h";
BA_ "FlexKomSigStartPos" SG_ 926 NetCfg_ORC_ePT 7;
BA_ "FlexKomSigName" SG_ 926 NetCfg_ORC_ePT "NET_CFG_DATA_ePT";
BA_ "FlexKomSigLaenge" SG_ 926 NetCfg_ORC_ePT 24;
BA_ "FlexKomSID" SG_ 926 NetCfg_ORC_ePT 2469;
BA_ "FlexKomIsMotorola" SG_ 926 NetCfg_ORC_ePT 1;
BA_ "FlexKomComment" SG_ 926 NetCfg_ORC_ePT "Network ECU config data for hybrid bus";
BA_ "GenSigTimeout_RF_HUB" SG_ 926 NetCfg_SCA_ePT 21000;
BA_ "GenSigSNA" SG_ 926 NetCfg_SCA_ePT "0h";
BA_ "GenSigSendType" SG_ 926 NetCfg_SCA_ePT 5;
BA_ "GenSigCycleTime" SG_ 926 NetCfg_SCA_ePT 2000;
BA_ "FlexKomSigStartValue" SG_ 926 NetCfg_SCA_ePT "030000h";
BA_ "FlexKomSigStartPos" SG_ 926 NetCfg_SCA_ePT 7;
BA_ "FlexKomSigName" SG_ 926 NetCfg_SCA_ePT "NET_CFG_DATA_ePT";
BA_ "FlexKomSigLaenge" SG_ 926 NetCfg_SCA_ePT 24;
BA_ "FlexKomSID" SG_ 926 NetCfg_SCA_ePT 2469;
BA_ "FlexKomIsMotorola" SG_ 926 NetCfg_SCA_ePT 1;
BA_ "FlexKomComment" SG_ 926 NetCfg_SCA_ePT "Network ECU config data for hybrid bus";
BA_ "GenSigTimeout_RF_HUB" SG_ 995 NET_CFG_STAT_INT 21000;
BA_ "GenSigTimeout_IC" SG_ 995 NET_CFG_STAT_INT 21000;
BA_ "GenSigStartValue" SG_ 995 NET_CFG_STAT_INT 3;
BA_ "GenSigSNA" SG_ 995 NET_CFG_STAT_INT "3h";
BA_ "GenSigSendType" SG_ 995 NET_CFG_STAT_INT 5;
BA_ "GenSigCycleTime" SG_ 995 NET_CFG_STAT_INT 2000;
BA_ "FlexKomSigStartValue" SG_ 995 NET_CFG_STAT_INT "0300000000000000h";
BA_ "FlexKomSigStartPos" SG_ 995 NET_CFG_STAT_INT 7;
BA_ "FlexKomSigName" SG_ 995 NET_CFG_STAT_INT "NET_CFG_DATA_INT";
BA_ "FlexKomSigLaenge" SG_ 995 NET_CFG_STAT_INT 64;
BA_ "FlexKomSID" SG_ 995 NET_CFG_STAT_INT 38;
BA_ "FlexKomIsMotorola" SG_ 995 NET_CFG_STAT_INT 1;
BA_ "FlexKomComment" SG_ 995 NET_CFG_STAT_INT "Network ECU config data for interior";
BA_ "GenSigTimeout_RF_HUB" SG_ 995 NetCfg_AMP_I 21000;
BA_ "GenSigSNA" SG_ 995 NetCfg_AMP_I "0h";
BA_ "GenSigSendType" SG_ 995 NetCfg_AMP_I 5;
BA_ "GenSigCycleTime" SG_ 995 NetCfg_AMP_I 2000;
BA_ "FlexKomSigStartValue" SG_ 995 NetCfg_AMP_I "0300000000000000h";
BA_ "FlexKomSigStartPos" SG_ 995 NetCfg_AMP_I 7;
BA_ "FlexKomSigName" SG_ 995 NetCfg_AMP_I "NET_CFG_DATA_INT";
BA_ "FlexKomSigLaenge" SG_ 995 NetCfg_AMP_I 64;
BA_ "FlexKomSID" SG_ 995 NetCfg_AMP_I 38;
BA_ "FlexKomIsMotorola" SG_ 995 NetCfg_AMP_I 1;
BA_ "FlexKomComment" SG_ 995 NetCfg_AMP_I "Network ECU config data for interior";
BA_ "GenSigTimeout_RF_HUB" SG_ 995 NetCfg_ANC_I 21000;
BA_ "GenSigSNA" SG_ 995 NetCfg_ANC_I "0h";
BA_ "GenSigSendType" SG_ 995 NetCfg_ANC_I 5;
BA_ "GenSigCycleTime" SG_ 995 NetCfg_ANC_I 2000;
BA_ "FlexKomSigStartValue" SG_ 995 NetCfg_ANC_I "0300000000000000h";
BA_ "FlexKomSigStartPos" SG_ 995 NetCfg_ANC_I 7;
BA_ "FlexKomSigName" SG_ 995 NetCfg_ANC_I "NET_CFG_DATA_INT";
BA_ "FlexKomSigLaenge" SG_ 995 NetCfg_ANC_I 64;
BA_ "FlexKomSID" SG_ 995 NetCfg_ANC_I 38;
BA_ "FlexKomIsMotorola" SG_ 995 NetCfg_ANC_I 1;
BA_ "FlexKomComment" SG_ 995 NetCfg_ANC_I "Network ECU config data for interior";
BA_ "GenSigTimeout_RF_HUB" SG_ 995 NetCfg_BSM 21000;
BA_ "GenSigTimeout_IC" SG_ 995 NetCfg_BSM 21000;
BA_ "GenSigSNA" SG_ 995 NetCfg_BSM "0h";
BA_ "GenSigSendType" SG_ 995 NetCfg_BSM 5;
BA_ "GenSigCycleTime" SG_ 995 NetCfg_BSM 2000;
BA_ "FlexKomSigStartValue" SG_ 995 NetCfg_BSM "0300000000000000h";
BA_ "FlexKomSigStartPos" SG_ 995 NetCfg_BSM 7;
BA_ "FlexKomSigName" SG_ 995 NetCfg_BSM "NET_CFG_DATA_INT";
BA_ "FlexKomSigLaenge" SG_ 995 NetCfg_BSM 64;
BA_ "FlexKomSID" SG_ 995 NetCfg_BSM 38;
BA_ "FlexKomIsMotorola" SG_ 995 NetCfg_BSM 1;
BA_ "FlexKomComment" SG_ 995 NetCfg_BSM "Network ECU config data for interior";
BA_ "GenSigTimeout_RF_HUB" SG_ 995 NetCfg_CBC_IN 21000;
BA_ "GenSigTimeout_IC" SG_ 995 NetCfg_CBC_IN 21000;
BA_ "GenSigSNA" SG_ 995 NetCfg_CBC_IN "0h";
BA_ "GenSigSendType" SG_ 995 NetCfg_CBC_IN 5;
BA_ "GenSigCycleTime" SG_ 995 NetCfg_CBC_IN 2000;
BA_ "FlexKomSigStartValue" SG_ 995 NetCfg_CBC_IN "0300000000000000h";
BA_ "FlexKomSigStartPos" SG_ 995 NetCfg_CBC_IN 7;
BA_ "FlexKomSigName" SG_ 995 NetCfg_CBC_IN "NET_CFG_DATA_INT";
BA_ "FlexKomSigLaenge" SG_ 995 NetCfg_CBC_IN 64;
BA_ "FlexKomSID" SG_ 995 NetCfg_CBC_IN 38;
BA_ "FlexKomIsMotorola" SG_ 995 NetCfg_CBC_IN 1;
BA_ "FlexKomComment" SG_ 995 NetCfg_CBC_IN "Network ECU config data for interior";
BA_ "GenSigTimeout_RF_HUB" SG_ 995 NetCfg_CLOCK 21000;
BA_ "GenSigSNA" SG_ 995 NetCfg_CLOCK "0h";
BA_ "GenSigSendType" SG_ 995 NetCfg_CLOCK 5;
BA_ "GenSigCycleTime" SG_ 995 NetCfg_CLOCK 2000;
BA_ "FlexKomSigStartValue" SG_ 995 NetCfg_CLOCK "0300000000000000h";
BA_ "FlexKomSigStartPos" SG_ 995 NetCfg_CLOCK 7;
BA_ "FlexKomSigName" SG_ 995 NetCfg_CLOCK "NET_CFG_DATA_INT";
BA_ "FlexKomSigLaenge" SG_ 995 NetCfg_CLOCK 64;
BA_ "FlexKomSID" SG_ 995 NetCfg_CLOCK 38;
BA_ "FlexKomIsMotorola" SG_ 995 NetCfg_CLOCK 1;
BA_ "FlexKomComment" SG_ 995 NetCfg_CLOCK "Network ECU config data for interior";
BA_ "GenSigTimeout_RF_HUB" SG_ 995 NetCfg_CRSM 21000;
BA_ "GenSigSNA" SG_ 995 NetCfg_CRSM "0h";
BA_ "GenSigSendType" SG_ 995 NetCfg_CRSM 5;
BA_ "GenSigCycleTime" SG_ 995 NetCfg_CRSM 2000;
BA_ "FlexKomSigStartValue" SG_ 995 NetCfg_CRSM "0300000000000000h";
BA_ "FlexKomSigStartPos" SG_ 995 NetCfg_CRSM 7;
BA_ "FlexKomSigName" SG_ 995 NetCfg_CRSM "NET_CFG_DATA_INT";
BA_ "FlexKomSigLaenge" SG_ 995 NetCfg_CRSM 64;
BA_ "FlexKomSID" SG_ 995 NetCfg_CRSM 38;
BA_ "FlexKomIsMotorola" SG_ 995 NetCfg_CRSM 1;
BA_ "FlexKomComment" SG_ 995 NetCfg_CRSM "Network ECU config data for interior";
BA_ "GenSigTimeout_RF_HUB" SG_ 995 NetCfg_CSWM 21000;
BA_ "GenSigTimeout_IC" SG_ 995 NetCfg_CSWM 21000;
BA_ "GenSigSNA" SG_ 995 NetCfg_CSWM "0h";
BA_ "GenSigSendType" SG_ 995 NetCfg_CSWM 5;
BA_ "GenSigCycleTime" SG_ 995 NetCfg_CSWM 2000;
BA_ "FlexKomSigStartValue" SG_ 995 NetCfg_CSWM "0300000000000000h";
BA_ "FlexKomSigStartPos" SG_ 995 NetCfg_CSWM 7;
BA_ "FlexKomSigName" SG_ 995 NetCfg_CSWM "NET_CFG_DATA_INT";
BA_ "FlexKomSigLaenge" SG_ 995 NetCfg_CSWM 64;
BA_ "FlexKomSID" SG_ 995 NetCfg_CSWM 38;
BA_ "FlexKomIsMotorola" SG_ 995 NetCfg_CSWM 1;
BA_ "FlexKomComment" SG_ 995 NetCfg_CSWM "Network ECU config data for interior";
BA_ "GenSigTimeout_RF_HUB" SG_ 995 NetCfg_CVPM 21000;
BA_ "GenSigSNA" SG_ 995 NetCfg_CVPM "0h";
BA_ "GenSigSendType" SG_ 995 NetCfg_CVPM 5;
BA_ "GenSigCycleTime" SG_ 995 NetCfg_CVPM 2000;
BA_ "FlexKomSigStartValue" SG_ 995 NetCfg_CVPM "0300000000000000h";
BA_ "FlexKomSigStartPos" SG_ 995 NetCfg_CVPM 7;
BA_ "FlexKomSigName" SG_ 995 NetCfg_CVPM "NET_CFG_DATA_INT";
BA_ "FlexKomSigLaenge" SG_ 995 NetCfg_CVPM 64;
BA_ "FlexKomSID" SG_ 995 NetCfg_CVPM 38;
BA_ "FlexKomIsMotorola" SG_ 995 NetCfg_CVPM 1;
BA_ "FlexKomComment" SG_ 995 NetCfg_CVPM "Network ECU config data for interior";
BA_ "GenSigTimeout_RF_HUB" SG_ 995 NetCfg_DCM_DR 21000;
BA_ "GenSigTimeout_IC" SG_ 995 NetCfg_DCM_DR 21000;
BA_ "GenSigSNA" SG_ 995 NetCfg_DCM_DR "0h";
BA_ "GenSigSendType" SG_ 995 NetCfg_DCM_DR 5;
BA_ "GenSigCycleTime" SG_ 995 NetCfg_DCM_DR 2000;
BA_ "FlexKomSigStartValue" SG_ 995 NetCfg_DCM_DR "0300000000000000h";
BA_ "FlexKomSigStartPos" SG_ 995 NetCfg_DCM_DR 7;
BA_ "FlexKomSigName" SG_ 995 NetCfg_DCM_DR "NET_CFG_DATA_INT";
BA_ "FlexKomSigLaenge" SG_ 995 NetCfg_DCM_DR 64;
BA_ "FlexKomSID" SG_ 995 NetCfg_DCM_DR 38;
BA_ "FlexKomIsMotorola" SG_ 995 NetCfg_DCM_DR 1;
BA_ "FlexKomComment" SG_ 995 NetCfg_DCM_DR "Network ECU config data for interior";
BA_ "GenSigTimeout_RF_HUB" SG_ 995 NetCfg_DCM_PASS 21000;
BA_ "GenSigTimeout_IC" SG_ 995 NetCfg_DCM_PASS 21000;
BA_ "GenSigSNA" SG_ 995 NetCfg_DCM_PASS "0h";
BA_ "GenSigSendType" SG_ 995 NetCfg_DCM_PASS 5;
BA_ "GenSigCycleTime" SG_ 995 NetCfg_DCM_PASS 2000;
BA_ "FlexKomSigStartValue" SG_ 995 NetCfg_DCM_PASS "0300000000000000h";
BA_ "FlexKomSigStartPos" SG_ 995 NetCfg_DCM_PASS 7;
BA_ "FlexKomSigName" SG_ 995 NetCfg_DCM_PASS "NET_CFG_DATA_INT";
BA_ "FlexKomSigLaenge" SG_ 995 NetCfg_DCM_PASS 64;
BA_ "FlexKomSID" SG_ 995 NetCfg_DCM_PASS 38;
BA_ "FlexKomIsMotorola" SG_ 995 NetCfg_DCM_PASS 1;
BA_ "FlexKomComment" SG_ 995 NetCfg_DCM_PASS "Network ECU config data for interior";
BA_ "GenSigTimeout_RF_HUB" SG_ 995 NetCfg_DCM_RL 21000;
BA_ "GenSigTimeout_IC" SG_ 995 NetCfg_DCM_RL 21000;
BA_ "GenSigSNA" SG_ 995 NetCfg_DCM_RL "0h";
BA_ "GenSigSendType" SG_ 995 NetCfg_DCM_RL 5;
BA_ "GenSigCycleTime" SG_ 995 NetCfg_DCM_RL 2000;
BA_ "FlexKomSigStartValue" SG_ 995 NetCfg_DCM_RL "0300000000000000h";
BA_ "FlexKomSigStartPos" SG_ 995 NetCfg_DCM_RL 7;
BA_ "FlexKomSigName" SG_ 995 NetCfg_DCM_RL "NET_CFG_DATA_INT";
BA_ "FlexKomSigLaenge" SG_ 995 NetCfg_DCM_RL 64;
BA_ "FlexKomSID" SG_ 995 NetCfg_DCM_RL 38;
BA_ "FlexKomIsMotorola" SG_ 995 NetCfg_DCM_RL 1;
BA_ "FlexKomComment" SG_ 995 NetCfg_DCM_RL "Network ECU config data for interior";
BA_ "GenSigTimeout_RF_HUB" SG_ 995 NetCfg_DCM_RR 21000;
BA_ "GenSigTimeout_IC" SG_ 995 NetCfg_DCM_RR 21000;
BA_ "GenSigSNA" SG_ 995 NetCfg_DCM_RR "0h";
BA_ "GenSigSendType" SG_ 995 NetCfg_DCM_RR 5;
BA_ "GenSigCycleTime" SG_ 995 NetCfg_DCM_RR 2000;
BA_ "FlexKomSigStartValue" SG_ 995 NetCfg_DCM_RR "0300000000000000h";
BA_ "FlexKomSigStartPos" SG_ 995 NetCfg_DCM_RR 7;
BA_ "FlexKomSigName" SG_ 995 NetCfg_DCM_RR "NET_CFG_DATA_INT";
BA_ "FlexKomSigLaenge" SG_ 995 NetCfg_DCM_RR 64;
BA_ "FlexKomSID" SG_ 995 NetCfg_DCM_RR 38;
BA_ "FlexKomIsMotorola" SG_ 995 NetCfg_DCM_RR 1;
BA_ "FlexKomComment" SG_ 995 NetCfg_DCM_RR "Network ECU config data for interior";
BA_ "GenSigTimeout_RF_HUB" SG_ 995 NetCfg_DCSD 21000;
BA_ "GenSigSNA" SG_ 995 NetCfg_DCSD "0h";
BA_ "GenSigSendType" SG_ 995 NetCfg_DCSD 5;
BA_ "GenSigCycleTime" SG_ 995 NetCfg_DCSD 2000;
BA_ "FlexKomSigStartValue" SG_ 995 NetCfg_DCSD "0300000000000000h";
BA_ "FlexKomSigStartPos" SG_ 995 NetCfg_DCSD 7;
BA_ "FlexKomSigName" SG_ 995 NetCfg_DCSD "NET_CFG_DATA_INT";
BA_ "FlexKomSigLaenge" SG_ 995 NetCfg_DCSD 64;
BA_ "FlexKomSID" SG_ 995 NetCfg_DCSD 38;
BA_ "FlexKomIsMotorola" SG_ 995 NetCfg_DCSD 1;
BA_ "FlexKomComment" SG_ 995 NetCfg_DCSD "Network ECU config data for interior";
BA_ "GenSigTimeout_RF_HUB" SG_ 995 NetCfg_DTV 21000;
BA_ "GenSigSNA" SG_ 995 NetCfg_DTV "0h";
BA_ "GenSigSendType" SG_ 995 NetCfg_DTV 5;
BA_ "GenSigCycleTime" SG_ 995 NetCfg_DTV 2000;
BA_ "FlexKomSigStartValue" SG_ 995 NetCfg_DTV "0300000000000000h";
BA_ "FlexKomSigStartPos" SG_ 995 NetCfg_DTV 7;
BA_ "FlexKomSigName" SG_ 995 NetCfg_DTV "NET_CFG_DATA_INT";
BA_ "FlexKomSigLaenge" SG_ 995 NetCfg_DTV 64;
BA_ "FlexKomSID" SG_ 995 NetCfg_DTV 38;
BA_ "FlexKomIsMotorola" SG_ 995 NetCfg_DTV 1;
BA_ "FlexKomComment" SG_ 995 NetCfg_DTV "Network ECU config data for interior";
BA_ "GenSigTimeout_RF_HUB" SG_ 995 NetCfg_DVD_CDM 21000;
BA_ "GenSigSNA" SG_ 995 NetCfg_DVD_CDM "0h";
BA_ "GenSigSendType" SG_ 995 NetCfg_DVD_CDM 5;
BA_ "GenSigCycleTime" SG_ 995 NetCfg_DVD_CDM 2000;
BA_ "FlexKomSigStartValue" SG_ 995 NetCfg_DVD_CDM "0300000000000000h";
BA_ "FlexKomSigStartPos" SG_ 995 NetCfg_DVD_CDM 7;
BA_ "FlexKomSigName" SG_ 995 NetCfg_DVD_CDM "NET_CFG_DATA_INT";
BA_ "FlexKomSigLaenge" SG_ 995 NetCfg_DVD_CDM 64;
BA_ "FlexKomSID" SG_ 995 NetCfg_DVD_CDM 38;
BA_ "FlexKomIsMotorola" SG_ 995 NetCfg_DVD_CDM 1;
BA_ "FlexKomComment" SG_ 995 NetCfg_DVD_CDM "Network ECU config data for interior";
BA_ "GenSigTimeout_RF_HUB" SG_ 995 NetCfg_FSM 21000;
BA_ "GenSigTimeout_IC" SG_ 995 NetCfg_FSM 21000;
BA_ "GenSigSNA" SG_ 995 NetCfg_FSM "0h";
BA_ "GenSigSendType" SG_ 995 NetCfg_FSM 5;
BA_ "GenSigCycleTime" SG_ 995 NetCfg_FSM 2000;
BA_ "FlexKomSigStartValue" SG_ 995 NetCfg_FSM "0300000000000000h";
BA_ "FlexKomSigStartPos" SG_ 995 NetCfg_FSM 7;
BA_ "FlexKomSigName" SG_ 995 NetCfg_FSM "NET_CFG_DATA_INT";
BA_ "FlexKomSigLaenge" SG_ 995 NetCfg_FSM 64;
BA_ "FlexKomSID" SG_ 995 NetCfg_FSM 38;
BA_ "FlexKomIsMotorola" SG_ 995 NetCfg_FSM 1;
BA_ "FlexKomComment" SG_ 995 NetCfg_FSM "Network ECU config data for interior";
BA_ "GenSigTimeout_RF_HUB" SG_ 995 NetCfg_HFM_CTM 21000;
BA_ "GenSigSNA" SG_ 995 NetCfg_HFM_CTM "0h";
BA_ "GenSigSendType" SG_ 995 NetCfg_HFM_CTM 5;
BA_ "GenSigCycleTime" SG_ 995 NetCfg_HFM_CTM 2000;
BA_ "FlexKomSigStartValue" SG_ 995 NetCfg_HFM_CTM "0300000000000000h";
BA_ "FlexKomSigStartPos" SG_ 995 NetCfg_HFM_CTM 7;
BA_ "FlexKomSigName" SG_ 995 NetCfg_HFM_CTM "NET_CFG_DATA_INT";
BA_ "FlexKomSigLaenge" SG_ 995 NetCfg_HFM_CTM 64;
BA_ "FlexKomSID" SG_ 995 NetCfg_HFM_CTM 38;
BA_ "FlexKomIsMotorola" SG_ 995 NetCfg_HFM_CTM 1;
BA_ "FlexKomComment" SG_ 995 NetCfg_HFM_CTM "Network ECU config data for interior";
BA_ "GenSigTimeout_RF_HUB" SG_ 995 NetCfg_HVAC 21000;
BA_ "GenSigTimeout_IC" SG_ 995 NetCfg_HVAC 21000;
BA_ "GenSigSNA" SG_ 995 NetCfg_HVAC "0h";
BA_ "GenSigSendType" SG_ 995 NetCfg_HVAC 5;
BA_ "GenSigCycleTime" SG_ 995 NetCfg_HVAC 2000;
BA_ "FlexKomSigStartValue" SG_ 995 NetCfg_HVAC "0300000000000000h";
BA_ "FlexKomSigStartPos" SG_ 995 NetCfg_HVAC 7;
BA_ "FlexKomSigName" SG_ 995 NetCfg_HVAC "NET_CFG_DATA_INT";
BA_ "FlexKomSigLaenge" SG_ 995 NetCfg_HVAC 64;
BA_ "FlexKomSID" SG_ 995 NetCfg_HVAC 38;
BA_ "FlexKomIsMotorola" SG_ 995 NetCfg_HVAC 1;
BA_ "FlexKomComment" SG_ 995 NetCfg_HVAC "Network ECU config data for interior";
BA_ "GenSigTimeout_RF_HUB" SG_ 995 NetCfg_HVAC_R 21000;
BA_ "GenSigSNA" SG_ 995 NetCfg_HVAC_R "0h";
BA_ "GenSigSendType" SG_ 995 NetCfg_HVAC_R 5;
BA_ "GenSigCycleTime" SG_ 995 NetCfg_HVAC_R 2000;
BA_ "FlexKomSigStartValue" SG_ 995 NetCfg_HVAC_R "0300000000000000h";
BA_ "FlexKomSigStartPos" SG_ 995 NetCfg_HVAC_R 7;
BA_ "FlexKomSigName" SG_ 995 NetCfg_HVAC_R "NET_CFG_DATA_INT";
BA_ "FlexKomSigLaenge" SG_ 995 NetCfg_HVAC_R 64;
BA_ "FlexKomSID" SG_ 995 NetCfg_HVAC_R 38;
BA_ "FlexKomIsMotorola" SG_ 995 NetCfg_HVAC_R 1;
BA_ "FlexKomComment" SG_ 995 NetCfg_HVAC_R "Network ECU config data for interior";
BA_ "GenSigTimeout_RF_HUB" SG_ 995 NetCfg_ICS_I 21000;
BA_ "GenSigSNA" SG_ 995 NetCfg_ICS_I "0h";
BA_ "GenSigSendType" SG_ 995 NetCfg_ICS_I 5;
BA_ "GenSigCycleTime" SG_ 995 NetCfg_ICS_I 2000;
BA_ "FlexKomSigStartValue" SG_ 995 NetCfg_ICS_I "0300000000000000h";
BA_ "FlexKomSigStartPos" SG_ 995 NetCfg_ICS_I 7;
BA_ "FlexKomSigName" SG_ 995 NetCfg_ICS_I "NET_CFG_DATA_INT";
BA_ "FlexKomSigLaenge" SG_ 995 NetCfg_ICS_I 64;
BA_ "FlexKomSID" SG_ 995 NetCfg_ICS_I 38;
BA_ "FlexKomIsMotorola" SG_ 995 NetCfg_ICS_I 1;
BA_ "FlexKomComment" SG_ 995 NetCfg_ICS_I "Network ECU config data for interior";
BA_ "GenSigTimeout_RF_HUB" SG_ 995 NetCfg_ICS_R 21000;
BA_ "GenSigSNA" SG_ 995 NetCfg_ICS_R "0h";
BA_ "GenSigSendType" SG_ 995 NetCfg_ICS_R 5;
BA_ "GenSigCycleTime" SG_ 995 NetCfg_ICS_R 2000;
BA_ "FlexKomSigStartValue" SG_ 995 NetCfg_ICS_R "0300000000000000h";
BA_ "FlexKomSigStartPos" SG_ 995 NetCfg_ICS_R 7;
BA_ "FlexKomSigName" SG_ 995 NetCfg_ICS_R "NET_CFG_DATA_INT";
BA_ "FlexKomSigLaenge" SG_ 995 NetCfg_ICS_R 64;
BA_ "FlexKomSID" SG_ 995 NetCfg_ICS_R 38;
BA_ "FlexKomIsMotorola" SG_ 995 NetCfg_ICS_R 1;
BA_ "FlexKomComment" SG_ 995 NetCfg_ICS_R "Network ECU config data for interior";
BA_ "GenSigTimeout_RF_HUB" SG_ 995 NetCfg_ITM 21000;
BA_ "GenSigTimeout_IC" SG_ 995 NetCfg_ITM 21000;
BA_ "GenSigSNA" SG_ 995 NetCfg_ITM "0h";
BA_ "GenSigSendType" SG_ 995 NetCfg_ITM 5;
BA_ "GenSigCycleTime" SG_ 995 NetCfg_ITM 2000;
BA_ "FlexKomSigStartValue" SG_ 995 NetCfg_ITM "0300000000000000h";
BA_ "FlexKomSigStartPos" SG_ 995 NetCfg_ITM 7;
BA_ "FlexKomSigName" SG_ 995 NetCfg_ITM "NET_CFG_DATA_INT";
BA_ "FlexKomSigLaenge" SG_ 995 NetCfg_ITM 64;
BA_ "FlexKomSID" SG_ 995 NetCfg_ITM 38;
BA_ "FlexKomIsMotorola" SG_ 995 NetCfg_ITM 1;
BA_ "FlexKomComment" SG_ 995 NetCfg_ITM "Network ECU config data for interior";
BA_ "GenSigTimeout_RF_HUB" SG_ 995 NetCfg_MSM 21000;
BA_ "GenSigTimeout_IC" SG_ 995 NetCfg_MSM 21000;
BA_ "GenSigSNA" SG_ 995 NetCfg_MSM "0h";
BA_ "GenSigSendType" SG_ 995 NetCfg_MSM 5;
BA_ "GenSigCycleTime" SG_ 995 NetCfg_MSM 2000;
BA_ "FlexKomSigStartValue" SG_ 995 NetCfg_MSM "0300000000000000h";
BA_ "FlexKomSigStartPos" SG_ 995 NetCfg_MSM 7;
BA_ "FlexKomSigName" SG_ 995 NetCfg_MSM "NET_CFG_DATA_INT";
BA_ "FlexKomSigLaenge" SG_ 995 NetCfg_MSM 64;
BA_ "FlexKomSID" SG_ 995 NetCfg_MSM 38;
BA_ "FlexKomIsMotorola" SG_ 995 NetCfg_MSM 1;
BA_ "FlexKomComment" SG_ 995 NetCfg_MSM "Network ECU config data for interior";
BA_ "GenSigTimeout_RF_HUB" SG_ 995 NetCfg_MSM_PASS 21000;
BA_ "GenSigSNA" SG_ 995 NetCfg_MSM_PASS "0h";
BA_ "GenSigSendType" SG_ 995 NetCfg_MSM_PASS 5;
BA_ "GenSigCycleTime" SG_ 995 NetCfg_MSM_PASS 2000;
BA_ "FlexKomSigStartValue" SG_ 995 NetCfg_MSM_PASS "0300000000000000h";
BA_ "FlexKomSigStartPos" SG_ 995 NetCfg_MSM_PASS 7;
BA_ "FlexKomSigName" SG_ 995 NetCfg_MSM_PASS "NET_CFG_DATA_INT";
BA_ "FlexKomSigLaenge" SG_ 995 NetCfg_MSM_PASS 64;
BA_ "FlexKomSID" SG_ 995 NetCfg_MSM_PASS 38;
BA_ "FlexKomIsMotorola" SG_ 995 NetCfg_MSM_PASS 1;
BA_ "FlexKomComment" SG_ 995 NetCfg_MSM_PASS "Network ECU config data for interior";
BA_ "GenSigTimeout_RF_HUB" SG_ 995 NetCfg_PLG 21000;
BA_ "GenSigTimeout_IC" SG_ 995 NetCfg_PLG 21000;
BA_ "GenSigSNA" SG_ 995 NetCfg_PLG "0h";
BA_ "GenSigSendType" SG_ 995 NetCfg_PLG 5;
BA_ "GenSigCycleTime" SG_ 995 NetCfg_PLG 2000;
BA_ "FlexKomSigStartValue" SG_ 995 NetCfg_PLG "0300000000000000h";
BA_ "FlexKomSigStartPos" SG_ 995 NetCfg_PLG 7;
BA_ "FlexKomSigName" SG_ 995 NetCfg_PLG "NET_CFG_DATA_INT";
BA_ "FlexKomSigLaenge" SG_ 995 NetCfg_PLG 64;
BA_ "FlexKomSID" SG_ 995 NetCfg_PLG 38;
BA_ "FlexKomIsMotorola" SG_ 995 NetCfg_PLG 1;
BA_ "FlexKomComment" SG_ 995 NetCfg_PLG "Network ECU config data for interior";
BA_ "GenSigTimeout_RF_HUB" SG_ 995 NetCfg_PSD_LT 21000;
BA_ "GenSigTimeout_IC" SG_ 995 NetCfg_PSD_LT 21000;
BA_ "GenSigSNA" SG_ 995 NetCfg_PSD_LT "0h";
BA_ "GenSigSendType" SG_ 995 NetCfg_PSD_LT 5;
BA_ "GenSigCycleTime" SG_ 995 NetCfg_PSD_LT 2000;
BA_ "FlexKomSigStartValue" SG_ 995 NetCfg_PSD_LT "0300000000000000h";
BA_ "FlexKomSigStartPos" SG_ 995 NetCfg_PSD_LT 7;
BA_ "FlexKomSigName" SG_ 995 NetCfg_PSD_LT "NET_CFG_DATA_INT";
BA_ "FlexKomSigLaenge" SG_ 995 NetCfg_PSD_LT 64;
BA_ "FlexKomSID" SG_ 995 NetCfg_PSD_LT 38;
BA_ "FlexKomIsMotorola" SG_ 995 NetCfg_PSD_LT 1;
BA_ "FlexKomComment" SG_ 995 NetCfg_PSD_LT "Network ECU config data for interior";
BA_ "GenSigTimeout_RF_HUB" SG_ 995 NetCfg_PSD_RT 21000;
BA_ "GenSigTimeout_IC" SG_ 995 NetCfg_PSD_RT 21000;
BA_ "GenSigSNA" SG_ 995 NetCfg_PSD_RT "0h";
BA_ "GenSigSendType" SG_ 995 NetCfg_PSD_RT 5;
BA_ "GenSigCycleTime" SG_ 995 NetCfg_PSD_RT 2000;
BA_ "FlexKomSigStartValue" SG_ 995 NetCfg_PSD_RT "0300000000000000h";
BA_ "FlexKomSigStartPos" SG_ 995 NetCfg_PSD_RT 7;
BA_ "FlexKomSigName" SG_ 995 NetCfg_PSD_RT "NET_CFG_DATA_INT";
BA_ "FlexKomSigLaenge" SG_ 995 NetCfg_PSD_RT 64;
BA_ "FlexKomSID" SG_ 995 NetCfg_PSD_RT 38;
BA_ "FlexKomIsMotorola" SG_ 995 NetCfg_PSD_RT 1;
BA_ "FlexKomComment" SG_ 995 NetCfg_PSD_RT "Network ECU config data for interior";
BA_ "GenSigSNA" SG_ 995 NetCfg_PSSM "0h";
BA_ "GenSigSendType" SG_ 995 NetCfg_PSSM 5;
BA_ "GenSigCycleTime" SG_ 995 NetCfg_PSSM 2000;
BA_ "FlexKomSigStartValue" SG_ 995 NetCfg_PSSM "0300000000000000h";
BA_ "FlexKomSigStartPos" SG_ 995 NetCfg_PSSM 7;
BA_ "FlexKomSigName" SG_ 995 NetCfg_PSSM "NET_CFG_DATA_INT";
BA_ "FlexKomSigLaenge" SG_ 995 NetCfg_PSSM 64;
BA_ "FlexKomSID" SG_ 995 NetCfg_PSSM 38;
BA_ "FlexKomIsMotorola" SG_ 995 NetCfg_PSSM 1;
BA_ "FlexKomComment" SG_ 995 NetCfg_PSSM "Network ECU config data for interior";
BA_ "GenSigTimeout_RF_HUB" SG_ 995 NetCfg_PTCM 21000;
BA_ "GenSigTimeout_IC" SG_ 995 NetCfg_PTCM 21000;
BA_ "GenSigSNA" SG_ 995 NetCfg_PTCM "0h";
BA_ "GenSigSendType" SG_ 995 NetCfg_PTCM 5;
BA_ "GenSigCycleTime" SG_ 995 NetCfg_PTCM 2000;
BA_ "FlexKomSigStartValue" SG_ 995 NetCfg_PTCM "0300000000000000h";
BA_ "FlexKomSigStartPos" SG_ 995 NetCfg_PTCM 7;
BA_ "FlexKomSigName" SG_ 995 NetCfg_PTCM "NET_CFG_DATA_INT";
BA_ "FlexKomSigLaenge" SG_ 995 NetCfg_PTCM 64;
BA_ "FlexKomSID" SG_ 995 NetCfg_PTCM 38;
BA_ "FlexKomIsMotorola" SG_ 995 NetCfg_PTCM 1;
BA_ "FlexKomComment" SG_ 995 NetCfg_PTCM "Network ECU config data for interior";
BA_ "GenSigTimeout_RF_HUB" SG_ 995 NetCfg_RBC 21000;
BA_ "GenSigTimeout_IC" SG_ 995 NetCfg_RBC 21000;
BA_ "GenSigSNA" SG_ 995 NetCfg_RBC "0h";
BA_ "GenSigSendType" SG_ 995 NetCfg_RBC 5;
BA_ "GenSigCycleTime" SG_ 995 NetCfg_RBC 2000;
BA_ "FlexKomSigStartValue" SG_ 995 NetCfg_RBC "0300000000000000h";
BA_ "FlexKomSigStartPos" SG_ 995 NetCfg_RBC 7;
BA_ "FlexKomSigName" SG_ 995 NetCfg_RBC "NET_CFG_DATA_INT";
BA_ "FlexKomSigLaenge" SG_ 995 NetCfg_RBC 64;
BA_ "FlexKomSID" SG_ 995 NetCfg_RBC 38;
BA_ "FlexKomIsMotorola" SG_ 995 NetCfg_RBC 1;
BA_ "FlexKomComment" SG_ 995 NetCfg_RBC "Network ECU config data for interior";
BA_ "GenSigTimeout_RF_HUB" SG_ 995 NetCfg_RBSS 21000;
BA_ "GenSigSNA" SG_ 995 NetCfg_RBSS "0h";
BA_ "GenSigSendType" SG_ 995 NetCfg_RBSS 5;
BA_ "GenSigCycleTime" SG_ 995 NetCfg_RBSS 2000;
BA_ "FlexKomSigStartValue" SG_ 995 NetCfg_RBSS "0300000000000000h";
BA_ "FlexKomSigStartPos" SG_ 995 NetCfg_RBSS 7;
BA_ "FlexKomSigName" SG_ 995 NetCfg_RBSS "NET_CFG_DATA_INT";
BA_ "FlexKomSigLaenge" SG_ 995 NetCfg_RBSS 64;
BA_ "FlexKomSID" SG_ 995 NetCfg_RBSS 38;
BA_ "FlexKomIsMotorola" SG_ 995 NetCfg_RBSS 1;
BA_ "FlexKomComment" SG_ 995 NetCfg_RBSS "Network ECU config data for interior";
BA_ "GenSigTimeout_RF_HUB" SG_ 995 NetCfg_TBM 21000;
BA_ "GenSigSNA" SG_ 995 NetCfg_TBM "0h";
BA_ "GenSigSendType" SG_ 995 NetCfg_TBM 5;
BA_ "GenSigCycleTime" SG_ 995 NetCfg_TBM 2000;
BA_ "FlexKomSigStartValue" SG_ 995 NetCfg_TBM "0300000000000000h";
BA_ "FlexKomSigStartPos" SG_ 995 NetCfg_TBM 7;
BA_ "FlexKomSigName" SG_ 995 NetCfg_TBM "NET_CFG_DATA_INT";
BA_ "FlexKomSigLaenge" SG_ 995 NetCfg_TBM 64;
BA_ "FlexKomSID" SG_ 995 NetCfg_TBM 38;
BA_ "FlexKomIsMotorola" SG_ 995 NetCfg_TBM 1;
BA_ "FlexKomComment" SG_ 995 NetCfg_TBM "Network ECU config data for interior";
BA_ "GenSigTimeout_RF_HUB" SG_ 995 NetCfg_TGW 21000;
BA_ "GenSigTimeout_IC" SG_ 995 NetCfg_TGW 21000;
BA_ "GenSigSNA" SG_ 995 NetCfg_TGW "0h";
BA_ "GenSigSendType" SG_ 995 NetCfg_TGW 5;
BA_ "GenSigCycleTime" SG_ 995 NetCfg_TGW 2000;
BA_ "FlexKomSigStartValue" SG_ 995 NetCfg_TGW "0300000000000000h";
BA_ "FlexKomSigStartPos" SG_ 995 NetCfg_TGW 7;
BA_ "FlexKomSigName" SG_ 995 NetCfg_TGW "NET_CFG_DATA_INT";
BA_ "FlexKomSigLaenge" SG_ 995 NetCfg_TGW 64;
BA_ "FlexKomSID" SG_ 995 NetCfg_TGW 38;
BA_ "FlexKomIsMotorola" SG_ 995 NetCfg_TGW 1;
BA_ "FlexKomComment" SG_ 995 NetCfg_TGW "Network ECU config data for interior";
BA_ "GenSigTimeout_RF_HUB" SG_ 995 NetCfg_TMM 21000;
BA_ "GenSigSNA" SG_ 995 NetCfg_TMM "0h";
BA_ "GenSigSendType" SG_ 995 NetCfg_TMM 5;
BA_ "GenSigCycleTime" SG_ 995 NetCfg_TMM 2000;
BA_ "FlexKomSigStartValue" SG_ 995 NetCfg_TMM "0300000000000000h";
BA_ "FlexKomSigStartPos" SG_ 995 NetCfg_TMM 7;
BA_ "FlexKomSigName" SG_ 995 NetCfg_TMM "NET_CFG_DATA_INT";
BA_ "FlexKomSigLaenge" SG_ 995 NetCfg_TMM 64;
BA_ "FlexKomSID" SG_ 995 NetCfg_TMM 38;
BA_ "FlexKomIsMotorola" SG_ 995 NetCfg_TMM 1;
BA_ "FlexKomComment" SG_ 995 NetCfg_TMM "Network ECU config data for interior";
BA_ "GenSigTimeout_RF_HUB" SG_ 995 NetCfg_TTM 21000;
BA_ "GenSigSNA" SG_ 995 NetCfg_TTM "0h";
BA_ "GenSigSendType" SG_ 995 NetCfg_TTM 5;
BA_ "GenSigCycleTime" SG_ 995 NetCfg_TTM 2000;
BA_ "FlexKomSigStartValue" SG_ 995 NetCfg_TTM "0300000000000000h";
BA_ "FlexKomSigStartPos" SG_ 995 NetCfg_TTM 7;
BA_ "FlexKomSigName" SG_ 995 NetCfg_TTM "NET_CFG_DATA_INT";
BA_ "FlexKomSigLaenge" SG_ 995 NetCfg_TTM 64;
BA_ "FlexKomSID" SG_ 995 NetCfg_TTM 38;
BA_ "FlexKomIsMotorola" SG_ 995 NetCfg_TTM 1;
BA_ "FlexKomComment" SG_ 995 NetCfg_TTM "Network ECU config data for interior";
BA_ "GenSigTimeout_RF_HUB" SG_ 995 NetCfg_UPFM 21000;
BA_ "GenSigSNA" SG_ 995 NetCfg_UPFM "0h";
BA_ "GenSigSendType" SG_ 995 NetCfg_UPFM 5;
BA_ "GenSigCycleTime" SG_ 995 NetCfg_UPFM 2000;
BA_ "FlexKomSigStartValue" SG_ 995 NetCfg_UPFM "0300000000000000h";
BA_ "FlexKomSigStartPos" SG_ 995 NetCfg_UPFM 7;
BA_ "FlexKomSigName" SG_ 995 NetCfg_UPFM "NET_CFG_DATA_INT";
BA_ "FlexKomSigLaenge" SG_ 995 NetCfg_UPFM 64;
BA_ "FlexKomSID" SG_ 995 NetCfg_UPFM 38;
BA_ "FlexKomIsMotorola" SG_ 995 NetCfg_UPFM 1;
BA_ "FlexKomComment" SG_ 995 NetCfg_UPFM "Network ECU config data for interior";
BA_ "GenSigTimeout_RF_HUB" SG_ 995 NetCfg_VES2_I 21000;
BA_ "GenSigSNA" SG_ 995 NetCfg_VES2_I "0h";
BA_ "GenSigSendType" SG_ 995 NetCfg_VES2_I 5;
BA_ "GenSigCycleTime" SG_ 995 NetCfg_VES2_I 2000;
BA_ "FlexKomSigStartValue" SG_ 995 NetCfg_VES2_I "0300000000000000h";
BA_ "FlexKomSigStartPos" SG_ 995 NetCfg_VES2_I 7;
BA_ "FlexKomSigName" SG_ 995 NetCfg_VES2_I "NET_CFG_DATA_INT";
BA_ "FlexKomSigLaenge" SG_ 995 NetCfg_VES2_I 64;
BA_ "FlexKomSID" SG_ 995 NetCfg_VES2_I 38;
BA_ "FlexKomIsMotorola" SG_ 995 NetCfg_VES2_I 1;
BA_ "FlexKomComment" SG_ 995 NetCfg_VES2_I "Network ECU config data for interior";
BA_ "GenSigTimeout_RF_HUB" SG_ 995 NetCfg_VES3_I 21000;
BA_ "GenSigSNA" SG_ 995 NetCfg_VES3_I "0h";
BA_ "GenSigSendType" SG_ 995 NetCfg_VES3_I 5;
BA_ "GenSigCycleTime" SG_ 995 NetCfg_VES3_I 2000;
BA_ "FlexKomSigStartValue" SG_ 995 NetCfg_VES3_I "0300000000000000h";
BA_ "FlexKomSigStartPos" SG_ 995 NetCfg_VES3_I 7;
BA_ "FlexKomSigName" SG_ 995 NetCfg_VES3_I "NET_CFG_DATA_INT";
BA_ "FlexKomSigLaenge" SG_ 995 NetCfg_VES3_I 64;
BA_ "FlexKomSID" SG_ 995 NetCfg_VES3_I 38;
BA_ "FlexKomIsMotorola" SG_ 995 NetCfg_VES3_I 1;
BA_ "FlexKomComment" SG_ 995 NetCfg_VES3_I "Network ECU config data for interior";
BA_ "GenSigTimeout_RF_HUB" SG_ 995 NetCfg_VRM 21000;
BA_ "GenSigSNA" SG_ 995 NetCfg_VRM "0h";
BA_ "GenSigSendType" SG_ 995 NetCfg_VRM 5;
BA_ "GenSigCycleTime" SG_ 995 NetCfg_VRM 2000;
BA_ "FlexKomSigStartValue" SG_ 995 NetCfg_VRM "0300000000000000h";
BA_ "FlexKomSigStartPos" SG_ 995 NetCfg_VRM 7;
BA_ "FlexKomSigName" SG_ 995 NetCfg_VRM "NET_CFG_DATA_INT";
BA_ "FlexKomSigLaenge" SG_ 995 NetCfg_VRM 64;
BA_ "FlexKomSID" SG_ 995 NetCfg_VRM 38;
BA_ "FlexKomIsMotorola" SG_ 995 NetCfg_VRM 1;
BA_ "FlexKomComment" SG_ 995 NetCfg_VRM "Network ECU config data for interior";
BA_ "GenSigTimeout_RF_HUB" SG_ 995 NetCfg_VSIM 21000;
BA_ "GenSigTimeout_IC" SG_ 995 NetCfg_VSIM 21000;
BA_ "GenSigSNA" SG_ 995 NetCfg_VSIM "0h";
BA_ "GenSigSendType" SG_ 995 NetCfg_VSIM 5;
BA_ "GenSigCycleTime" SG_ 995 NetCfg_VSIM 2000;
BA_ "FlexKomSigStartValue" SG_ 995 NetCfg_VSIM "0300000000000000h";
BA_ "FlexKomSigStartPos" SG_ 995 NetCfg_VSIM 7;
BA_ "FlexKomSigName" SG_ 995 NetCfg_VSIM "NET_CFG_DATA_INT";
BA_ "FlexKomSigLaenge" SG_ 995 NetCfg_VSIM 64;
BA_ "FlexKomSID" SG_ 995 NetCfg_VSIM 38;
BA_ "FlexKomIsMotorola" SG_ 995 NetCfg_VSIM 1;
BA_ "FlexKomComment" SG_ 995 NetCfg_VSIM "Network ECU config data for interior";
BA_ "GenSigTimeout_RF_HUB" SG_ 995 NetCfg_VTM 21000;
BA_ "GenSigSNA" SG_ 995 NetCfg_VTM "0h";
BA_ "GenSigSendType" SG_ 995 NetCfg_VTM 5;
BA_ "GenSigCycleTime" SG_ 995 NetCfg_VTM 2000;
BA_ "FlexKomSigStartValue" SG_ 995 NetCfg_VTM "0300000000000000h";
BA_ "FlexKomSigStartPos" SG_ 995 NetCfg_VTM 7;
BA_ "FlexKomSigName" SG_ 995 NetCfg_VTM "NET_CFG_DATA_INT";
BA_ "FlexKomSigLaenge" SG_ 995 NetCfg_VTM 64;
BA_ "FlexKomSID" SG_ 995 NetCfg_VTM 38;
BA_ "FlexKomIsMotorola" SG_ 995 NetCfg_VTM 1;
BA_ "FlexKomComment" SG_ 995 NetCfg_VTM "Network ECU config data for interior";
BA_ "GenSigTimeout_TPM" SG_ 996 NET_CFG_STAT_PT 21000;
BA_ "GenSigTimeout_ORC" SG_ 996 NET_CFG_STAT_PT 7000;
BA_ "GenSigTimeout_OCM" SG_ 996 NET_CFG_STAT_PT 21000;
BA_ "GenSigTimeout_IC" SG_ 996 NET_CFG_STAT_PT 21000;
BA_ "GenSigTimeout_ESM" SG_ 996 NET_CFG_STAT_PT 21000;
BA_ "GenSigTimeout_EHPS" SG_ 996 NET_CFG_STAT_PT 21000;
BA_ "GenSigTimeout_DTCM" SG_ 996 NET_CFG_STAT_PT 21000;
BA_ "GenSigTimeout_DPDM" SG_ 996 NET_CFG_STAT_PT 21000;
BA_ "GenSigStartValue" SG_ 996 NET_CFG_STAT_PT 3;
BA_ "GenSigSNA" SG_ 996 NET_CFG_STAT_PT "3h";
BA_ "GenSigSendType" SG_ 996 NET_CFG_STAT_PT 5;
BA_ "GenSigCycleTime" SG_ 996 NET_CFG_STAT_PT 2000;
BA_ "FlexKomSigStartValue" SG_ 996 NET_CFG_STAT_PT "0300000000000000h";
BA_ "FlexKomSigStartPos" SG_ 996 NET_CFG_STAT_PT 7;
BA_ "FlexKomSigName" SG_ 996 NET_CFG_STAT_PT "NET_CFG_DATA_PT";
BA_ "FlexKomSigLaenge" SG_ 996 NET_CFG_STAT_PT 64;
BA_ "FlexKomSID" SG_ 996 NET_CFG_STAT_PT 39;
BA_ "FlexKomIsMotorola" SG_ 996 NET_CFG_STAT_PT 1;
BA_ "FlexKomComment" SG_ 996 NET_CFG_STAT_PT "Network ECU config data for Powertrain";
BA_ "GenSigTimeout_IC" SG_ 996 NetCfg_ACC 21000;
BA_ "GenSigSNA" SG_ 996 NetCfg_ACC "0h";
BA_ "GenSigSendType" SG_ 996 NetCfg_ACC 5;
BA_ "GenSigCycleTime" SG_ 996 NetCfg_ACC 2000;
BA_ "FlexKomSigStartValue" SG_ 996 NetCfg_ACC "0300000000000000h";
BA_ "FlexKomSigStartPos" SG_ 996 NetCfg_ACC 7;
BA_ "FlexKomSigName" SG_ 996 NetCfg_ACC "NET_CFG_DATA_PT";
BA_ "FlexKomSigLaenge" SG_ 996 NetCfg_ACC 64;
BA_ "FlexKomSID" SG_ 996 NetCfg_ACC 39;
BA_ "FlexKomIsMotorola" SG_ 996 NetCfg_ACC 1;
BA_ "FlexKomComment" SG_ 996 NetCfg_ACC "Network ECU config data for Powertrain";
BA_ "GenSigTimeout_ORC" SG_ 996 NetCfg_ADCM 7000;
BA_ "GenSigTimeout_IC" SG_ 996 NetCfg_ADCM 21000;
BA_ "GenSigSNA" SG_ 996 NetCfg_ADCM "0h";
BA_ "GenSigSendType" SG_ 996 NetCfg_ADCM 5;
BA_ "GenSigCycleTime" SG_ 996 NetCfg_ADCM 2000;
BA_ "FlexKomSigStartValue" SG_ 996 NetCfg_ADCM "0300000000000000h";
BA_ "FlexKomSigStartPos" SG_ 996 NetCfg_ADCM 7;
BA_ "FlexKomSigName" SG_ 996 NetCfg_ADCM "NET_CFG_DATA_PT";
BA_ "FlexKomSigLaenge" SG_ 996 NetCfg_ADCM 64;
BA_ "FlexKomSID" SG_ 996 NetCfg_ADCM 39;
BA_ "FlexKomIsMotorola" SG_ 996 NetCfg_ADCM 1;
BA_ "FlexKomComment" SG_ 996 NetCfg_ADCM "Network ECU config data for Powertrain";
BA_ "GenSigTimeout_IC" SG_ 996 NetCfg_AFLS 21000;
BA_ "GenSigSNA" SG_ 996 NetCfg_AFLS "0h";
BA_ "GenSigSendType" SG_ 996 NetCfg_AFLS 5;
BA_ "GenSigCycleTime" SG_ 996 NetCfg_AFLS 2000;
BA_ "FlexKomSigStartValue" SG_ 996 NetCfg_AFLS "0300000000000000h";
BA_ "FlexKomSigStartPos" SG_ 996 NetCfg_AFLS 7;
BA_ "FlexKomSigName" SG_ 996 NetCfg_AFLS "NET_CFG_DATA_PT";
BA_ "FlexKomSigLaenge" SG_ 996 NetCfg_AFLS 64;
BA_ "FlexKomSID" SG_ 996 NetCfg_AFLS 39;
BA_ "FlexKomIsMotorola" SG_ 996 NetCfg_AFLS 1;
BA_ "FlexKomComment" SG_ 996 NetCfg_AFLS "Network ECU config data for Powertrain";
BA_ "GenSigTimeout_IC" SG_ 996 NetCfg_AHLM 21000;
BA_ "GenSigSNA" SG_ 996 NetCfg_AHLM "0h";
BA_ "GenSigSendType" SG_ 996 NetCfg_AHLM 5;
BA_ "GenSigCycleTime" SG_ 996 NetCfg_AHLM 2000;
BA_ "FlexKomSigStartValue" SG_ 996 NetCfg_AHLM "0300000000000000h";
BA_ "FlexKomSigStartPos" SG_ 996 NetCfg_AHLM 7;
BA_ "FlexKomSigName" SG_ 996 NetCfg_AHLM "NET_CFG_DATA_PT";
BA_ "FlexKomSigLaenge" SG_ 996 NetCfg_AHLM 64;
BA_ "FlexKomSID" SG_ 996 NetCfg_AHLM 39;
BA_ "FlexKomIsMotorola" SG_ 996 NetCfg_AHLM 1;
BA_ "FlexKomComment" SG_ 996 NetCfg_AHLM "Network ECU config data for Powertrain";
BA_ "GenSigSNA" SG_ 996 NetCfg_ANC "0h";
BA_ "GenSigSendType" SG_ 996 NetCfg_ANC 5;
BA_ "GenSigCycleTime" SG_ 996 NetCfg_ANC 2000;
BA_ "FlexKomSigStartValue" SG_ 996 NetCfg_ANC "0300000000000000h";
BA_ "FlexKomSigStartPos" SG_ 996 NetCfg_ANC 7;
BA_ "FlexKomSigName" SG_ 996 NetCfg_ANC "NET_CFG_DATA_PT";
BA_ "FlexKomSigLaenge" SG_ 996 NetCfg_ANC 64;
BA_ "FlexKomSID" SG_ 996 NetCfg_ANC 39;
BA_ "FlexKomIsMotorola" SG_ 996 NetCfg_ANC 1;
BA_ "FlexKomComment" SG_ 996 NetCfg_ANC "Network ECU config data for Powertrain";
BA_ "GenSigTimeout_IC" SG_ 996 NetCfg_ASBS 21000;
BA_ "GenSigSNA" SG_ 996 NetCfg_ASBS "0h";
BA_ "GenSigSendType" SG_ 996 NetCfg_ASBS 5;
BA_ "GenSigCycleTime" SG_ 996 NetCfg_ASBS 2000;
BA_ "FlexKomSigStartValue" SG_ 996 NetCfg_ASBS "0300000000000000h";
BA_ "FlexKomSigStartPos" SG_ 996 NetCfg_ASBS 7;
BA_ "FlexKomSigName" SG_ 996 NetCfg_ASBS "NET_CFG_DATA_PT";
BA_ "FlexKomSigLaenge" SG_ 996 NetCfg_ASBS 64;
BA_ "FlexKomSID" SG_ 996 NetCfg_ASBS 39;
BA_ "FlexKomIsMotorola" SG_ 996 NetCfg_ASBS 1;
BA_ "FlexKomComment" SG_ 996 NetCfg_ASBS "Network ECU config data for Powertrain";
BA_ "GenSigTimeout_IC" SG_ 996 NetCfg_ASCM 21000;
BA_ "GenSigSNA" SG_ 996 NetCfg_ASCM "0h";
BA_ "GenSigSendType" SG_ 996 NetCfg_ASCM 5;
BA_ "GenSigCycleTime" SG_ 996 NetCfg_ASCM 2000;
BA_ "FlexKomSigStartValue" SG_ 996 NetCfg_ASCM "0300000000000000h";
BA_ "FlexKomSigStartPos" SG_ 996 NetCfg_ASCM 7;
BA_ "FlexKomSigName" SG_ 996 NetCfg_ASCM "NET_CFG_DATA_PT";
BA_ "FlexKomSigLaenge" SG_ 996 NetCfg_ASCM 64;
BA_ "FlexKomSID" SG_ 996 NetCfg_ASCM 39;
BA_ "FlexKomIsMotorola" SG_ 996 NetCfg_ASCM 1;
BA_ "FlexKomComment" SG_ 996 NetCfg_ASCM "Network ECU config data for Powertrain";
BA_ "GenSigSNA" SG_ 996 NetCfg_BSMO "0h";
BA_ "GenSigSendType" SG_ 996 NetCfg_BSMO 5;
BA_ "GenSigCycleTime" SG_ 996 NetCfg_BSMO 2000;
BA_ "FlexKomSigStartValue" SG_ 996 NetCfg_BSMO "0300000000000000h";
BA_ "FlexKomSigStartPos" SG_ 996 NetCfg_BSMO 7;
BA_ "FlexKomSigName" SG_ 996 NetCfg_BSMO "NET_CFG_DATA_PT";
BA_ "FlexKomSigLaenge" SG_ 996 NetCfg_BSMO 64;
BA_ "FlexKomSID" SG_ 996 NetCfg_BSMO 39;
BA_ "FlexKomIsMotorola" SG_ 996 NetCfg_BSMO 1;
BA_ "FlexKomComment" SG_ 996 NetCfg_BSMO "Network ECU config data for Powertrain";
BA_ "GenSigTimeout_ORC" SG_ 996 NetCfg_CBC_PT 7000;
BA_ "GenSigTimeout_OCM" SG_ 996 NetCfg_CBC_PT 21000;
BA_ "GenSigTimeout_IC" SG_ 996 NetCfg_CBC_PT 21000;
BA_ "GenSigTimeout_ESM" SG_ 996 NetCfg_CBC_PT 21000;
BA_ "GenSigTimeout_EHPS" SG_ 996 NetCfg_CBC_PT 21000;
BA_ "GenSigTimeout_DPDM" SG_ 996 NetCfg_CBC_PT 21000;
BA_ "GenSigSNA" SG_ 996 NetCfg_CBC_PT "0h";
BA_ "GenSigSendType" SG_ 996 NetCfg_CBC_PT 5;
BA_ "GenSigCycleTime" SG_ 996 NetCfg_CBC_PT 2000;
BA_ "FlexKomSigStartValue" SG_ 996 NetCfg_CBC_PT "0300000000000000h";
BA_ "FlexKomSigStartPos" SG_ 996 NetCfg_CBC_PT 7;
BA_ "FlexKomSigName" SG_ 996 NetCfg_CBC_PT "NET_CFG_DATA_PT";
BA_ "FlexKomSigLaenge" SG_ 996 NetCfg_CBC_PT 64;
BA_ "FlexKomSID" SG_ 996 NetCfg_CBC_PT 39;
BA_ "FlexKomIsMotorola" SG_ 996 NetCfg_CBC_PT 1;
BA_ "FlexKomComment" SG_ 996 NetCfg_CBC_PT "Network ECU config data for Powertrain";
BA_ "GenSigTimeout_ORC" SG_ 996 NetCfg_DASM 7000;
BA_ "GenSigTimeout_IC" SG_ 996 NetCfg_DASM 21000;
BA_ "GenSigSNA" SG_ 996 NetCfg_DASM "0h";
BA_ "GenSigSendType" SG_ 996 NetCfg_DASM 5;
BA_ "GenSigCycleTime" SG_ 996 NetCfg_DASM 2000;
BA_ "FlexKomSigStartValue" SG_ 996 NetCfg_DASM "0300000000000000h";
BA_ "FlexKomSigStartPos" SG_ 996 NetCfg_DASM 7;
BA_ "FlexKomSigName" SG_ 996 NetCfg_DASM "NET_CFG_DATA_PT";
BA_ "FlexKomSigLaenge" SG_ 996 NetCfg_DASM 64;
BA_ "FlexKomSID" SG_ 996 NetCfg_DASM 39;
BA_ "FlexKomIsMotorola" SG_ 996 NetCfg_DASM 1;
BA_ "FlexKomComment" SG_ 996 NetCfg_DASM "Network ECU config data for Powertrain";
BA_ "GenSigSNA" SG_ 996 NetCfg_DPDM "0h";
BA_ "GenSigSendType" SG_ 996 NetCfg_DPDM 5;
BA_ "GenSigCycleTime" SG_ 996 NetCfg_DPDM 2000;
BA_ "FlexKomSigStartValue" SG_ 996 NetCfg_DPDM "0300000000000000h";
BA_ "FlexKomSigStartPos" SG_ 996 NetCfg_DPDM 7;
BA_ "FlexKomSigName" SG_ 996 NetCfg_DPDM "NET_CFG_DATA_PT";
BA_ "FlexKomSigLaenge" SG_ 996 NetCfg_DPDM 64;
BA_ "FlexKomSID" SG_ 996 NetCfg_DPDM 39;
BA_ "FlexKomIsMotorola" SG_ 996 NetCfg_DPDM 1;
BA_ "FlexKomComment" SG_ 996 NetCfg_DPDM "Network ECU config data for Powertrain";
BA_ "GenSigTimeout_ORC" SG_ 996 NetCfg_DTCM 7000;
BA_ "GenSigTimeout_IC" SG_ 996 NetCfg_DTCM 21000;
BA_ "GenSigSNA" SG_ 996 NetCfg_DTCM "0h";
BA_ "GenSigSendType" SG_ 996 NetCfg_DTCM 5;
BA_ "GenSigCycleTime" SG_ 996 NetCfg_DTCM 2000;
BA_ "FlexKomSigStartValue" SG_ 996 NetCfg_DTCM "0300000000000000h";
BA_ "FlexKomSigStartPos" SG_ 996 NetCfg_DTCM 7;
BA_ "FlexKomSigName" SG_ 996 NetCfg_DTCM "NET_CFG_DATA_PT";
BA_ "FlexKomSigLaenge" SG_ 996 NetCfg_DTCM 64;
BA_ "FlexKomSID" SG_ 996 NetCfg_DTCM 39;
BA_ "FlexKomIsMotorola" SG_ 996 NetCfg_DTCM 1;
BA_ "FlexKomComment" SG_ 996 NetCfg_DTCM "Network ECU config data for Powertrain";
BA_ "GenSigTimeout_TPM" SG_ 996 NetCfg_ECM 21000;
BA_ "GenSigTimeout_ORC" SG_ 996 NetCfg_ECM 7000;
BA_ "GenSigTimeout_OCM" SG_ 996 NetCfg_ECM 21000;
BA_ "GenSigTimeout_IC" SG_ 996 NetCfg_ECM 21000;
BA_ "GenSigTimeout_ESM" SG_ 996 NetCfg_ECM 21000;
BA_ "GenSigTimeout_EHPS" SG_ 996 NetCfg_ECM 21000;
BA_ "GenSigTimeout_DTCM" SG_ 996 NetCfg_ECM 21000;
BA_ "GenSigTimeout_DPDM" SG_ 996 NetCfg_ECM 21000;
BA_ "GenSigSNA" SG_ 996 NetCfg_ECM "0h";
BA_ "GenSigSendType" SG_ 996 NetCfg_ECM 5;
BA_ "GenSigCycleTime" SG_ 996 NetCfg_ECM 2000;
BA_ "FlexKomSigStartValue" SG_ 996 NetCfg_ECM "0300000000000000h";
BA_ "FlexKomSigStartPos" SG_ 996 NetCfg_ECM 7;
BA_ "FlexKomSigName" SG_ 996 NetCfg_ECM "NET_CFG_DATA_PT";
BA_ "FlexKomSigLaenge" SG_ 996 NetCfg_ECM 64;
BA_ "FlexKomSID" SG_ 996 NetCfg_ECM 39;
BA_ "FlexKomIsMotorola" SG_ 996 NetCfg_ECM 1;
BA_ "FlexKomComment" SG_ 996 NetCfg_ECM "Network ECU config data for Powertrain";
BA_ "GenSigTimeout_IC" SG_ 996 NetCfg_ELSD 21000;
BA_ "GenSigSNA" SG_ 996 NetCfg_ELSD "0h";
BA_ "GenSigSendType" SG_ 996 NetCfg_ELSD 5;
BA_ "GenSigCycleTime" SG_ 996 NetCfg_ELSD 2000;
BA_ "FlexKomSigStartValue" SG_ 996 NetCfg_ELSD "0300000000000000h";
BA_ "FlexKomSigStartPos" SG_ 996 NetCfg_ELSD 7;
BA_ "FlexKomSigName" SG_ 996 NetCfg_ELSD "NET_CFG_DATA_PT";
BA_ "FlexKomSigLaenge" SG_ 996 NetCfg_ELSD 64;
BA_ "FlexKomSID" SG_ 996 NetCfg_ELSD 39;
BA_ "FlexKomIsMotorola" SG_ 996 NetCfg_ELSD 1;
BA_ "FlexKomComment" SG_ 996 NetCfg_ELSD "Network ECU config data for Powertrain";
BA_ "GenSigTimeout_ORC" SG_ 996 NetCfg_EPB 7000;
BA_ "GenSigTimeout_IC" SG_ 996 NetCfg_EPB 21000;
BA_ "GenSigSNA" SG_ 996 NetCfg_EPB "0h";
BA_ "GenSigSendType" SG_ 996 NetCfg_EPB 5;
BA_ "GenSigCycleTime" SG_ 996 NetCfg_EPB 2000;
BA_ "FlexKomSigStartValue" SG_ 996 NetCfg_EPB "0300000000000000h";
BA_ "FlexKomSigStartPos" SG_ 996 NetCfg_EPB 7;
BA_ "FlexKomSigName" SG_ 996 NetCfg_EPB "NET_CFG_DATA_PT";
BA_ "FlexKomSigLaenge" SG_ 996 NetCfg_EPB 64;
BA_ "FlexKomSID" SG_ 996 NetCfg_EPB 39;
BA_ "FlexKomIsMotorola" SG_ 996 NetCfg_EPB 1;
BA_ "FlexKomComment" SG_ 996 NetCfg_EPB "Network ECU config data for Powertrain";
BA_ "GenSigTimeout_ORC" SG_ 996 NetCfg_EPPM 7000;
BA_ "GenSigSNA" SG_ 996 NetCfg_EPPM "0h";
BA_ "GenSigSendType" SG_ 996 NetCfg_EPPM 5;
BA_ "GenSigCycleTime" SG_ 996 NetCfg_EPPM 2000;
BA_ "FlexKomSigStartValue" SG_ 996 NetCfg_EPPM "0300000000000000h";
BA_ "FlexKomSigStartPos" SG_ 996 NetCfg_EPPM 7;
BA_ "FlexKomSigName" SG_ 996 NetCfg_EPPM "NET_CFG_DATA_PT";
BA_ "FlexKomSigLaenge" SG_ 996 NetCfg_EPPM 64;
BA_ "FlexKomSID" SG_ 996 NetCfg_EPPM 39;
BA_ "FlexKomIsMotorola" SG_ 996 NetCfg_EPPM 1;
BA_ "FlexKomComment" SG_ 996 NetCfg_EPPM "Network ECU config data for Powertrain";
BA_ "GenSigTimeout_ORC" SG_ 996 NetCfg_EPS 7000;
BA_ "GenSigTimeout_IC" SG_ 996 NetCfg_EPS 21000;
BA_ "GenSigSNA" SG_ 996 NetCfg_EPS "0h";
BA_ "GenSigSendType" SG_ 996 NetCfg_EPS 5;
BA_ "GenSigCycleTime" SG_ 996 NetCfg_EPS 2000;
BA_ "FlexKomSigStartValue" SG_ 996 NetCfg_EPS "0300000000000000h";
BA_ "FlexKomSigStartPos" SG_ 996 NetCfg_EPS 7;
BA_ "FlexKomSigName" SG_ 996 NetCfg_EPS "NET_CFG_DATA_PT";
BA_ "FlexKomSigLaenge" SG_ 996 NetCfg_EPS 64;
BA_ "FlexKomSID" SG_ 996 NetCfg_EPS 39;
BA_ "FlexKomIsMotorola" SG_ 996 NetCfg_EPS 1;
BA_ "FlexKomComment" SG_ 996 NetCfg_EPS "Network ECU config data for Powertrain";
BA_ "GenSigTimeout_TPM" SG_ 996 NetCfg_ESC 21000;
BA_ "GenSigTimeout_ORC" SG_ 996 NetCfg_ESC 7000;
BA_ "GenSigTimeout_IC" SG_ 996 NetCfg_ESC 21000;
BA_ "GenSigTimeout_ESM" SG_ 996 NetCfg_ESC 21000;
BA_ "GenSigTimeout_EHPS" SG_ 996 NetCfg_ESC 21000;
BA_ "GenSigTimeout_DTCM" SG_ 996 NetCfg_ESC 21000;
BA_ "GenSigSNA" SG_ 996 NetCfg_ESC "0h";
BA_ "GenSigSendType" SG_ 996 NetCfg_ESC 5;
BA_ "GenSigCycleTime" SG_ 996 NetCfg_ESC 2000;
BA_ "FlexKomSigStartValue" SG_ 996 NetCfg_ESC "0300000000000000h";
BA_ "FlexKomSigStartPos" SG_ 996 NetCfg_ESC 7;
BA_ "FlexKomSigName" SG_ 996 NetCfg_ESC "NET_CFG_DATA_PT";
BA_ "FlexKomSigLaenge" SG_ 996 NetCfg_ESC 64;
BA_ "FlexKomSID" SG_ 996 NetCfg_ESC 39;
BA_ "FlexKomIsMotorola" SG_ 996 NetCfg_ESC 1;
BA_ "FlexKomComment" SG_ 996 NetCfg_ESC "Network ECU config data for Powertrain";
BA_ "GenSigSNA" SG_ 996 NetCfg_ESL "0h";
BA_ "GenSigSendType" SG_ 996 NetCfg_ESL 5;
BA_ "GenSigCycleTime" SG_ 996 NetCfg_ESL 2000;
BA_ "FlexKomSigStartValue" SG_ 996 NetCfg_ESL "0300000000000000h";
BA_ "FlexKomSigStartPos" SG_ 996 NetCfg_ESL 7;
BA_ "FlexKomSigName" SG_ 996 NetCfg_ESL "NET_CFG_DATA_PT";
BA_ "FlexKomSigLaenge" SG_ 996 NetCfg_ESL 64;
BA_ "FlexKomSID" SG_ 996 NetCfg_ESL 39;
BA_ "FlexKomIsMotorola" SG_ 996 NetCfg_ESL 1;
BA_ "FlexKomComment" SG_ 996 NetCfg_ESL "Network ECU config data for Powertrain";
BA_ "GenSigTimeout_IC" SG_ 996 NetCfg_ESM 21000;
BA_ "GenSigTimeout_ESM" SG_ 996 NetCfg_ESM 21000;
BA_ "GenSigTimeout_DTCM" SG_ 996 NetCfg_ESM 21000;
BA_ "GenSigSNA" SG_ 996 NetCfg_ESM "0h";
BA_ "GenSigSendType" SG_ 996 NetCfg_ESM 5;
BA_ "GenSigCycleTime" SG_ 996 NetCfg_ESM 2000;
BA_ "FlexKomSigStartValue" SG_ 996 NetCfg_ESM "0300000000000000h";
BA_ "FlexKomSigStartPos" SG_ 996 NetCfg_ESM 7;
BA_ "FlexKomSigName" SG_ 996 NetCfg_ESM "NET_CFG_DATA_PT";
BA_ "FlexKomSigLaenge" SG_ 996 NetCfg_ESM 64;
BA_ "FlexKomSID" SG_ 996 NetCfg_ESM 39;
BA_ "FlexKomIsMotorola" SG_ 996 NetCfg_ESM 1;
BA_ "FlexKomComment" SG_ 996 NetCfg_ESM "Network ECU config data for Powertrain";
BA_ "GenSigSNA" SG_ 996 NetCfg_FDCM "0h";
BA_ "GenSigSendType" SG_ 996 NetCfg_FDCM 5;
BA_ "GenSigCycleTime" SG_ 996 NetCfg_FDCM 2000;
BA_ "FlexKomSigStartValue" SG_ 996 NetCfg_FDCM "0300000000000000h";
BA_ "FlexKomSigStartPos" SG_ 996 NetCfg_FDCM 7;
BA_ "FlexKomSigName" SG_ 996 NetCfg_FDCM "NET_CFG_DATA_PT";
BA_ "FlexKomSigLaenge" SG_ 996 NetCfg_FDCM 64;
BA_ "FlexKomSID" SG_ 996 NetCfg_FDCM 39;
BA_ "FlexKomIsMotorola" SG_ 996 NetCfg_FDCM 1;
BA_ "FlexKomComment" SG_ 996 NetCfg_FDCM "Network ECU config data for Powertrain";
BA_ "GenSigTimeout_TPM" SG_ 996 NetCfg_GPF 21000;
BA_ "GenSigTimeout_ORC" SG_ 996 NetCfg_GPF 7000;
BA_ "GenSigTimeout_OCM" SG_ 996 NetCfg_GPF 21000;
BA_ "GenSigTimeout_IC" SG_ 996 NetCfg_GPF 21000;
BA_ "GenSigTimeout_ESM" SG_ 996 NetCfg_GPF 21000;
BA_ "GenSigTimeout_EHPS" SG_ 996 NetCfg_GPF 21000;
BA_ "GenSigTimeout_DTCM" SG_ 996 NetCfg_GPF 21000;
BA_ "GenSigTimeout_DPDM" SG_ 996 NetCfg_GPF 21000;
BA_ "GenSigSNA" SG_ 996 NetCfg_GPF "0h";
BA_ "GenSigSendType" SG_ 996 NetCfg_GPF 5;
BA_ "GenSigCycleTime" SG_ 996 NetCfg_GPF 2000;
BA_ "FlexKomSigStartValue" SG_ 996 NetCfg_GPF "0300000000000000h";
BA_ "FlexKomSigStartPos" SG_ 996 NetCfg_GPF 7;
BA_ "FlexKomSigName" SG_ 996 NetCfg_GPF "NET_CFG_DATA_PT";
BA_ "FlexKomSigLaenge" SG_ 996 NetCfg_GPF 64;
BA_ "FlexKomSID" SG_ 996 NetCfg_GPF 39;
BA_ "FlexKomIsMotorola" SG_ 996 NetCfg_GPF 1;
BA_ "FlexKomComment" SG_ 996 NetCfg_GPF "Network ECU config data for Powertrain";
BA_ "GenSigTimeout_ORC" SG_ 996 NetCfg_HCP 7000;
BA_ "GenSigSNA" SG_ 996 NetCfg_HCP "0h";
BA_ "GenSigSendType" SG_ 996 NetCfg_HCP 5;
BA_ "GenSigCycleTime" SG_ 996 NetCfg_HCP 2000;
BA_ "FlexKomSigStartValue" SG_ 996 NetCfg_HCP "0300000000000000h";
BA_ "FlexKomSigStartPos" SG_ 996 NetCfg_HCP 7;
BA_ "FlexKomSigName" SG_ 996 NetCfg_HCP "NET_CFG_DATA_PT";
BA_ "FlexKomSigLaenge" SG_ 996 NetCfg_HCP 64;
BA_ "FlexKomSID" SG_ 996 NetCfg_HCP 39;
BA_ "FlexKomIsMotorola" SG_ 996 NetCfg_HCP 1;
BA_ "FlexKomComment" SG_ 996 NetCfg_HCP "Network ECU config data for Powertrain";
BA_ "GenSigSNA" SG_ 996 NetCfg_HaLF "0h";
BA_ "GenSigSendType" SG_ 996 NetCfg_HaLF 5;
BA_ "GenSigCycleTime" SG_ 996 NetCfg_HaLF 2000;
BA_ "FlexKomSigStartValue" SG_ 996 NetCfg_HaLF "0300000000000000h";
BA_ "FlexKomSigStartPos" SG_ 996 NetCfg_HaLF 7;
BA_ "FlexKomSigName" SG_ 996 NetCfg_HaLF "NET_CFG_DATA_PT";
BA_ "FlexKomSigLaenge" SG_ 996 NetCfg_HaLF 64;
BA_ "FlexKomSID" SG_ 996 NetCfg_HaLF 39;
BA_ "FlexKomIsMotorola" SG_ 996 NetCfg_HaLF 1;
BA_ "FlexKomComment" SG_ 996 NetCfg_HaLF "Network ECU config data for Powertrain";
BA_ "GenSigTimeout_TPM" SG_ 996 NetCfg_IC 21000;
BA_ "GenSigTimeout_IC" SG_ 996 NetCfg_IC 21000;
BA_ "GenSigTimeout_ESM" SG_ 996 NetCfg_IC 21000;
BA_ "GenSigTimeout_EHPS" SG_ 996 NetCfg_IC 21000;
BA_ "GenSigSNA" SG_ 996 NetCfg_IC "0h";
BA_ "GenSigSendType" SG_ 996 NetCfg_IC 5;
BA_ "GenSigCycleTime" SG_ 996 NetCfg_IC 2000;
BA_ "FlexKomSigStartValue" SG_ 996 NetCfg_IC "0300000000000000h";
BA_ "FlexKomSigStartPos" SG_ 996 NetCfg_IC 7;
BA_ "FlexKomSigName" SG_ 996 NetCfg_IC "NET_CFG_DATA_PT";
BA_ "FlexKomSigLaenge" SG_ 996 NetCfg_IC 64;
BA_ "FlexKomSID" SG_ 996 NetCfg_IC 39;
BA_ "FlexKomIsMotorola" SG_ 996 NetCfg_IC 1;
BA_ "FlexKomComment" SG_ 996 NetCfg_IC "Network ECU config data for Powertrain";
BA_ "GenSigTimeout_IC" SG_ 996 NetCfg_ITBM 21000;
BA_ "GenSigSNA" SG_ 996 NetCfg_ITBM "0h";
BA_ "GenSigSendType" SG_ 996 NetCfg_ITBM 5;
BA_ "GenSigCycleTime" SG_ 996 NetCfg_ITBM 2000;
BA_ "FlexKomSigStartValue" SG_ 996 NetCfg_ITBM "0300000000000000h";
BA_ "FlexKomSigStartPos" SG_ 996 NetCfg_ITBM 7;
BA_ "FlexKomSigName" SG_ 996 NetCfg_ITBM "NET_CFG_DATA_PT";
BA_ "FlexKomSigLaenge" SG_ 996 NetCfg_ITBM 64;
BA_ "FlexKomSID" SG_ 996 NetCfg_ITBM 39;
BA_ "FlexKomIsMotorola" SG_ 996 NetCfg_ITBM 1;
BA_ "FlexKomComment" SG_ 996 NetCfg_ITBM "Network ECU config data for Powertrain";
BA_ "GenSigTimeout_ORC" SG_ 996 NetCfg_OCM 7000;
BA_ "GenSigSNA" SG_ 996 NetCfg_OCM "0h";
BA_ "GenSigSendType" SG_ 996 NetCfg_OCM 5;
BA_ "GenSigCycleTime" SG_ 996 NetCfg_OCM 2000;
BA_ "FlexKomSigStartValue" SG_ 996 NetCfg_OCM "0300000000000000h";
BA_ "FlexKomSigStartPos" SG_ 996 NetCfg_OCM 7;
BA_ "FlexKomSigName" SG_ 996 NetCfg_OCM "NET_CFG_DATA_PT";
BA_ "FlexKomSigLaenge" SG_ 996 NetCfg_OCM 64;
BA_ "FlexKomSID" SG_ 996 NetCfg_OCM 39;
BA_ "FlexKomIsMotorola" SG_ 996 NetCfg_OCM 1;
BA_ "FlexKomComment" SG_ 996 NetCfg_OCM "Network ECU config data for Powertrain";
BA_ "GenSigTimeout_OCM" SG_ 996 NetCfg_ORC 21000;
BA_ "GenSigTimeout_IC" SG_ 996 NetCfg_ORC 21000;
BA_ "GenSigTimeout_DPDM" SG_ 996 NetCfg_ORC 21000;
BA_ "GenSigSNA" SG_ 996 NetCfg_ORC "0h";
BA_ "GenSigSendType" SG_ 996 NetCfg_ORC 5;
BA_ "GenSigCycleTime" SG_ 996 NetCfg_ORC 2000;
BA_ "FlexKomSigStartValue" SG_ 996 NetCfg_ORC "0300000000000000h";
BA_ "FlexKomSigStartPos" SG_ 996 NetCfg_ORC 7;
BA_ "FlexKomSigName" SG_ 996 NetCfg_ORC "NET_CFG_DATA_PT";
BA_ "FlexKomSigLaenge" SG_ 996 NetCfg_ORC 64;
BA_ "FlexKomSID" SG_ 996 NetCfg_ORC 39;
BA_ "FlexKomIsMotorola" SG_ 996 NetCfg_ORC 1;
BA_ "FlexKomComment" SG_ 996 NetCfg_ORC "Network ECU config data for Powertrain";
BA_ "GenSigTimeout_IC" SG_ 996 NetCfg_PASS_PT 21000;
BA_ "GenSigSNA" SG_ 996 NetCfg_PASS_PT "0h";
BA_ "GenSigSendType" SG_ 996 NetCfg_PASS_PT 5;
BA_ "GenSigCycleTime" SG_ 996 NetCfg_PASS_PT 2000;
BA_ "FlexKomSigStartValue" SG_ 996 NetCfg_PASS_PT "0300000000000000h";
BA_ "FlexKomSigStartPos" SG_ 996 NetCfg_PASS_PT 7;
BA_ "FlexKomSigName" SG_ 996 NetCfg_PASS_PT "NET_CFG_DATA_PT";
BA_ "FlexKomSigLaenge" SG_ 996 NetCfg_PASS_PT 64;
BA_ "FlexKomSID" SG_ 996 NetCfg_PASS_PT 39;
BA_ "FlexKomIsMotorola" SG_ 996 NetCfg_PASS_PT 1;
BA_ "FlexKomComment" SG_ 996 NetCfg_PASS_PT "Network ECU config data for Powertrain";
BA_ "GenSigTimeout_IC" SG_ 996 NetCfg_PTS 21000;
BA_ "GenSigSNA" SG_ 996 NetCfg_PTS "0h";
BA_ "GenSigSendType" SG_ 996 NetCfg_PTS 5;
BA_ "GenSigCycleTime" SG_ 996 NetCfg_PTS 2000;
BA_ "FlexKomSigStartValue" SG_ 996 NetCfg_PTS "0300000000000000h";
BA_ "FlexKomSigStartPos" SG_ 996 NetCfg_PTS 7;
BA_ "FlexKomSigName" SG_ 996 NetCfg_PTS "NET_CFG_DATA_PT";
BA_ "FlexKomSigLaenge" SG_ 996 NetCfg_PTS 64;
BA_ "FlexKomSID" SG_ 996 NetCfg_PTS 39;
BA_ "FlexKomIsMotorola" SG_ 996 NetCfg_PTS 1;
BA_ "FlexKomComment" SG_ 996 NetCfg_PTS "Network ECU config data for Powertrain";
BA_ "GenSigTimeout_TPM" SG_ 996 NetCfg_RF_HUB 21000;
BA_ "GenSigTimeout_IC" SG_ 996 NetCfg_RF_HUB 21000;
BA_ "GenSigSNA" SG_ 996 NetCfg_RF_HUB "0h";
BA_ "GenSigSendType" SG_ 996 NetCfg_RF_HUB 5;
BA_ "GenSigCycleTime" SG_ 996 NetCfg_RF_HUB 2000;
BA_ "FlexKomSigStartValue" SG_ 996 NetCfg_RF_HUB "0300000000000000h";
BA_ "FlexKomSigStartPos" SG_ 996 NetCfg_RF_HUB 7;
BA_ "FlexKomSigName" SG_ 996 NetCfg_RF_HUB "NET_CFG_DATA_PT";
BA_ "FlexKomSigLaenge" SG_ 996 NetCfg_RF_HUB 64;
BA_ "FlexKomSID" SG_ 996 NetCfg_RF_HUB 39;
BA_ "FlexKomIsMotorola" SG_ 996 NetCfg_RF_HUB 1;
BA_ "FlexKomComment" SG_ 996 NetCfg_RF_HUB "Network ECU config data for Powertrain";
BA_ "GenSigTimeout_SCCM" SG_ 996 NetCfg_SCCM 21000;
BA_ "GenSigTimeout_ORC" SG_ 996 NetCfg_SCCM 7000;
BA_ "GenSigTimeout_IC" SG_ 996 NetCfg_SCCM 21000;
BA_ "GenSigTimeout_EHPS" SG_ 996 NetCfg_SCCM 21000;
BA_ "GenSigTimeout_DTCM" SG_ 996 NetCfg_SCCM 21000;
BA_ "GenSigSNA" SG_ 996 NetCfg_SCCM "0h";
BA_ "GenSigSendType" SG_ 996 NetCfg_SCCM 5;
BA_ "GenSigCycleTime" SG_ 996 NetCfg_SCCM 2000;
BA_ "FlexKomSigStartValue" SG_ 996 NetCfg_SCCM "0300000000000000h";
BA_ "FlexKomSigStartPos" SG_ 996 NetCfg_SCCM 7;
BA_ "FlexKomSigName" SG_ 996 NetCfg_SCCM "NET_CFG_DATA_PT";
BA_ "FlexKomSigLaenge" SG_ 996 NetCfg_SCCM 64;
BA_ "FlexKomSID" SG_ 996 NetCfg_SCCM 39;
BA_ "FlexKomIsMotorola" SG_ 996 NetCfg_SCCM 1;
BA_ "FlexKomComment" SG_ 996 NetCfg_SCCM "Network ECU config data for Powertrain";
BA_ "GenSigSNA" SG_ 996 NetCfg_SGW "0h";
BA_ "GenSigSendType" SG_ 996 NetCfg_SGW 5;
BA_ "GenSigCycleTime" SG_ 996 NetCfg_SGW 2000;
BA_ "FlexKomSigStartValue" SG_ 996 NetCfg_SGW "0300000000000000h";
BA_ "FlexKomSigStartPos" SG_ 996 NetCfg_SGW 7;
BA_ "FlexKomSigName" SG_ 996 NetCfg_SGW "NET_CFG_DATA_PT";
BA_ "FlexKomSigLaenge" SG_ 996 NetCfg_SGW 64;
BA_ "FlexKomSID" SG_ 996 NetCfg_SGW 39;
BA_ "FlexKomIsMotorola" SG_ 996 NetCfg_SGW 1;
BA_ "FlexKomComment" SG_ 996 NetCfg_SGW "Network ECU config data for Powertrain";
BA_ "GenSigTimeout_ORC" SG_ 996 NetCfg_TCM 7000;
BA_ "GenSigTimeout_IC" SG_ 996 NetCfg_TCM 21000;
BA_ "GenSigTimeout_ESM" SG_ 996 NetCfg_TCM 21000;
BA_ "GenSigTimeout_DTCM" SG_ 996 NetCfg_TCM 21000;
BA_ "GenSigSNA" SG_ 996 NetCfg_TCM "0h";
BA_ "GenSigSendType" SG_ 996 NetCfg_TCM 5;
BA_ "GenSigCycleTime" SG_ 996 NetCfg_TCM 2000;
BA_ "FlexKomSigStartValue" SG_ 996 NetCfg_TCM "0300000000000000h";
BA_ "FlexKomSigStartPos" SG_ 996 NetCfg_TCM 7;
BA_ "FlexKomSigName" SG_ 996 NetCfg_TCM "NET_CFG_DATA_PT";
BA_ "FlexKomSigLaenge" SG_ 996 NetCfg_TCM 64;
BA_ "FlexKomSID" SG_ 996 NetCfg_TCM 39;
BA_ "FlexKomIsMotorola" SG_ 996 NetCfg_TCM 1;
BA_ "FlexKomComment" SG_ 996 NetCfg_TCM "Network ECU config data for Powertrain";
BA_ "GenSigSNA" SG_ 996 NetCfg_TIM "0h";
BA_ "GenSigSendType" SG_ 996 NetCfg_TIM 5;
BA_ "GenSigCycleTime" SG_ 996 NetCfg_TIM 2000;
BA_ "FlexKomSigStartValue" SG_ 996 NetCfg_TIM "0300000000000000h";
BA_ "FlexKomSigStartPos" SG_ 996 NetCfg_TIM 7;
BA_ "FlexKomSigName" SG_ 996 NetCfg_TIM "NET_CFG_DATA_PT";
BA_ "FlexKomSigLaenge" SG_ 996 NetCfg_TIM 64;
BA_ "FlexKomSID" SG_ 996 NetCfg_TIM 39;
BA_ "FlexKomIsMotorola" SG_ 996 NetCfg_TIM 1;
BA_ "FlexKomComment" SG_ 996 NetCfg_TIM "Network ECU config data for Powertrain";
BA_ "GenSigTimeout_ORC" SG_ 996 NetCfg_TPM 7000;
BA_ "GenSigTimeout_IC" SG_ 996 NetCfg_TPM 21000;
BA_ "GenSigSNA" SG_ 996 NetCfg_TPM "0h";
BA_ "GenSigSendType" SG_ 996 NetCfg_TPM 5;
BA_ "GenSigCycleTime" SG_ 996 NetCfg_TPM 2000;
BA_ "FlexKomSigStartValue" SG_ 996 NetCfg_TPM "0300000000000000h";
BA_ "FlexKomSigStartPos" SG_ 996 NetCfg_TPM 7;
BA_ "FlexKomSigName" SG_ 996 NetCfg_TPM "NET_CFG_DATA_PT";
BA_ "FlexKomSigLaenge" SG_ 996 NetCfg_TPM 64;
BA_ "FlexKomSID" SG_ 996 NetCfg_TPM 39;
BA_ "FlexKomIsMotorola" SG_ 996 NetCfg_TPM 1;
BA_ "FlexKomComment" SG_ 996 NetCfg_TPM "Network ECU config data for Powertrain";
BA_ "GenSigSNA" SG_ 996 NetCfg_TTPM "0h";
BA_ "GenSigSendType" SG_ 996 NetCfg_TTPM 5;
BA_ "GenSigCycleTime" SG_ 996 NetCfg_TTPM 2000;
BA_ "FlexKomSigStartValue" SG_ 996 NetCfg_TTPM "0300000000000000h";
BA_ "FlexKomSigStartPos" SG_ 996 NetCfg_TTPM 7;
BA_ "FlexKomSigName" SG_ 996 NetCfg_TTPM "NET_CFG_DATA_PT";
BA_ "FlexKomSigLaenge" SG_ 996 NetCfg_TTPM 64;
BA_ "FlexKomSID" SG_ 996 NetCfg_TTPM 39;
BA_ "FlexKomIsMotorola" SG_ 996 NetCfg_TTPM 1;
BA_ "FlexKomComment" SG_ 996 NetCfg_TTPM "Network ECU config data for Powertrain";
BA_ "GenSigTimeout_IC" SG_ 996 NetCfg_VSIM_C 21000;
BA_ "GenSigSNA" SG_ 996 NetCfg_VSIM_C "0h";
BA_ "GenSigSendType" SG_ 996 NetCfg_VSIM_C 5;
BA_ "GenSigCycleTime" SG_ 996 NetCfg_VSIM_C 2000;
BA_ "FlexKomSigStartValue" SG_ 996 NetCfg_VSIM_C "0300000000000000h";
BA_ "FlexKomSigStartPos" SG_ 996 NetCfg_VSIM_C 7;
BA_ "FlexKomSigName" SG_ 996 NetCfg_VSIM_C "NET_CFG_DATA_PT";
BA_ "FlexKomSigLaenge" SG_ 996 NetCfg_VSIM_C 64;
BA_ "FlexKomSID" SG_ 996 NetCfg_VSIM_C 39;
BA_ "FlexKomIsMotorola" SG_ 996 NetCfg_VSIM_C 1;
BA_ "FlexKomComment" SG_ 996 NetCfg_VSIM_C "Network ECU config data for Powertrain";
BA_ "GenSigSNA" SG_ 1025 Awake_Diag_Actv "0h";
BA_ "GenSigSendType" SG_ 1025 Awake_Diag_Actv 1;
BA_ "FlexKomSigStartValue" SG_ 1025 Awake_Diag_Actv "000000h";
BA_ "FlexKomSigStartPos" SG_ 1025 Awake_Diag_Actv 39;
BA_ "FlexKomSigName" SG_ 1025 Awake_Diag_Actv "Awake_CBC";
BA_ "FlexKomSigLaenge" SG_ 1025 Awake_Diag_Actv 24;
BA_ "FlexKomSID" SG_ 1025 Awake_Diag_Actv 504;
BA_ "FlexKomIsMotorola" SG_ 1025 Awake_Diag_Actv 1;
BA_ "FlexKomComment" SG_ 1025 Awake_Diag_Actv "Mode 15 of NM_Ud_Srv";
BA_ "GenSigSNA" SG_ 1025 Awake_NwSt "0h";
BA_ "GenSigSendType" SG_ 1025 Awake_NwSt 1;
BA_ "FlexKomSigStartValue" SG_ 1025 Awake_NwSt "000000h";
BA_ "FlexKomSigStartPos" SG_ 1025 Awake_NwSt 39;
BA_ "FlexKomSigName" SG_ 1025 Awake_NwSt "Awake_CBC";
BA_ "FlexKomSigLaenge" SG_ 1025 Awake_NwSt 24;
BA_ "FlexKomSID" SG_ 1025 Awake_NwSt 504;
BA_ "FlexKomIsMotorola" SG_ 1025 Awake_NwSt 1;
BA_ "FlexKomComment" SG_ 1025 Awake_NwSt "Mode 15 of NM_Ud_Srv";
BA_ "GenSigStartValue" SG_ 1025 NM_Mode 255;
BA_ "GenSigSNA" SG_ 1025 NM_Mode "FFh";
BA_ "GenSigSendType" SG_ 1025 NM_Mode 1;
BA_ "FlexKomSigStartValue" SG_ 1025 NM_Mode "FFFFFFFFh";
BA_ "FlexKomSigStartPos" SG_ 1025 NM_Mode 7;
BA_ "FlexKomSigName" SG_ 1025 NM_Mode "NM";
BA_ "FlexKomSigLaenge" SG_ 1025 NM_Mode 32;
BA_ "FlexKomSID" SG_ 1025 NM_Mode 472;
BA_ "FlexKomIsMotorola" SG_ 1025 NM_Mode 1;
BA_ "FlexKomComment" SG_ 1025 NM_Mode "Network management state";
BA_ "GenSigStartValue" SG_ 1025 NM_Sleep_Ack 1;
BA_ "GenSigSNA" SG_ 1025 NM_Sleep_Ack "1h";
BA_ "GenSigSendType" SG_ 1025 NM_Sleep_Ack 1;
BA_ "FlexKomSigStartValue" SG_ 1025 NM_Sleep_Ack "FFFFFFFFh";
BA_ "FlexKomSigStartPos" SG_ 1025 NM_Sleep_Ack 7;
BA_ "FlexKomSigName" SG_ 1025 NM_Sleep_Ack "NM";
BA_ "FlexKomSigLaenge" SG_ 1025 NM_Sleep_Ack 32;
BA_ "FlexKomSID" SG_ 1025 NM_Sleep_Ack 472;
BA_ "FlexKomIsMotorola" SG_ 1025 NM_Sleep_Ack 1;
BA_ "FlexKomComment" SG_ 1025 NM_Sleep_Ack "Network management state";
BA_ "GenSigStartValue" SG_ 1025 NM_Sleep_Ind 1;
BA_ "GenSigSNA" SG_ 1025 NM_Sleep_Ind "1h";
BA_ "GenSigSendType" SG_ 1025 NM_Sleep_Ind 1;
BA_ "FlexKomSigStartValue" SG_ 1025 NM_Sleep_Ind "FFFFFFFFh";
BA_ "FlexKomSigStartPos" SG_ 1025 NM_Sleep_Ind 7;
BA_ "FlexKomSigName" SG_ 1025 NM_Sleep_Ind "NM";
BA_ "FlexKomSigLaenge" SG_ 1025 NM_Sleep_Ind 32;
BA_ "FlexKomSID" SG_ 1025 NM_Sleep_Ind 472;
BA_ "FlexKomIsMotorola" SG_ 1025 NM_Sleep_Ind 1;
BA_ "FlexKomComment" SG_ 1025 NM_Sleep_Ind "Network management state";
BA_ "GenSigStartValue" SG_ 1025 NM_Successor 255;
BA_ "GenSigSNA" SG_ 1025 NM_Successor "FFh";
BA_ "GenSigSendType" SG_ 1025 NM_Successor 1;
BA_ "FlexKomSigStartValue" SG_ 1025 NM_Successor "FFFFFFFFh";
BA_ "FlexKomSigStartPos" SG_ 1025 NM_Successor 7;
BA_ "FlexKomSigName" SG_ 1025 NM_Successor "NM";
BA_ "FlexKomSigLaenge" SG_ 1025 NM_Successor 32;
BA_ "FlexKomSID" SG_ 1025 NM_Successor 472;
BA_ "FlexKomIsMotorola" SG_ 1025 NM_Successor 1;
BA_ "FlexKomComment" SG_ 1025 NM_Successor "Network management state";
BA_ "GenSigStartValue" SG_ 1025 NM_Ud_Launch 63;
BA_ "GenSigSNA" SG_ 1025 NM_Ud_Launch "3Fh";
BA_ "GenSigSendType" SG_ 1025 NM_Ud_Launch 1;
BA_ "FlexKomSigStartValue" SG_ 1025 NM_Ud_Launch "FFFFFFFFh";
BA_ "FlexKomSigStartPos" SG_ 1025 NM_Ud_Launch 7;
BA_ "FlexKomSigName" SG_ 1025 NM_Ud_Launch "NM";
BA_ "FlexKomSigLaenge" SG_ 1025 NM_Ud_Launch 32;
BA_ "FlexKomSID" SG_ 1025 NM_Ud_Launch 472;
BA_ "FlexKomIsMotorola" SG_ 1025 NM_Ud_Launch 1;
BA_ "FlexKomComment" SG_ 1025 NM_Ud_Launch "Network management state";
BA_ "GenSigStartValue" SG_ 1025 NM_Ud_Srv 255;
BA_ "GenSigSNA" SG_ 1025 NM_Ud_Srv "FFh";
BA_ "GenSigSendType" SG_ 1025 NM_Ud_Srv 1;
BA_ "FlexKomSigStartValue" SG_ 1025 NM_Ud_Srv "FFFFFFFFh";
BA_ "FlexKomSigStartPos" SG_ 1025 NM_Ud_Srv 7;
BA_ "FlexKomSigName" SG_ 1025 NM_Ud_Srv "NM";
BA_ "FlexKomSigLaenge" SG_ 1025 NM_Ud_Srv 32;
BA_ "FlexKomSID" SG_ 1025 NM_Ud_Srv 472;
BA_ "FlexKomIsMotorola" SG_ 1025 NM_Ud_Srv 1;
BA_ "FlexKomComment" SG_ 1025 NM_Ud_Srv "Network management state";
BA_ "GenSigStartValue" SG_ 1025 Nw_Id 255;
BA_ "GenSigSNA" SG_ 1025 Nw_Id "FFh";
BA_ "GenSigSendType" SG_ 1025 Nw_Id 1;
BA_ "FlexKomSigStartValue" SG_ 1025 Nw_Id "FFh";
BA_ "FlexKomSigStartPos" SG_ 1025 Nw_Id 63;
BA_ "FlexKomSigName" SG_ 1025 Nw_Id "Nw_Id";
BA_ "FlexKomSigLaenge" SG_ 1025 Nw_Id 8;
BA_ "FlexKomSID" SG_ 1025 Nw_Id 535;
BA_ "FlexKomIsMotorola" SG_ 1025 Nw_Id 1;
BA_ "FlexKomComment" SG_ 1025 Nw_Id "Network identification no.";
BA_ "GenSigStartValue" SG_ 1025 WakeupCnt 255;
BA_ "GenSigSNA" SG_ 1025 WakeupCnt "FFh";
BA_ "GenSigSendType" SG_ 1025 WakeupCnt 1;
BA_ "FlexKomSigStartValue" SG_ 1025 WakeupCnt "FFFF00h";
BA_ "FlexKomSigStartPos" SG_ 1025 WakeupCnt 39;
BA_ "FlexKomSigName" SG_ 1025 WakeupCnt "Wakeup_CBC";
BA_ "FlexKomSigLaenge" SG_ 1025 WakeupCnt 24;
BA_ "FlexKomSID" SG_ 1025 WakeupCnt 474;
BA_ "FlexKomIsMotorola" SG_ 1025 WakeupCnt 1;
BA_ "FlexKomComment" SG_ 1025 WakeupCnt "Mode 2 of NM_Ud_Srv";
BA_ "GenSigStartValue" SG_ 1025 WakeupRsn_CBC 255;
BA_ "GenSigSNA" SG_ 1025 WakeupRsn_CBC "FFh";
BA_ "GenSigSendType" SG_ 1025 WakeupRsn_CBC 1;
BA_ "FlexKomSigStartValue" SG_ 1025 WakeupRsn_CBC "FFFF00h";
BA_ "FlexKomSigStartPos" SG_ 1025 WakeupRsn_CBC 39;
BA_ "FlexKomSigName" SG_ 1025 WakeupRsn_CBC "Wakeup_CBC";
BA_ "FlexKomSigLaenge" SG_ 1025 WakeupRsn_CBC 24;
BA_ "FlexKomSID" SG_ 1025 WakeupRsn_CBC 474;
BA_ "FlexKomIsMotorola" SG_ 1025 WakeupRsn_CBC 1;
BA_ "FlexKomComment" SG_ 1025 WakeupRsn_CBC "Mode 2 of NM_Ud_Srv";
BA_ "GenSigSNA" SG_ 1050 Awake_Diag_Actv "0h";
BA_ "GenSigSendType" SG_ 1050 Awake_Diag_Actv 1;
BA_ "FlexKomSigStartValue" SG_ 1050 Awake_Diag_Actv "000000h";
BA_ "FlexKomSigStartPos" SG_ 1050 Awake_Diag_Actv 39;
BA_ "FlexKomSigName" SG_ 1050 Awake_Diag_Actv "Awake_EPS";
BA_ "FlexKomSigLaenge" SG_ 1050 Awake_Diag_Actv 24;
BA_ "FlexKomSID" SG_ 1050 Awake_Diag_Actv 1274;
BA_ "FlexKomIsMotorola" SG_ 1050 Awake_Diag_Actv 1;
BA_ "FlexKomComment" SG_ 1050 Awake_Diag_Actv "Mode 15 of NM_Ud_Srv";
BA_ "GenSigSNA" SG_ 1050 Awake_EngRPM_high "0h";
BA_ "GenSigSendType" SG_ 1050 Awake_EngRPM_high 1;
BA_ "FlexKomSigStartValue" SG_ 1050 Awake_EngRPM_high "000000h";
BA_ "FlexKomSigStartPos" SG_ 1050 Awake_EngRPM_high 39;
BA_ "FlexKomSigName" SG_ 1050 Awake_EngRPM_high "Awake_EPS";
BA_ "FlexKomSigLaenge" SG_ 1050 Awake_EngRPM_high 24;
BA_ "FlexKomSID" SG_ 1050 Awake_EngRPM_high 1274;
BA_ "FlexKomIsMotorola" SG_ 1050 Awake_EngRPM_high 1;
BA_ "FlexKomComment" SG_ 1050 Awake_EngRPM_high "Mode 15 of NM_Ud_Srv";
BA_ "GenSigSNA" SG_ 1050 Awake_IgnHigh "0h";
BA_ "GenSigSendType" SG_ 1050 Awake_IgnHigh 1;
BA_ "FlexKomSigStartValue" SG_ 1050 Awake_IgnHigh "000000h";
BA_ "FlexKomSigStartPos" SG_ 1050 Awake_IgnHigh 39;
BA_ "FlexKomSigName" SG_ 1050 Awake_IgnHigh "Awake_EPS";
BA_ "FlexKomSigLaenge" SG_ 1050 Awake_IgnHigh 24;
BA_ "FlexKomSID" SG_ 1050 Awake_IgnHigh 1274;
BA_ "FlexKomIsMotorola" SG_ 1050 Awake_IgnHigh 1;
BA_ "FlexKomComment" SG_ 1050 Awake_IgnHigh "Mode 15 of NM_Ud_Srv";
BA_ "GenSigSNA" SG_ 1050 Awake_NwSt "0h";
BA_ "GenSigSendType" SG_ 1050 Awake_NwSt 1;
BA_ "FlexKomSigStartValue" SG_ 1050 Awake_NwSt "000000h";
BA_ "FlexKomSigStartPos" SG_ 1050 Awake_NwSt 39;
BA_ "FlexKomSigName" SG_ 1050 Awake_NwSt "Awake_EPS";
BA_ "FlexKomSigLaenge" SG_ 1050 Awake_NwSt 24;
BA_ "FlexKomSID" SG_ 1050 Awake_NwSt 1274;
BA_ "FlexKomIsMotorola" SG_ 1050 Awake_NwSt 1;
BA_ "FlexKomComment" SG_ 1050 Awake_NwSt "Mode 15 of NM_Ud_Srv";
BA_ "GenSigSNA" SG_ 1050 Awake_Rampout "0h";
BA_ "GenSigSendType" SG_ 1050 Awake_Rampout 1;
BA_ "FlexKomSigStartValue" SG_ 1050 Awake_Rampout "000000h";
BA_ "FlexKomSigStartPos" SG_ 1050 Awake_Rampout 39;
BA_ "FlexKomSigName" SG_ 1050 Awake_Rampout "Awake_EPS";
BA_ "FlexKomSigLaenge" SG_ 1050 Awake_Rampout 24;
BA_ "FlexKomSID" SG_ 1050 Awake_Rampout 1274;
BA_ "FlexKomIsMotorola" SG_ 1050 Awake_Rampout 1;
BA_ "FlexKomComment" SG_ 1050 Awake_Rampout "Mode 15 of NM_Ud_Srv";
BA_ "GenSigSNA" SG_ 1050 Awake_VSS_high "0h";
BA_ "GenSigSendType" SG_ 1050 Awake_VSS_high 1;
BA_ "FlexKomSigStartValue" SG_ 1050 Awake_VSS_high "000000h";
BA_ "FlexKomSigStartPos" SG_ 1050 Awake_VSS_high 39;
BA_ "FlexKomSigName" SG_ 1050 Awake_VSS_high "Awake_EPS";
BA_ "FlexKomSigLaenge" SG_ 1050 Awake_VSS_high 24;
BA_ "FlexKomSID" SG_ 1050 Awake_VSS_high 1274;
BA_ "FlexKomIsMotorola" SG_ 1050 Awake_VSS_high 1;
BA_ "FlexKomComment" SG_ 1050 Awake_VSS_high "Mode 15 of NM_Ud_Srv";
BA_ "GenSigStartValue" SG_ 1050 NM_Mode 255;
BA_ "GenSigSNA" SG_ 1050 NM_Mode "FFh";
BA_ "GenSigSendType" SG_ 1050 NM_Mode 1;
BA_ "FlexKomSigStartValue" SG_ 1050 NM_Mode "FFFFFFFFh";
BA_ "FlexKomSigStartPos" SG_ 1050 NM_Mode 7;
BA_ "FlexKomSigName" SG_ 1050 NM_Mode "NM";
BA_ "FlexKomSigLaenge" SG_ 1050 NM_Mode 32;
BA_ "FlexKomSID" SG_ 1050 NM_Mode 472;
BA_ "FlexKomIsMotorola" SG_ 1050 NM_Mode 1;
BA_ "FlexKomComment" SG_ 1050 NM_Mode "Network management state";
BA_ "GenSigStartValue" SG_ 1050 NM_Sleep_Ack 1;
BA_ "GenSigSNA" SG_ 1050 NM_Sleep_Ack "1h";
BA_ "GenSigSendType" SG_ 1050 NM_Sleep_Ack 1;
BA_ "FlexKomSigStartValue" SG_ 1050 NM_Sleep_Ack "FFFFFFFFh";
BA_ "FlexKomSigStartPos" SG_ 1050 NM_Sleep_Ack 7;
BA_ "FlexKomSigName" SG_ 1050 NM_Sleep_Ack "NM";
BA_ "FlexKomSigLaenge" SG_ 1050 NM_Sleep_Ack 32;
BA_ "FlexKomSID" SG_ 1050 NM_Sleep_Ack 472;
BA_ "FlexKomIsMotorola" SG_ 1050 NM_Sleep_Ack 1;
BA_ "FlexKomComment" SG_ 1050 NM_Sleep_Ack "Network management state";
BA_ "GenSigStartValue" SG_ 1050 NM_Sleep_Ind 1;
BA_ "GenSigSNA" SG_ 1050 NM_Sleep_Ind "1h";
BA_ "GenSigSendType" SG_ 1050 NM_Sleep_Ind 1;
BA_ "FlexKomSigStartValue" SG_ 1050 NM_Sleep_Ind "FFFFFFFFh";
BA_ "FlexKomSigStartPos" SG_ 1050 NM_Sleep_Ind 7;
BA_ "FlexKomSigName" SG_ 1050 NM_Sleep_Ind "NM";
BA_ "FlexKomSigLaenge" SG_ 1050 NM_Sleep_Ind 32;
BA_ "FlexKomSID" SG_ 1050 NM_Sleep_Ind 472;
BA_ "FlexKomIsMotorola" SG_ 1050 NM_Sleep_Ind 1;
BA_ "FlexKomComment" SG_ 1050 NM_Sleep_Ind "Network management state";
BA_ "GenSigStartValue" SG_ 1050 NM_Successor 255;
BA_ "GenSigSNA" SG_ 1050 NM_Successor "FFh";
BA_ "GenSigSendType" SG_ 1050 NM_Successor 1;
BA_ "FlexKomSigStartValue" SG_ 1050 NM_Successor "FFFFFFFFh";
BA_ "FlexKomSigStartPos" SG_ 1050 NM_Successor 7;
BA_ "FlexKomSigName" SG_ 1050 NM_Successor "NM";
BA_ "FlexKomSigLaenge" SG_ 1050 NM_Successor 32;
BA_ "FlexKomSID" SG_ 1050 NM_Successor 472;
BA_ "FlexKomIsMotorola" SG_ 1050 NM_Successor 1;
BA_ "FlexKomComment" SG_ 1050 NM_Successor "Network management state";
BA_ "GenSigStartValue" SG_ 1050 NM_Ud_Launch 63;
BA_ "GenSigSNA" SG_ 1050 NM_Ud_Launch "3Fh";
BA_ "GenSigSendType" SG_ 1050 NM_Ud_Launch 1;
BA_ "FlexKomSigStartValue" SG_ 1050 NM_Ud_Launch "FFFFFFFFh";
BA_ "FlexKomSigStartPos" SG_ 1050 NM_Ud_Launch 7;
BA_ "FlexKomSigName" SG_ 1050 NM_Ud_Launch "NM";
BA_ "FlexKomSigLaenge" SG_ 1050 NM_Ud_Launch 32;
BA_ "FlexKomSID" SG_ 1050 NM_Ud_Launch 472;
BA_ "FlexKomIsMotorola" SG_ 1050 NM_Ud_Launch 1;
BA_ "FlexKomComment" SG_ 1050 NM_Ud_Launch "Network management state";
BA_ "GenSigStartValue" SG_ 1050 NM_Ud_Srv 255;
BA_ "GenSigSNA" SG_ 1050 NM_Ud_Srv "FFh";
BA_ "GenSigSendType" SG_ 1050 NM_Ud_Srv 1;
BA_ "FlexKomSigStartValue" SG_ 1050 NM_Ud_Srv "FFFFFFFFh";
BA_ "FlexKomSigStartPos" SG_ 1050 NM_Ud_Srv 7;
BA_ "FlexKomSigName" SG_ 1050 NM_Ud_Srv "NM";
BA_ "FlexKomSigLaenge" SG_ 1050 NM_Ud_Srv 32;
BA_ "FlexKomSID" SG_ 1050 NM_Ud_Srv 472;
BA_ "FlexKomIsMotorola" SG_ 1050 NM_Ud_Srv 1;
BA_ "FlexKomComment" SG_ 1050 NM_Ud_Srv "Network management state";
BA_ "GenSigStartValue" SG_ 1050 Nw_Id 255;
BA_ "GenSigSNA" SG_ 1050 Nw_Id "FFh";
BA_ "GenSigSendType" SG_ 1050 Nw_Id 1;
BA_ "FlexKomSigStartValue" SG_ 1050 Nw_Id "FFh";
BA_ "FlexKomSigStartPos" SG_ 1050 Nw_Id 63;
BA_ "FlexKomSigName" SG_ 1050 Nw_Id "Nw_Id";
BA_ "FlexKomSigLaenge" SG_ 1050 Nw_Id 8;
BA_ "FlexKomSID" SG_ 1050 Nw_Id 535;
BA_ "FlexKomIsMotorola" SG_ 1050 Nw_Id 1;
BA_ "FlexKomComment" SG_ 1050 Nw_Id "Network identification no.";
BA_ "GenSigStartValue" SG_ 1050 WakeupCnt 255;
BA_ "GenSigSNA" SG_ 1050 WakeupCnt "FFh";
BA_ "GenSigSendType" SG_ 1050 WakeupCnt 1;
BA_ "FlexKomSigStartValue" SG_ 1050 WakeupCnt "FFFF00h";
BA_ "FlexKomSigStartPos" SG_ 1050 WakeupCnt 39;
BA_ "FlexKomSigName" SG_ 1050 WakeupCnt "Wakeup_EPS";
BA_ "FlexKomSigLaenge" SG_ 1050 WakeupCnt 24;
BA_ "FlexKomSID" SG_ 1050 WakeupCnt 1273;
BA_ "FlexKomIsMotorola" SG_ 1050 WakeupCnt 1;
BA_ "FlexKomComment" SG_ 1050 WakeupCnt "Mode 2 of NM_Ud_Srv";
BA_ "GenSigStartValue" SG_ 1050 WakeupRsn_EPS 255;
BA_ "GenSigSNA" SG_ 1050 WakeupRsn_EPS "FFh";
BA_ "GenSigSendType" SG_ 1050 WakeupRsn_EPS 1;
BA_ "FlexKomSigStartValue" SG_ 1050 WakeupRsn_EPS "FFFF00h";
BA_ "FlexKomSigStartPos" SG_ 1050 WakeupRsn_EPS 39;
BA_ "FlexKomSigName" SG_ 1050 WakeupRsn_EPS "Wakeup_EPS";
BA_ "FlexKomSigLaenge" SG_ 1050 WakeupRsn_EPS 24;
BA_ "FlexKomSID" SG_ 1050 WakeupRsn_EPS 1273;
BA_ "FlexKomIsMotorola" SG_ 1050 WakeupRsn_EPS 1;
BA_ "FlexKomComment" SG_ 1050 WakeupRsn_EPS "Mode 2 of NM_Ud_Srv";
BA_ "GenSigSNA" SG_ 1031 Awake_Brake_Pedal_Pressed "0h";
BA_ "GenSigSendType" SG_ 1031 Awake_Brake_Pedal_Pressed 1;
BA_ "FlexKomSigStartValue" SG_ 1031 Awake_Brake_Pedal_Pressed "000000h";
BA_ "FlexKomSigStartPos" SG_ 1031 Awake_Brake_Pedal_Pressed 39;
BA_ "FlexKomSigName" SG_ 1031 Awake_Brake_Pedal_Pressed "Awake_ESC";
BA_ "FlexKomSigLaenge" SG_ 1031 Awake_Brake_Pedal_Pressed 24;
BA_ "FlexKomSID" SG_ 1031 Awake_Brake_Pedal_Pressed 961;
BA_ "FlexKomIsMotorola" SG_ 1031 Awake_Brake_Pedal_Pressed 1;
BA_ "FlexKomComment" SG_ 1031 Awake_Brake_Pedal_Pressed "Mode 15 of NM_Ud_Srv";
BA_ "GenSigSNA" SG_ 1031 Awake_Diag_Actv "0h";
BA_ "GenSigSendType" SG_ 1031 Awake_Diag_Actv 1;
BA_ "FlexKomSigStartValue" SG_ 1031 Awake_Diag_Actv "000000h";
BA_ "FlexKomSigStartPos" SG_ 1031 Awake_Diag_Actv 39;
BA_ "FlexKomSigName" SG_ 1031 Awake_Diag_Actv "Awake_ESC";
BA_ "FlexKomSigLaenge" SG_ 1031 Awake_Diag_Actv 24;
BA_ "FlexKomSID" SG_ 1031 Awake_Diag_Actv 961;
BA_ "FlexKomIsMotorola" SG_ 1031 Awake_Diag_Actv 1;
BA_ "FlexKomComment" SG_ 1031 Awake_Diag_Actv "Mode 15 of NM_Ud_Srv";
BA_ "GenSigSNA" SG_ 1031 Awake_EPB_Switch_Wakeup "0h";
BA_ "GenSigSendType" SG_ 1031 Awake_EPB_Switch_Wakeup 1;
BA_ "FlexKomSigStartValue" SG_ 1031 Awake_EPB_Switch_Wakeup "000000h";
BA_ "FlexKomSigStartPos" SG_ 1031 Awake_EPB_Switch_Wakeup 39;
BA_ "FlexKomSigName" SG_ 1031 Awake_EPB_Switch_Wakeup "Awake_ESC";
BA_ "FlexKomSigLaenge" SG_ 1031 Awake_EPB_Switch_Wakeup 24;
BA_ "FlexKomSID" SG_ 1031 Awake_EPB_Switch_Wakeup 961;
BA_ "FlexKomIsMotorola" SG_ 1031 Awake_EPB_Switch_Wakeup 1;
BA_ "FlexKomComment" SG_ 1031 Awake_EPB_Switch_Wakeup "Mode 15 of NM_Ud_Srv";
BA_ "GenSigSNA" SG_ 1031 Awake_Hardwire_Ignition "0h";
BA_ "GenSigSendType" SG_ 1031 Awake_Hardwire_Ignition 1;
BA_ "FlexKomSigStartValue" SG_ 1031 Awake_Hardwire_Ignition "000000h";
BA_ "FlexKomSigStartPos" SG_ 1031 Awake_Hardwire_Ignition 39;
BA_ "FlexKomSigName" SG_ 1031 Awake_Hardwire_Ignition "Awake_ESC";
BA_ "FlexKomSigLaenge" SG_ 1031 Awake_Hardwire_Ignition 24;
BA_ "FlexKomSID" SG_ 1031 Awake_Hardwire_Ignition 961;
BA_ "FlexKomIsMotorola" SG_ 1031 Awake_Hardwire_Ignition 1;
BA_ "FlexKomComment" SG_ 1031 Awake_Hardwire_Ignition "Mode 15 of NM_Ud_Srv";
BA_ "GenSigSNA" SG_ 1031 Awake_NwSt "0h";
BA_ "GenSigSendType" SG_ 1031 Awake_NwSt 1;
BA_ "FlexKomSigStartValue" SG_ 1031 Awake_NwSt "000000h";
BA_ "FlexKomSigStartPos" SG_ 1031 Awake_NwSt 39;
BA_ "FlexKomSigName" SG_ 1031 Awake_NwSt "Awake_ESC";
BA_ "FlexKomSigLaenge" SG_ 1031 Awake_NwSt 24;
BA_ "FlexKomSID" SG_ 1031 Awake_NwSt 961;
BA_ "FlexKomIsMotorola" SG_ 1031 Awake_NwSt 1;
BA_ "FlexKomComment" SG_ 1031 Awake_NwSt "Mode 15 of NM_Ud_Srv";
BA_ "GenSigSNA" SG_ 1031 Awake_Vehicle_Speed "0h";
BA_ "GenSigSendType" SG_ 1031 Awake_Vehicle_Speed 1;
BA_ "FlexKomSigStartValue" SG_ 1031 Awake_Vehicle_Speed "000000h";
BA_ "FlexKomSigStartPos" SG_ 1031 Awake_Vehicle_Speed 39;
BA_ "FlexKomSigName" SG_ 1031 Awake_Vehicle_Speed "Awake_ESC";
BA_ "FlexKomSigLaenge" SG_ 1031 Awake_Vehicle_Speed 24;
BA_ "FlexKomSID" SG_ 1031 Awake_Vehicle_Speed 961;
BA_ "FlexKomIsMotorola" SG_ 1031 Awake_Vehicle_Speed 1;
BA_ "FlexKomComment" SG_ 1031 Awake_Vehicle_Speed "Mode 15 of NM_Ud_Srv";
BA_ "GenSigStartValue" SG_ 1031 NM_Mode 255;
BA_ "GenSigSNA" SG_ 1031 NM_Mode "FFh";
BA_ "GenSigSendType" SG_ 1031 NM_Mode 1;
BA_ "FlexKomSigStartValue" SG_ 1031 NM_Mode "FFFFFFFFh";
BA_ "FlexKomSigStartPos" SG_ 1031 NM_Mode 7;
BA_ "FlexKomSigName" SG_ 1031 NM_Mode "NM";
BA_ "FlexKomSigLaenge" SG_ 1031 NM_Mode 32;
BA_ "FlexKomSID" SG_ 1031 NM_Mode 472;
BA_ "FlexKomIsMotorola" SG_ 1031 NM_Mode 1;
BA_ "FlexKomComment" SG_ 1031 NM_Mode "Network management state";
BA_ "GenSigStartValue" SG_ 1031 NM_Sleep_Ack 1;
BA_ "GenSigSNA" SG_ 1031 NM_Sleep_Ack "1h";
BA_ "GenSigSendType" SG_ 1031 NM_Sleep_Ack 1;
BA_ "FlexKomSigStartValue" SG_ 1031 NM_Sleep_Ack "FFFFFFFFh";
BA_ "FlexKomSigStartPos" SG_ 1031 NM_Sleep_Ack 7;
BA_ "FlexKomSigName" SG_ 1031 NM_Sleep_Ack "NM";
BA_ "FlexKomSigLaenge" SG_ 1031 NM_Sleep_Ack 32;
BA_ "FlexKomSID" SG_ 1031 NM_Sleep_Ack 472;
BA_ "FlexKomIsMotorola" SG_ 1031 NM_Sleep_Ack 1;
BA_ "FlexKomComment" SG_ 1031 NM_Sleep_Ack "Network management state";
BA_ "GenSigStartValue" SG_ 1031 NM_Sleep_Ind 1;
BA_ "GenSigSNA" SG_ 1031 NM_Sleep_Ind "1h";
BA_ "GenSigSendType" SG_ 1031 NM_Sleep_Ind 1;
BA_ "FlexKomSigStartValue" SG_ 1031 NM_Sleep_Ind "FFFFFFFFh";
BA_ "FlexKomSigStartPos" SG_ 1031 NM_Sleep_Ind 7;
BA_ "FlexKomSigName" SG_ 1031 NM_Sleep_Ind "NM";
BA_ "FlexKomSigLaenge" SG_ 1031 NM_Sleep_Ind 32;
BA_ "FlexKomSID" SG_ 1031 NM_Sleep_Ind 472;
BA_ "FlexKomIsMotorola" SG_ 1031 NM_Sleep_Ind 1;
BA_ "FlexKomComment" SG_ 1031 NM_Sleep_Ind "Network management state";
BA_ "GenSigStartValue" SG_ 1031 NM_Successor 255;
BA_ "GenSigSNA" SG_ 1031 NM_Successor "FFh";
BA_ "GenSigSendType" SG_ 1031 NM_Successor 1;
BA_ "FlexKomSigStartValue" SG_ 1031 NM_Successor "FFFFFFFFh";
BA_ "FlexKomSigStartPos" SG_ 1031 NM_Successor 7;
BA_ "FlexKomSigName" SG_ 1031 NM_Successor "NM";
BA_ "FlexKomSigLaenge" SG_ 1031 NM_Successor 32;
BA_ "FlexKomSID" SG_ 1031 NM_Successor 472;
BA_ "FlexKomIsMotorola" SG_ 1031 NM_Successor 1;
BA_ "FlexKomComment" SG_ 1031 NM_Successor "Network management state";
BA_ "GenSigStartValue" SG_ 1031 NM_Ud_Launch 63;
BA_ "GenSigSNA" SG_ 1031 NM_Ud_Launch "3Fh";
BA_ "GenSigSendType" SG_ 1031 NM_Ud_Launch 1;
BA_ "FlexKomSigStartValue" SG_ 1031 NM_Ud_Launch "FFFFFFFFh";
BA_ "FlexKomSigStartPos" SG_ 1031 NM_Ud_Launch 7;
BA_ "FlexKomSigName" SG_ 1031 NM_Ud_Launch "NM";
BA_ "FlexKomSigLaenge" SG_ 1031 NM_Ud_Launch 32;
BA_ "FlexKomSID" SG_ 1031 NM_Ud_Launch 472;
BA_ "FlexKomIsMotorola" SG_ 1031 NM_Ud_Launch 1;
BA_ "FlexKomComment" SG_ 1031 NM_Ud_Launch "Network management state";
BA_ "GenSigStartValue" SG_ 1031 NM_Ud_Srv 255;
BA_ "GenSigSNA" SG_ 1031 NM_Ud_Srv "FFh";
BA_ "GenSigSendType" SG_ 1031 NM_Ud_Srv 1;
BA_ "FlexKomSigStartValue" SG_ 1031 NM_Ud_Srv "FFFFFFFFh";
BA_ "FlexKomSigStartPos" SG_ 1031 NM_Ud_Srv 7;
BA_ "FlexKomSigName" SG_ 1031 NM_Ud_Srv "NM";
BA_ "FlexKomSigLaenge" SG_ 1031 NM_Ud_Srv 32;
BA_ "FlexKomSID" SG_ 1031 NM_Ud_Srv 472;
BA_ "FlexKomIsMotorola" SG_ 1031 NM_Ud_Srv 1;
BA_ "FlexKomComment" SG_ 1031 NM_Ud_Srv "Network management state";
BA_ "GenSigStartValue" SG_ 1031 Nw_Id 255;
BA_ "GenSigSNA" SG_ 1031 Nw_Id "FFh";
BA_ "GenSigSendType" SG_ 1031 Nw_Id 1;
BA_ "FlexKomSigStartValue" SG_ 1031 Nw_Id "FFh";
BA_ "FlexKomSigStartPos" SG_ 1031 Nw_Id 63;
BA_ "FlexKomSigName" SG_ 1031 Nw_Id "Nw_Id";
BA_ "FlexKomSigLaenge" SG_ 1031 Nw_Id 8;
BA_ "FlexKomSID" SG_ 1031 Nw_Id 535;
BA_ "FlexKomIsMotorola" SG_ 1031 Nw_Id 1;
BA_ "FlexKomComment" SG_ 1031 Nw_Id "Network identification no.";
BA_ "GenSigStartValue" SG_ 1031 WakeupCnt 255;
BA_ "GenSigSNA" SG_ 1031 WakeupCnt "FFh";
BA_ "GenSigSendType" SG_ 1031 WakeupCnt 1;
BA_ "FlexKomSigStartValue" SG_ 1031 WakeupCnt "FFFF00h";
BA_ "FlexKomSigStartPos" SG_ 1031 WakeupCnt 39;
BA_ "FlexKomSigName" SG_ 1031 WakeupCnt "Wakeup_ESC";
BA_ "FlexKomSigLaenge" SG_ 1031 WakeupCnt 24;
BA_ "FlexKomSID" SG_ 1031 WakeupCnt 962;
BA_ "FlexKomIsMotorola" SG_ 1031 WakeupCnt 1;
BA_ "FlexKomComment" SG_ 1031 WakeupCnt "Mode 2 of NM_Ud_Srv";
BA_ "GenSigStartValue" SG_ 1031 WakeupRsn_ESC 255;
BA_ "GenSigSNA" SG_ 1031 WakeupRsn_ESC "FFh";
BA_ "GenSigSendType" SG_ 1031 WakeupRsn_ESC 1;
BA_ "FlexKomSigStartValue" SG_ 1031 WakeupRsn_ESC "FFFF00h";
BA_ "FlexKomSigStartPos" SG_ 1031 WakeupRsn_ESC 39;
BA_ "FlexKomSigName" SG_ 1031 WakeupRsn_ESC "Wakeup_ESC";
BA_ "FlexKomSigLaenge" SG_ 1031 WakeupRsn_ESC 24;
BA_ "FlexKomSID" SG_ 1031 WakeupRsn_ESC 962;
BA_ "FlexKomIsMotorola" SG_ 1031 WakeupRsn_ESC 1;
BA_ "FlexKomComment" SG_ 1031 WakeupRsn_ESC "Mode 2 of NM_Ud_Srv";
BA_ "GenSigSNA" SG_ 1032 Awake_Diag_Actv "0h";
BA_ "GenSigSendType" SG_ 1032 Awake_Diag_Actv 1;
BA_ "FlexKomSigStartValue" SG_ 1032 Awake_Diag_Actv "000000h";
BA_ "FlexKomSigStartPos" SG_ 1032 Awake_Diag_Actv 39;
BA_ "FlexKomSigName" SG_ 1032 Awake_Diag_Actv "Awake_ESL";
BA_ "FlexKomSigLaenge" SG_ 1032 Awake_Diag_Actv 24;
BA_ "FlexKomSID" SG_ 1032 Awake_Diag_Actv 2343;
BA_ "FlexKomIsMotorola" SG_ 1032 Awake_Diag_Actv 1;
BA_ "FlexKomComment" SG_ 1032 Awake_Diag_Actv "Mode 15 of NM_Ud_Srv";
BA_ "GenSigSNA" SG_ 1032 Awake_Ign_RunStart "0h";
BA_ "GenSigSendType" SG_ 1032 Awake_Ign_RunStart 1;
BA_ "FlexKomSigStartValue" SG_ 1032 Awake_Ign_RunStart "000000h";
BA_ "FlexKomSigStartPos" SG_ 1032 Awake_Ign_RunStart 39;
BA_ "FlexKomSigName" SG_ 1032 Awake_Ign_RunStart "Awake_ESL";
BA_ "FlexKomSigLaenge" SG_ 1032 Awake_Ign_RunStart 24;
BA_ "FlexKomSID" SG_ 1032 Awake_Ign_RunStart 2343;
BA_ "FlexKomIsMotorola" SG_ 1032 Awake_Ign_RunStart 1;
BA_ "FlexKomComment" SG_ 1032 Awake_Ign_RunStart "Mode 15 of NM_Ud_Srv";
BA_ "GenSigSNA" SG_ 1032 Awake_Lock_Unlock "0h";
BA_ "GenSigSendType" SG_ 1032 Awake_Lock_Unlock 1;
BA_ "FlexKomSigStartValue" SG_ 1032 Awake_Lock_Unlock "000000h";
BA_ "FlexKomSigStartPos" SG_ 1032 Awake_Lock_Unlock 39;
BA_ "FlexKomSigName" SG_ 1032 Awake_Lock_Unlock "Awake_ESL";
BA_ "FlexKomSigLaenge" SG_ 1032 Awake_Lock_Unlock 24;
BA_ "FlexKomSID" SG_ 1032 Awake_Lock_Unlock 2343;
BA_ "FlexKomIsMotorola" SG_ 1032 Awake_Lock_Unlock 1;
BA_ "FlexKomComment" SG_ 1032 Awake_Lock_Unlock "Mode 15 of NM_Ud_Srv";
BA_ "GenSigSNA" SG_ 1032 Awake_NwSt "0h";
BA_ "GenSigSendType" SG_ 1032 Awake_NwSt 1;
BA_ "FlexKomSigStartValue" SG_ 1032 Awake_NwSt "000000h";
BA_ "FlexKomSigStartPos" SG_ 1032 Awake_NwSt 39;
BA_ "FlexKomSigName" SG_ 1032 Awake_NwSt "Awake_ESL";
BA_ "FlexKomSigLaenge" SG_ 1032 Awake_NwSt 24;
BA_ "FlexKomSID" SG_ 1032 Awake_NwSt 2343;
BA_ "FlexKomIsMotorola" SG_ 1032 Awake_NwSt 1;
BA_ "FlexKomComment" SG_ 1032 Awake_NwSt "Mode 15 of NM_Ud_Srv";
BA_ "GenSigStartValue" SG_ 1032 NM_Mode 255;
BA_ "GenSigSNA" SG_ 1032 NM_Mode "FFh";
BA_ "GenSigSendType" SG_ 1032 NM_Mode 1;
BA_ "FlexKomSigStartValue" SG_ 1032 NM_Mode "FFFFFFFFh";
BA_ "FlexKomSigStartPos" SG_ 1032 NM_Mode 7;
BA_ "FlexKomSigName" SG_ 1032 NM_Mode "NM";
BA_ "FlexKomSigLaenge" SG_ 1032 NM_Mode 32;
BA_ "FlexKomSID" SG_ 1032 NM_Mode 472;
BA_ "FlexKomIsMotorola" SG_ 1032 NM_Mode 1;
BA_ "FlexKomComment" SG_ 1032 NM_Mode "Network management state";
BA_ "GenSigStartValue" SG_ 1032 NM_Sleep_Ack 1;
BA_ "GenSigSNA" SG_ 1032 NM_Sleep_Ack "1h";
BA_ "GenSigSendType" SG_ 1032 NM_Sleep_Ack 1;
BA_ "FlexKomSigStartValue" SG_ 1032 NM_Sleep_Ack "FFFFFFFFh";
BA_ "FlexKomSigStartPos" SG_ 1032 NM_Sleep_Ack 7;
BA_ "FlexKomSigName" SG_ 1032 NM_Sleep_Ack "NM";
BA_ "FlexKomSigLaenge" SG_ 1032 NM_Sleep_Ack 32;
BA_ "FlexKomSID" SG_ 1032 NM_Sleep_Ack 472;
BA_ "FlexKomIsMotorola" SG_ 1032 NM_Sleep_Ack 1;
BA_ "FlexKomComment" SG_ 1032 NM_Sleep_Ack "Network management state";
BA_ "GenSigStartValue" SG_ 1032 NM_Sleep_Ind 1;
BA_ "GenSigSNA" SG_ 1032 NM_Sleep_Ind "1h";
BA_ "GenSigSendType" SG_ 1032 NM_Sleep_Ind 1;
BA_ "FlexKomSigStartValue" SG_ 1032 NM_Sleep_Ind "FFFFFFFFh";
BA_ "FlexKomSigStartPos" SG_ 1032 NM_Sleep_Ind 7;
BA_ "FlexKomSigName" SG_ 1032 NM_Sleep_Ind "NM";
BA_ "FlexKomSigLaenge" SG_ 1032 NM_Sleep_Ind 32;
BA_ "FlexKomSID" SG_ 1032 NM_Sleep_Ind 472;
BA_ "FlexKomIsMotorola" SG_ 1032 NM_Sleep_Ind 1;
BA_ "FlexKomComment" SG_ 1032 NM_Sleep_Ind "Network management state";
BA_ "GenSigStartValue" SG_ 1032 NM_Successor 255;
BA_ "GenSigSNA" SG_ 1032 NM_Successor "FFh";
BA_ "GenSigSendType" SG_ 1032 NM_Successor 1;
BA_ "FlexKomSigStartValue" SG_ 1032 NM_Successor "FFFFFFFFh";
BA_ "FlexKomSigStartPos" SG_ 1032 NM_Successor 7;
BA_ "FlexKomSigName" SG_ 1032 NM_Successor "NM";
BA_ "FlexKomSigLaenge" SG_ 1032 NM_Successor 32;
BA_ "FlexKomSID" SG_ 1032 NM_Successor 472;
BA_ "FlexKomIsMotorola" SG_ 1032 NM_Successor 1;
BA_ "FlexKomComment" SG_ 1032 NM_Successor "Network management state";
BA_ "GenSigStartValue" SG_ 1032 NM_Ud_Launch 63;
BA_ "GenSigSNA" SG_ 1032 NM_Ud_Launch "3Fh";
BA_ "GenSigSendType" SG_ 1032 NM_Ud_Launch 1;
BA_ "FlexKomSigStartValue" SG_ 1032 NM_Ud_Launch "FFFFFFFFh";
BA_ "FlexKomSigStartPos" SG_ 1032 NM_Ud_Launch 7;
BA_ "FlexKomSigName" SG_ 1032 NM_Ud_Launch "NM";
BA_ "FlexKomSigLaenge" SG_ 1032 NM_Ud_Launch 32;
BA_ "FlexKomSID" SG_ 1032 NM_Ud_Launch 472;
BA_ "FlexKomIsMotorola" SG_ 1032 NM_Ud_Launch 1;
BA_ "FlexKomComment" SG_ 1032 NM_Ud_Launch "Network management state";
BA_ "GenSigStartValue" SG_ 1032 NM_Ud_Srv 255;
BA_ "GenSigSNA" SG_ 1032 NM_Ud_Srv "FFh";
BA_ "GenSigSendType" SG_ 1032 NM_Ud_Srv 1;
BA_ "FlexKomSigStartValue" SG_ 1032 NM_Ud_Srv "FFFFFFFFh";
BA_ "FlexKomSigStartPos" SG_ 1032 NM_Ud_Srv 7;
BA_ "FlexKomSigName" SG_ 1032 NM_Ud_Srv "NM";
BA_ "FlexKomSigLaenge" SG_ 1032 NM_Ud_Srv 32;
BA_ "FlexKomSID" SG_ 1032 NM_Ud_Srv 472;
BA_ "FlexKomIsMotorola" SG_ 1032 NM_Ud_Srv 1;
BA_ "FlexKomComment" SG_ 1032 NM_Ud_Srv "Network management state";
BA_ "GenSigStartValue" SG_ 1032 Nw_Id 255;
BA_ "GenSigSNA" SG_ 1032 Nw_Id "FFh";
BA_ "GenSigSendType" SG_ 1032 Nw_Id 1;
BA_ "FlexKomSigStartValue" SG_ 1032 Nw_Id "FFh";
BA_ "FlexKomSigStartPos" SG_ 1032 Nw_Id 63;
BA_ "FlexKomSigName" SG_ 1032 Nw_Id "Nw_Id";
BA_ "FlexKomSigLaenge" SG_ 1032 Nw_Id 8;
BA_ "FlexKomSID" SG_ 1032 Nw_Id 535;
BA_ "FlexKomIsMotorola" SG_ 1032 Nw_Id 1;
BA_ "FlexKomComment" SG_ 1032 Nw_Id "Network identification no.";
BA_ "GenSigStartValue" SG_ 1032 WakeupCnt 255;
BA_ "GenSigSNA" SG_ 1032 WakeupCnt "FFh";
BA_ "GenSigSendType" SG_ 1032 WakeupCnt 1;
BA_ "FlexKomSigStartValue" SG_ 1032 WakeupCnt "FFFF00h";
BA_ "FlexKomSigStartPos" SG_ 1032 WakeupCnt 39;
BA_ "FlexKomSigName" SG_ 1032 WakeupCnt "Wakeup_ESL";
BA_ "FlexKomSigLaenge" SG_ 1032 WakeupCnt 24;
BA_ "FlexKomSID" SG_ 1032 WakeupCnt 2344;
BA_ "FlexKomIsMotorola" SG_ 1032 WakeupCnt 1;
BA_ "FlexKomComment" SG_ 1032 WakeupCnt "Mode 2 of NM_Ud_Srv";
BA_ "GenSigStartValue" SG_ 1032 WakeupRsn_ESL 255;
BA_ "GenSigSNA" SG_ 1032 WakeupRsn_ESL "FFh";
BA_ "GenSigSendType" SG_ 1032 WakeupRsn_ESL 1;
BA_ "FlexKomSigStartValue" SG_ 1032 WakeupRsn_ESL "FFFF00h";
BA_ "FlexKomSigStartPos" SG_ 1032 WakeupRsn_ESL 39;
BA_ "FlexKomSigName" SG_ 1032 WakeupRsn_ESL "Wakeup_ESL";
BA_ "FlexKomSigLaenge" SG_ 1032 WakeupRsn_ESL 24;
BA_ "FlexKomSID" SG_ 1032 WakeupRsn_ESL 2344;
BA_ "FlexKomIsMotorola" SG_ 1032 WakeupRsn_ESL 1;
BA_ "FlexKomComment" SG_ 1032 WakeupRsn_ESL "Mode 2 of NM_Ud_Srv";
BA_ "GenSigSNA" SG_ 1082 Awake_Chg_ST "0h";
BA_ "GenSigSendType" SG_ 1082 Awake_Chg_ST 1;
BA_ "FlexKomSigStartValue" SG_ 1082 Awake_Chg_ST "000000h";
BA_ "FlexKomSigStartPos" SG_ 1082 Awake_Chg_ST 39;
BA_ "FlexKomSigName" SG_ 1082 Awake_Chg_ST "Awake_HCP";
BA_ "FlexKomSigLaenge" SG_ 1082 Awake_Chg_ST 24;
BA_ "FlexKomSID" SG_ 1082 Awake_Chg_ST 2122;
BA_ "FlexKomIsMotorola" SG_ 1082 Awake_Chg_ST 1;
BA_ "FlexKomComment" SG_ 1082 Awake_Chg_ST "Mode 15 of NM_Ud_Srv";
BA_ "GenSigSNA" SG_ 1082 Awake_Diag_Actv "0h";
BA_ "GenSigSendType" SG_ 1082 Awake_Diag_Actv 1;
BA_ "FlexKomSigStartValue" SG_ 1082 Awake_Diag_Actv "000000h";
BA_ "FlexKomSigStartPos" SG_ 1082 Awake_Diag_Actv 39;
BA_ "FlexKomSigName" SG_ 1082 Awake_Diag_Actv "Awake_HCP";
BA_ "FlexKomSigLaenge" SG_ 1082 Awake_Diag_Actv 24;
BA_ "FlexKomSID" SG_ 1082 Awake_Diag_Actv 2122;
BA_ "FlexKomIsMotorola" SG_ 1082 Awake_Diag_Actv 1;
BA_ "FlexKomComment" SG_ 1082 Awake_Diag_Actv "Mode 15 of NM_Ud_Srv";
BA_ "GenSigSNA" SG_ 1082 Awake_NwSt "0h";
BA_ "GenSigSendType" SG_ 1082 Awake_NwSt 1;
BA_ "FlexKomSigStartValue" SG_ 1082 Awake_NwSt "000000h";
BA_ "FlexKomSigStartPos" SG_ 1082 Awake_NwSt 39;
BA_ "FlexKomSigName" SG_ 1082 Awake_NwSt "Awake_HCP";
BA_ "FlexKomSigLaenge" SG_ 1082 Awake_NwSt 24;
BA_ "FlexKomSID" SG_ 1082 Awake_NwSt 2122;
BA_ "FlexKomIsMotorola" SG_ 1082 Awake_NwSt 1;
BA_ "FlexKomComment" SG_ 1082 Awake_NwSt "Mode 15 of NM_Ud_Srv";
BA_ "GenSigSNA" SG_ 1082 Awake_OBCM_WU "0h";
BA_ "GenSigSendType" SG_ 1082 Awake_OBCM_WU 1;
BA_ "FlexKomSigStartValue" SG_ 1082 Awake_OBCM_WU "000000h";
BA_ "FlexKomSigStartPos" SG_ 1082 Awake_OBCM_WU 39;
BA_ "FlexKomSigName" SG_ 1082 Awake_OBCM_WU "Awake_HCP";
BA_ "FlexKomSigLaenge" SG_ 1082 Awake_OBCM_WU 24;
BA_ "FlexKomSID" SG_ 1082 Awake_OBCM_WU 2122;
BA_ "FlexKomIsMotorola" SG_ 1082 Awake_OBCM_WU 1;
BA_ "FlexKomComment" SG_ 1082 Awake_OBCM_WU "Mode 15 of NM_Ud_Srv";
BA_ "GenSigStartValue" SG_ 1082 NM_Mode 255;
BA_ "GenSigSNA" SG_ 1082 NM_Mode "FFh";
BA_ "GenSigSendType" SG_ 1082 NM_Mode 1;
BA_ "FlexKomSigStartValue" SG_ 1082 NM_Mode "FFFFFFFFh";
BA_ "FlexKomSigStartPos" SG_ 1082 NM_Mode 7;
BA_ "FlexKomSigName" SG_ 1082 NM_Mode "NM";
BA_ "FlexKomSigLaenge" SG_ 1082 NM_Mode 32;
BA_ "FlexKomSID" SG_ 1082 NM_Mode 472;
BA_ "FlexKomIsMotorola" SG_ 1082 NM_Mode 1;
BA_ "FlexKomComment" SG_ 1082 NM_Mode "Network management state";
BA_ "GenSigStartValue" SG_ 1082 NM_Sleep_Ack 1;
BA_ "GenSigSNA" SG_ 1082 NM_Sleep_Ack "1h";
BA_ "GenSigSendType" SG_ 1082 NM_Sleep_Ack 1;
BA_ "FlexKomSigStartValue" SG_ 1082 NM_Sleep_Ack "FFFFFFFFh";
BA_ "FlexKomSigStartPos" SG_ 1082 NM_Sleep_Ack 7;
BA_ "FlexKomSigName" SG_ 1082 NM_Sleep_Ack "NM";
BA_ "FlexKomSigLaenge" SG_ 1082 NM_Sleep_Ack 32;
BA_ "FlexKomSID" SG_ 1082 NM_Sleep_Ack 472;
BA_ "FlexKomIsMotorola" SG_ 1082 NM_Sleep_Ack 1;
BA_ "FlexKomComment" SG_ 1082 NM_Sleep_Ack "Network management state";
BA_ "GenSigStartValue" SG_ 1082 NM_Sleep_Ind 1;
BA_ "GenSigSNA" SG_ 1082 NM_Sleep_Ind "1h";
BA_ "GenSigSendType" SG_ 1082 NM_Sleep_Ind 1;
BA_ "FlexKomSigStartValue" SG_ 1082 NM_Sleep_Ind "FFFFFFFFh";
BA_ "FlexKomSigStartPos" SG_ 1082 NM_Sleep_Ind 7;
BA_ "FlexKomSigName" SG_ 1082 NM_Sleep_Ind "NM";
BA_ "FlexKomSigLaenge" SG_ 1082 NM_Sleep_Ind 32;
BA_ "FlexKomSID" SG_ 1082 NM_Sleep_Ind 472;
BA_ "FlexKomIsMotorola" SG_ 1082 NM_Sleep_Ind 1;
BA_ "FlexKomComment" SG_ 1082 NM_Sleep_Ind "Network management state";
BA_ "GenSigStartValue" SG_ 1082 NM_Successor 255;
BA_ "GenSigSNA" SG_ 1082 NM_Successor "FFh";
BA_ "GenSigSendType" SG_ 1082 NM_Successor 1;
BA_ "FlexKomSigStartValue" SG_ 1082 NM_Successor "FFFFFFFFh";
BA_ "FlexKomSigStartPos" SG_ 1082 NM_Successor 7;
BA_ "FlexKomSigName" SG_ 1082 NM_Successor "NM";
BA_ "FlexKomSigLaenge" SG_ 1082 NM_Successor 32;
BA_ "FlexKomSID" SG_ 1082 NM_Successor 472;
BA_ "FlexKomIsMotorola" SG_ 1082 NM_Successor 1;
BA_ "FlexKomComment" SG_ 1082 NM_Successor "Network management state";
BA_ "GenSigStartValue" SG_ 1082 NM_Ud_Launch 63;
BA_ "GenSigSNA" SG_ 1082 NM_Ud_Launch "3Fh";
BA_ "GenSigSendType" SG_ 1082 NM_Ud_Launch 1;
BA_ "FlexKomSigStartValue" SG_ 1082 NM_Ud_Launch "FFFFFFFFh";
BA_ "FlexKomSigStartPos" SG_ 1082 NM_Ud_Launch 7;
BA_ "FlexKomSigName" SG_ 1082 NM_Ud_Launch "NM";
BA_ "FlexKomSigLaenge" SG_ 1082 NM_Ud_Launch 32;
BA_ "FlexKomSID" SG_ 1082 NM_Ud_Launch 472;
BA_ "FlexKomIsMotorola" SG_ 1082 NM_Ud_Launch 1;
BA_ "FlexKomComment" SG_ 1082 NM_Ud_Launch "Network management state";
BA_ "GenSigStartValue" SG_ 1082 NM_Ud_Srv 255;
BA_ "GenSigSNA" SG_ 1082 NM_Ud_Srv "FFh";
BA_ "GenSigSendType" SG_ 1082 NM_Ud_Srv 1;
BA_ "FlexKomSigStartValue" SG_ 1082 NM_Ud_Srv "FFFFFFFFh";
BA_ "FlexKomSigStartPos" SG_ 1082 NM_Ud_Srv 7;
BA_ "FlexKomSigName" SG_ 1082 NM_Ud_Srv "NM";
BA_ "FlexKomSigLaenge" SG_ 1082 NM_Ud_Srv 32;
BA_ "FlexKomSID" SG_ 1082 NM_Ud_Srv 472;
BA_ "FlexKomIsMotorola" SG_ 1082 NM_Ud_Srv 1;
BA_ "FlexKomComment" SG_ 1082 NM_Ud_Srv "Network management state";
BA_ "GenSigStartValue" SG_ 1082 Nw_Id 255;
BA_ "GenSigSNA" SG_ 1082 Nw_Id "FFh";
BA_ "GenSigSendType" SG_ 1082 Nw_Id 1;
BA_ "FlexKomSigStartValue" SG_ 1082 Nw_Id "FFh";
BA_ "FlexKomSigStartPos" SG_ 1082 Nw_Id 63;
BA_ "FlexKomSigName" SG_ 1082 Nw_Id "Nw_Id";
BA_ "FlexKomSigLaenge" SG_ 1082 Nw_Id 8;
BA_ "FlexKomSID" SG_ 1082 Nw_Id 535;
BA_ "FlexKomIsMotorola" SG_ 1082 Nw_Id 1;
BA_ "FlexKomComment" SG_ 1082 Nw_Id "Network identification no.";
BA_ "GenSigStartValue" SG_ 1082 WakeupCnt 255;
BA_ "GenSigSNA" SG_ 1082 WakeupCnt "FFh";
BA_ "GenSigSendType" SG_ 1082 WakeupCnt 1;
BA_ "FlexKomSigStartValue" SG_ 1082 WakeupCnt "FFFF00h";
BA_ "FlexKomSigStartPos" SG_ 1082 WakeupCnt 39;
BA_ "FlexKomSigName" SG_ 1082 WakeupCnt "Wakeup_HCP";
BA_ "FlexKomSigLaenge" SG_ 1082 WakeupCnt 24;
BA_ "FlexKomSID" SG_ 1082 WakeupCnt 2123;
BA_ "FlexKomIsMotorola" SG_ 1082 WakeupCnt 1;
BA_ "FlexKomComment" SG_ 1082 WakeupCnt "Mode 2 of NM_Ud_Srv";
BA_ "GenSigStartValue" SG_ 1082 WakeupRsn_HCP 255;
BA_ "GenSigSNA" SG_ 1082 WakeupRsn_HCP "FFh";
BA_ "GenSigSendType" SG_ 1082 WakeupRsn_HCP 1;
BA_ "FlexKomSigStartValue" SG_ 1082 WakeupRsn_HCP "FFFF00h";
BA_ "FlexKomSigStartPos" SG_ 1082 WakeupRsn_HCP 39;
BA_ "FlexKomSigName" SG_ 1082 WakeupRsn_HCP "Wakeup_HCP";
BA_ "FlexKomSigLaenge" SG_ 1082 WakeupRsn_HCP 24;
BA_ "FlexKomSID" SG_ 1082 WakeupRsn_HCP 2123;
BA_ "FlexKomIsMotorola" SG_ 1082 WakeupRsn_HCP 1;
BA_ "FlexKomComment" SG_ 1082 WakeupRsn_HCP "Mode 2 of NM_Ud_Srv";
VAL_ 943 B_Total_Dist_Kilometers 16777215 "SNA" ;
VAL_ 943 B_Total_Dist_Miles 16777215 "SNA" ;
VAL_ 958 Electric_Dist_Miles 1023 "SNA" ;
VAL_ 958 Hybrid_Dist_Miles 1023 "SNA" ;
VAL_ 959 Electric_Dist_Kilometers 1023 "SNA" ;
VAL_ 959 Hybrid_Dist_Kilometers 1023 "SNA" ;
VAL_ 517 ControlEncodingRq 5 "ControlEncoding_ENQ" 6 "ControlEncoding_ACK" 21 "ControlEncoding_NACK" 129 "ControlEncoding_NACKp" 132 "ControlEncoding_EOTp" 133 "ControlEncoding_ENQp" 134 "ControlEncoding_ACK1p" 135 "ControlEncoding_ACK2p" ;
VAL_ 515 ControlEncodingRq 5 "ControlEncoding_ENQ" 6 "ControlEncoding_ACK" 21 "ControlEncoding_NACK" 129 "ControlEncoding_NACKp" 132 "ControlEncoding_EOTp" 133 "ControlEncoding_ENQp" 134 "ControlEncoding_ACK1p" 135 "ControlEncoding_ACK2p" ;
VAL_ 516 ControlEncodingRsp 16 "ControlEncoding_TEN" 153 "ControlEncoding_UC" 170 "ControlEncoding_PRA" 171 "ControlEncoding_PVA" ;
VAL_ 518 ControlEncoding_Rsp 16 "ControlEncoding_TEN" 153 "ControlEncoding_UC" 170 "ControlEncoding_PRA" 171 "ControlEncoding_PVA" ;
VAL_ 973 ABS_IND_STAT 0 "OFF" 1 "CONT" 2 "BLINK" 3 "SNA" ;
VAL_ 973 AWD_SERVICE_STAT 0 "OFF" 1 "CONT" 2 "BLINK" 3 "SNA" ;
VAL_ 973 BATTERY_CHARGE_STAT 0 "OFF" 1 "CONT" 2 "BLINK" 3 "SNA" ;
VAL_ 973 BRAKE_PAD_STAT 0 "OFF" 1 "CONT" 2 "BLINK" 3 "SNA" ;
VAL_ 973 BRK_IND_STAT 0 "OFF" 1 "CONT" 2 "BLINK" 3 "SNA" ;
VAL_ 973 CATALYST_TEMP_STAT 0 "OFF" 1 "CONT" 2 "BLINK" 3 "SNA" ;
VAL_ 973 COOLENT_LEVEL_STAT 0 "OFF" 1 "CONT" 2 "BLINK" 3 "SNA" ;
VAL_ 973 DAMPING_SYSTEM_STAT 0 "OFF" 1 "CONT" 2 "BLINK" 3 "SNA" ;
VAL_ 973 DEF_STAT 0 "OFF" 1 "CONT" 2 "BLINK" 3 "SNA" ;
VAL_ 973 ELECTRIC_WRENCH_STAT 0 "OFF" 1 "CONT" 2 "BLINK" 3 "SNA" ;
VAL_ 973 ELEC_STAB_STAT 0 "OFF" 1 "CONT" 2 "BLINK" 3 "SNA" ;
VAL_ 973 ENGINE_MIL_STAT 0 "OFF" 1 "CONT" 2 "BLINK" 3 "SNA" ;
VAL_ 973 ENGINE_TEMP_STAT 0 "OFF" 1 "CONT" 2 "BLINK" 3 "SNA" ;
VAL_ 973 EPB_WARN_STAT 0 "OFF" 1 "CONT" 2 "BLINK" 3 "SNA" ;
VAL_ 973 EPS_STAT 0 "OFF" 1 "CONT" 2 "BLINK" 3 "SNA" ;
VAL_ 973 ETC_CONTROL_STAT 0 "OFF" 1 "CONT" 2 "BLINK" 3 "SNA" ;
VAL_ 973 FCW_SYSTEM_STAT 0 "OFF" 1 "CONT" 2 "BLINK" 3 "SNA" ;
VAL_ 973 FOUR_WD_SERVICE_STAT 0 "OFF" 1 "CONT" 2 "BLINK" 3 "SNA" ;
VAL_ 973 FUEL_CAP_STAT 0 "OFF" 1 "CONT" 2 "BLINK" 3 "SNA" ;
VAL_ 973 LANE_SENSE_STAT 0 "OFF" 1 "CONT" 2 "BLINK" 3 "SNA" ;
VAL_ 973 OIL_LEVEL_STAT 0 "OFF" 1 "CONT" 2 "BLINK" 3 "SNA" ;
VAL_ 973 OIL_PRESSURE_STAT 0 "OFF" 1 "CONT" 2 "BLINK" 3 "SNA" ;
VAL_ 973 OIL_TEMP_STAT 0 "OFF" 1 "CONT" 2 "BLINK" 3 "SNA" ;
VAL_ 973 OVER_TEMP_STAT 0 "OFF" 1 "CONT" 2 "BLINK" 3 "SNA" ;
VAL_ 973 SERVICE_ACC_STAT 0 "OFF" 1 "CONT" 2 "BLINK" 3 "SNA" ;
VAL_ 973 SERVICE_STAT 0 "OFF" 1 "CONT" 2 "BLINK" 3 "SNA" ;
VAL_ 973 STOP_START_STAT 0 "OFF" 1 "CONT" 2 "BLINK" 3 "SNA" ;
VAL_ 973 TIRE_PRESSURE_STAT 0 "OFF" 1 "CONT" 2 "BLINK" 3 "SNA" ;
VAL_ 973 TORQUE_STAT 0 "OFF" 1 "CONT" 2 "BLINK" 3 "SNA" ;
VAL_ 973 WATER_IN_FUEL_STAT 0 "OFF" 1 "CONT" 2 "BLINK" 3 "SNA" ;
VAL_ 973 WINDSHIELD_FLUID_STAT 0 "OFF" 1 "CONT" 2 "BLINK" 3 "SNA" ;
VAL_ 956 NAV_GrpTyp 0 "NO_TEXT" 63 "SNA" ;
VAL_ 926 NET_CFG_STAT_ePT 0 "NA" 1 "PROGRAMMED" 2 "REQUEST_DATA" 3 "SNA" ;
VAL_ 926 NetCfg_BSMO_ePT 0 "Not_Present" 1 "Present" ;
VAL_ 995 NET_CFG_STAT_INT 0 "NA" 1 "PROGAMMED" 2 "REQUEST_DATA" 3 "SNA" ;
VAL_ 995 NetCfg_ANC_I 0 "Not_Present" 1 "Present" ;
VAL_ 995 NetCfg_TTM 0 "Not_Present" 1 "Present" ;
VAL_ 996 NET_CFG_STAT_PT 0 "NA" 1 "PROGAMMED" 2 "REQUEST_DATA" 3 "SNA" ;
VAL_ 996 NetCfg_ASBS 0 "Not_Present" 1 "Present" ;
VAL_ 996 NetCfg_BSMO 0 "Not_Present" 1 "Present" ;
VAL_ 996 NetCfg_DPDM 0 "Not_Present" 1 "Present" ;
VAL_ 996 NetCfg_GPF 0 "Not_Present" 1 "Present" ;
VAL_ 996 NetCfg_SGW 0 "Not_Present" 1 "Present" ;
VAL_ 1025 NM_Mode 252 "LHOM" 253 "RING" 254 "ALIVE" 255 "SNA" ;
VAL_ 1025 NM_Successor 255 "SNA" ;
VAL_ 1025 NM_Ud_Launch 4 "BROADCAST" 63 "SNA" ;
VAL_ 1025 NM_Ud_Srv 2 "WAKEUP_SA" 15 "AWAKE_BC" 255 "NO_USER_DATA" ;
VAL_ 1025 Nw_Id 0 "POWERTRAIN" 1 "BODY" 2 "AUDIO_TELE" 255 "SNA" ;
VAL_ 1025 WakeupCnt 255 "SNA" ;
VAL_ 1025 WakeupRsn_CBC 0 "NETWORK" 1 "CAN_C" 2 "CAN_I" 3 "LIN_ONE" 4 "LIN_TWO" 5 "LIN_THREE" 6 "DRV_AJAR" 7 "PSG_AJAR" 8 "L_R_AJAR" 9 "R_R_AJAR" 10 "TLG_AJAR" 11 "FG_AJAR" 12 "HOOD_AJAR" 13 "HRD_TOP_STEALTH" 14 "TK_FG_SW" 15 "DRV_LK_SW" 16 "PASS_LK_SW" 17 "HAZARD_SW" 18 "SS_SW" 19 "BRK_SW" 20 "HL_SW" 21 "PD_SW" 22 "CARGO_SW" 23 "CON_LAMP_LD" 24 "REFUEL" 25 "ELCM" 255 "SNA" ;
VAL_ 1050 NM_Mode 252 "LHOM" 253 "RING" 254 "ALIVE" 255 "SNA" ;
VAL_ 1050 NM_Successor 255 "SNA" ;
VAL_ 1050 NM_Ud_Launch 4 "BROADCAST" 63 "SNA" ;
VAL_ 1050 NM_Ud_Srv 2 "WAKEUP_SA" 15 "AWAKE_BC" 255 "NO_USER_DATA" ;
VAL_ 1050 Nw_Id 0 "POWERTRAIN" 1 "BODY" 2 "AUDIO_TELE" 255 "SNA" ;
VAL_ 1050 WakeupCnt 255 "SNA" ;
VAL_ 1050 WakeupRsn_EPS 0 "NETWORK" 1 "IGN" 255 "SNA" ;
VAL_ 1031 NM_Mode 252 "LHOM" 253 "RING" 254 "ALIVE" 255 "SNA" ;
VAL_ 1031 NM_Successor 255 "SNA" ;
VAL_ 1031 NM_Ud_Launch 4 "BROADCAST" 63 "SNA" ;
VAL_ 1031 NM_Ud_Srv 2 "WAKEUP_SA" 15 "AWAKE_BC" 255 "NO_USER_DATA" ;
VAL_ 1031 Nw_Id 0 "POWERTRAIN" 1 "BODY" 2 "AUDIO_TELE" 255 "SNA" ;
VAL_ 1031 WakeupCnt 255 "SNA" ;
VAL_ 1031 WakeupRsn_ESC 0 "NETWORK" 1 "BP" 2 "VEH_SPD" 3 "RA_RECLAMP" 4 "T_RECLAMP" 5 "SWU" 6 "DIAG" 7 "IGN" 255 "SNA" ;
VAL_ 1032 NM_Mode 252 "LHOM" 253 "RING" 254 "ALIVE" 255 "SNA" ;
VAL_ 1032 NM_Successor 255 "SNA" ;
VAL_ 1032 NM_Ud_Launch 4 "BROADCAST" 63 "SNA" ;
VAL_ 1032 NM_Ud_Srv 2 "WAKEUP_SA" 15 "AWAKE_BC" 255 "NO_USER_DATA" ;
VAL_ 1032 Nw_Id 0 "POWERTRAIN" 1 "BODY" 2 "AUDIO_TELE" 255 "SNA" ;
VAL_ 1032 WakeupCnt 255 "SNA" ;
VAL_ 1032 WakeupRsn_ESL 0 "NETWORK" 255 "SNA" ;
VAL_ 1082 NM_Mode 252 "LHOM" 253 "RING" 254 "ALIVE" 255 "SNA" ;
VAL_ 1082 NM_Successor 255 "SNA" ;
VAL_ 1082 NM_Ud_Launch 4 "BROADCAST" 63 "SNA" ;
VAL_ 1082 NM_Ud_Srv 2 "WAKEUP_SA" 15 "AWAKE_BC" 255 "NO_USER_DATA" ;
VAL_ 1082 Nw_Id 0 "POWERTRAIN" 1 "BODY" 2 "AUDIO_TELE" 255 "SNA" ;
VAL_ 1082 WakeupCnt 255 "SNA" ;
VAL_ 1082 WakeupRsn_HCP 0 "NETWORK" 1 "CBC_WU" 2 "IGN_WU" 3 "OBCM_WU" 255 "SNA" ;
